VERSION "V6.0.0"

NS_ :

BS_:

BU_: OBD_Node CGW_PT POD BMS TCU APTC VCU MCU PRND EVCOM IBS_PT ADCU_PT

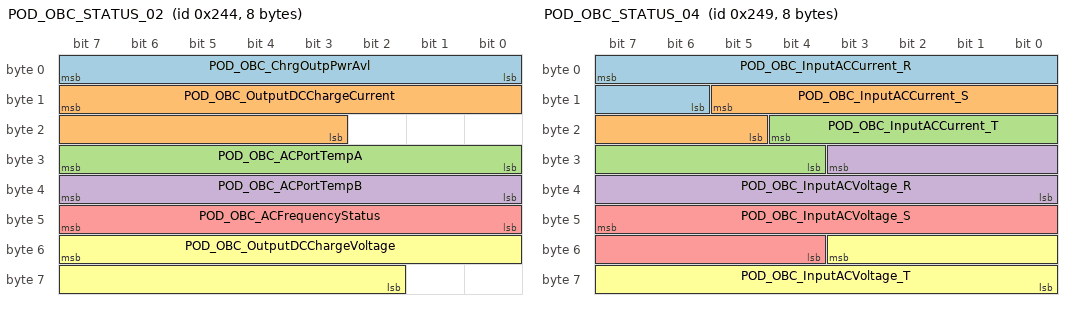
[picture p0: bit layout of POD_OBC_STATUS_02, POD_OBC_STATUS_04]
BO_ 580 POD_OBC_STATUS_02: 8 POD
 SG_ POD_OBC_ChrgOutpPwrAvl : 7|8@0+ (0.1,-7) [-7|13] "kW"  VCU,CGW_PT
 SG_ POD_OBC_OutputDCChargeCurrent : 15|13@0+ (0.1,-250) [-250|250] "A"  VCU,CGW_PT
 SG_ POD_OBC_ACPortTempA : 31|8@0+ (1,-40) [-40|215] "celsius"  CGW_PT
 SG_ POD_OBC_ACPortTempB : 39|8@0+ (1,-40) [-40|215] "celsius"  CGW_PT
 SG_ POD_OBC_ACFrequencyStatus : 47|8@0+ (1,0) [0|255] "Hz"  CGW_PT
 SG_ POD_OBC_OutputDCChargeVoltage : 55|14@0+ (0.1,-800) [-800|800] "V"  VCU,CGW_PT

BO_ 787 POD_OBC_STATUS_03: 8 POD
 SG_ POD_OBC_ACPortTempASensValid : 7|2@0+ (1,0) [0|2] ""  CGW_PT
 SG_ POD_OBC_ACPortTempBSensValid : 5|2@0+ (1,0) [0|2] ""  CGW_PT
 SG_ POD_OBC_ACPortTempAerror : 3|1@0+ (1,0) [0|1] ""  CGW_PT
 SG_ POD_OBC_ACPortTempBerror : 2|1@0+ (1,0) [0|1] ""  CGW_PT
 SG_ POD_OBC_FaultLevel : 1|2@0+ (1,0) [0|3] ""  VCU,CGW_PT
 SG_ POD_OBC_DCVoltHighFault : 15|1@0+ (1,0) [0|1] ""  CGW_PT
 SG_ POD_OBC_StartUpAllowed : 14|1@0+ (1,0) [0|1] ""  CGW_PT
 SG_ POD_OBC_CommunFault : 13|1@0+ (1,0) [0|1] ""  CGW_PT
 SG_ POD_OBC_DCCurHighFault : 12|1@0+ (1,0) [0|1] ""  CGW_PT
 SG_ POD_OBC_ACVoltHighFault : 11|1@0+ (1,0) [0|1] ""  CGW_PT
 SG_ POD_OBC_ACVoltLowFault : 10|1@0+ (1,0) [0|1] ""  CGW_PT
 SG_ POD_OBC_NlineStatus : 9|1@0+ (1,0) [0|1] ""  CGW_PT
 SG_ POD_OBC_OutputoverloadFault : 8|1@0+ (1,0) [0|1] ""  CGW_PT
 SG_ POD_OBC_InputFrequencyStatus : 23|1@0+ (1,0) [0|1] ""  CGW_PT
 SG_ POD_OBC_InputPhaseStatus : 22|1@0+ (1,0) [0|1] ""  CGW_PT
 SG_ POD_OBC_InputOverCurrentstatus_R : 21|1@0+ (1,0) [0|1] ""  CGW_PT
 SG_ POD_OBC_InputOverCurrentstatus_S : 20|1@0+ (1,0) [0|1] ""  CGW_PT
 SG_ POD_OBC_InputOverCurrentstatus_T : 19|1@0+ (1,0) [0|1] ""  CGW_PT
 SG_ POD_OBC_PFCUnderVoltageError : 18|1@0+ (1,0) [0|1] ""  CGW_PT
 SG_ POD_OBC_PFCOverVoltageError : 17|1@0+ (1,0) [0|1] ""  CGW_PT
 SG_ POD_OBC_OutputShortError : 16|1@0+ (1,0) [0|1] ""  CGW_PT
 SG_ POD_OBC_Side1Overtempfault : 31|1@0+ (1,0) [0|1] ""  VCU,CGW_PT
 SG_ POD_OBC_Side2Overtempfault : 30|1@0+ (1,0) [0|1] ""  VCU,CGW_PT
 SG_ POD_OBC_InternalFault : 27|1@0+ (1,0) [0|1] ""  CGW_PT
 SG_ POD_OBC_DCVoltLowFault : 28|1@0+ (1,0) [0|1] ""  CGW_PT
 SG_ POD_OBC_InputShortError : 26|1@0+ (1,0) [0|1] ""  CGW_PT
 SG_ POD_DCDC_CommunFault : 25|1@0+ (1,0) [0|1] ""  CGW_PT
 SG_ OBC_OutputIsolatedFault : 24|1@0+ (1,0) [0|1] ""  CGW_PT
 SG_ POD_OBC_PrimarySideTemp : 39|8@0+ (1,-40) [-40|210] "celsius"  TCU,VCU,CGW_PT
 SG_ POD_OBC_SecondarySideTemp : 47|8@0+ (1,-40) [-40|210] "celsius"  TCU,VCU,CGW_PT

BO_ 585 POD_OBC_STATUS_04: 8 POD
 SG_ POD_OBC_InputACCurrent_R : 7|10@0+ (0.1,-50) [-50|50] ""  VCU,CGW_PT
 SG_ POD_OBC_InputACCurrent_S : 13|9@0+ (0.1,0) [0|50] ""  VCU,CGW_PT
 SG_ POD_OBC_InputACCurrent_T : 20|9@0+ (0.1,0) [0|50] ""  VCU,CGW_PT
 SG_ POD_OBC_InputACVoltage_R : 27|12@0+ (0.1,0) [0|400] ""  VCU,CGW_PT
 SG_ POD_OBC_InputACVoltage_S : 47|12@0+ (0.1,0) [0|400] "V"  VCU,CGW_PT
 SG_ POD_OBC_InputACVoltage_T : 51|12@0+ (0.1,0) [0|400] "V"  VCU,CGW_PT

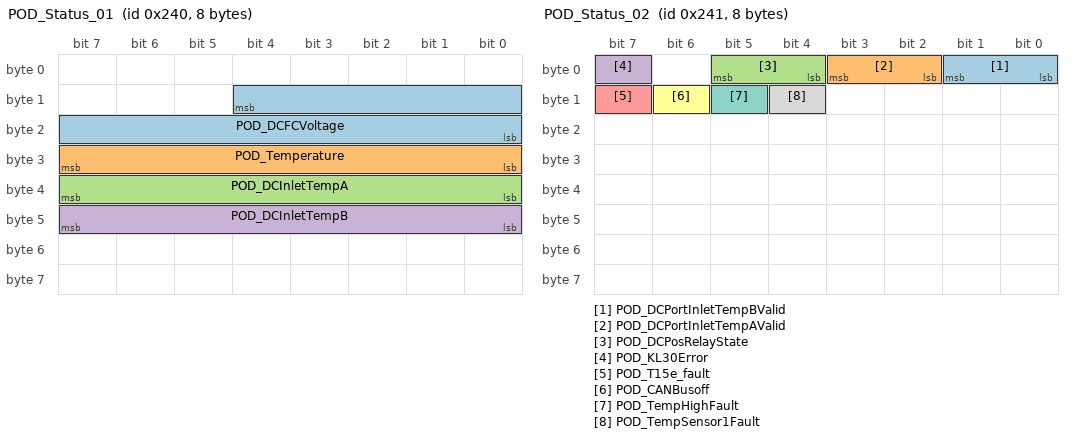
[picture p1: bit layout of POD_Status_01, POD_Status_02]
BO_ 576 POD_Status_01: 8 POD
 SG_ POD_DCFCVoltage : 12|13@0+ (0.1,0) [0|819] "V"  VCU,CGW_PT
 SG_ POD_Temperature : 31|8@0+ (1,-40) [-40|215] "celsius"  TCU,CGW_PT
 SG_ POD_DCInletTempA : 39|8@0+ (1,-40) [-40|215] "celsius"  VCU,CGW_PT
 SG_ POD_DCInletTempB : 47|8@0+ (1,-40) [-40|215] "celsius"  VCU,CGW_PT

BO_ 577 POD_Status_02: 8 POD
 SG_ POD_DCPortInletTempBValid : 1|2@0+ (1,0) [0|2] ""  VCU,CGW_PT
 SG_ POD_DCPortInletTempAValid : 3|2@0+ (1,0) [0|2] ""  VCU,CGW_PT
 SG_ POD_DCPosRelayState : 5|2@0+ (1,0) [0|2] ""  VCU,CGW_PT
 SG_ POD_KL30Error : 7|1@0+ (1,0) [0|1] ""  CGW_PT
 SG_ POD_T15e_fault : 15|1@0+ (1,0) [0|1] ""  CGW_PT
 SG_ POD_CANBusoff : 14|1@0+ (1,0) [0|1] ""  CGW_PT
 SG_ POD_TempHighFault : 13|1@0+ (1,0) [0|1] ""  CGW_PT
 SG_ POD_TempSensor1Fault : 12|1@0+ (1,0) [0|1] ""  CGW_PT

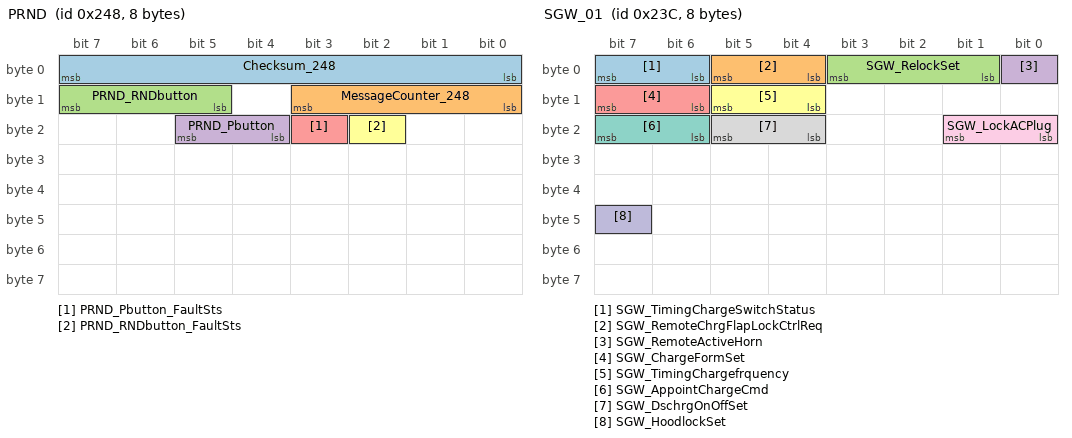
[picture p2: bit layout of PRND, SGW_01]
BO_ 584 PRND: 8 PRND
 SG_ Checksum_248 : 7|8@0+ (1,0) [0|255] ""  VCU,IBS_PT,CGW_PT
 SG_ MessageCounter_248 : 11|4@0+ (1,0) [0|15] ""  VCU,IBS_PT,CGW_PT
 SG_ PRND_RNDbutton : 15|3@0+ (1,0) [0|7] ""  VCU,CGW_PT
 SG_ PRND_Pbutton : 21|2@0+ (1,0) [0|3] ""  VCU,IBS_PT,CGW_PT
 SG_ PRND_Pbutton_FaultSts : 19|1@0+ (1,0) [0|1] ""  VCU,IBS_PT,CGW_PT
 SG_ PRND_RNDbutton_FaultSts : 18|1@0+ (1,0) [0|1] ""  VCU,CGW_PT

BO_ 572 SGW_01: 8 CGW_PT
 SG_ SGW_TimingChargeSwitchStatus : 7|2@0+ (1,0) [0|2] ""  VCU,BMS
 SG_ SGW_RemoteChrgFlapLockCtrlReq : 5|2@0+ (1,0) [0|3] "" Vector__XXX
 SG_ SGW_RelockSet : 3|3@0+ (1,0) [0|5] "" Vector__XXX
 SG_ SGW_RemoteActiveHorn : 0|1@0+ (1,0) [0|1] "" Vector__XXX
 SG_ SGW_ChargeFormSet : 15|2@0+ (1,0) [0|2] ""  VCU
 SG_ SGW_TimingChargefrquency : 13|2@0+ (1,0) [0|2] "" Vector__XXX
 SG_ SGW_AppointChargeCmd : 23|2@0+ (1,0) [0|2] ""  VCU
 SG_ SGW_DschrgOnOffSet : 21|2@0+ (1,0) [0|3] ""  VCU
 SG_ SGW_LockACPlug : 17|2@0+ (1,0) [0|2] ""  VCU
 SG_ SGW_HoodlockSet : 47|1@0+ (1,0) [0|1] "" Vector__XXX

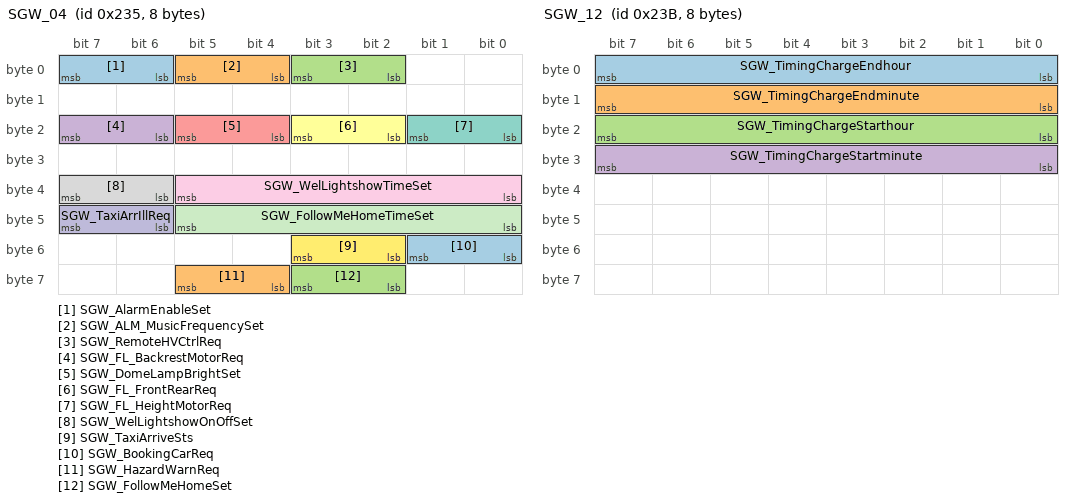
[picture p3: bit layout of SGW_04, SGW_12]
BO_ 565 SGW_04: 8 CGW_PT
 SG_ SGW_AlarmEnableSet : 7|2@0+ (1,0) [0|2] "" Vector__XXX
 SG_ SGW_ALM_MusicFrequencySet : 5|2@0+ (1,0) [0|3] "" Vector__XXX
 SG_ SGW_RemoteHVCtrlReq : 3|2@0+ (1,0) [0|2] ""  VCU
 SG_ SGW_FL_BackrestMotorReq : 23|2@0+ (1,0) [0|2] "" Vector__XXX
 SG_ SGW_DomeLampBrightSet : 21|2@0+ (1,0) [0|2] "" Vector__XXX
 SG_ SGW_FL_FrontRearReq : 19|2@0+ (1,0) [0|2] "" Vector__XXX
 SG_ SGW_FL_HeightMotorReq : 17|2@0+ (1,0) [0|2] "" Vector__XXX
 SG_ SGW_WelLightshowOnOffSet : 39|2@0+ (1,0) [0|3] "" Vector__XXX
 SG_ SGW_WelLightshowTimeSet : 37|6@0+ (5,5) [5|180] "s" Vector__XXX
 SG_ SGW_TaxiArrIllReq : 47|2@0+ (1,0) [0|3] "" Vector__XXX
 SG_ SGW_FollowMeHomeTimeSet : 45|6@0+ (5,5) [5|180] "s" Vector__XXX
 SG_ SGW_TaxiArriveSts : 51|2@0+ (1,0) [0|2] "" Vector__XXX
 SG_ SGW_BookingCarReq : 49|2@0+ (1,0) [0|2] "" Vector__XXX
 SG_ SGW_HazardWarnReq : 61|2@0+ (1,0) [0|2] "" Vector__XXX
 SG_ SGW_FollowMeHomeSet : 59|2@0+ (1,0) [0|3] "" Vector__XXX

BO_ 571 SGW_12: 8 CGW_PT
 SG_ SGW_TimingChargeEndhour : 7|8@0+ (1,0) [0|31] "h"  BMS
 SG_ SGW_TimingChargeEndminute : 15|8@0+ (1,0) [0|63] "min"  BMS
 SG_ SGW_TimingChargeStarthour : 23|8@0+ (1,0) [0|31] "h" Vector__XXX
 SG_ SGW_TimingChargeStartminute : 31|8@0+ (1,0) [0|63] "min" Vector__XXX

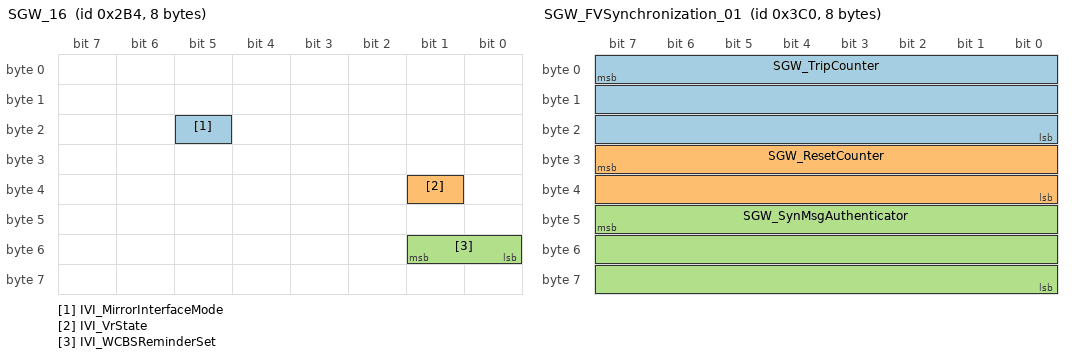
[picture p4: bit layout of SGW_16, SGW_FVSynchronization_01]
BO_ 692 SGW_16: 8 CGW_PT
 SG_ IVI_MirrorInterfaceMode : 21|1@0+ (1,0) [0|1] "" Vector__XXX
 SG_ IVI_VrState : 33|1@0+ (1,0) [0|1] ""  VCU
 SG_ IVI_WCBSReminderSet : 49|2@0+ (1,0) [0|2] "" Vector__XXX

BO_ 960 SGW_FVSynchronization_01: 8 CGW_PT
 SG_ SGW_TripCounter : 7|24@0+ (1,0) [0|16777215] ""  VCU
 SG_ SGW_ResetCounter : 31|16@0+ (1,0) [0|65535] ""  VCU
 SG_ SGW_SynMsgAuthenticator : 47|24@0+ (1,0) [0|16777215] ""  VCU

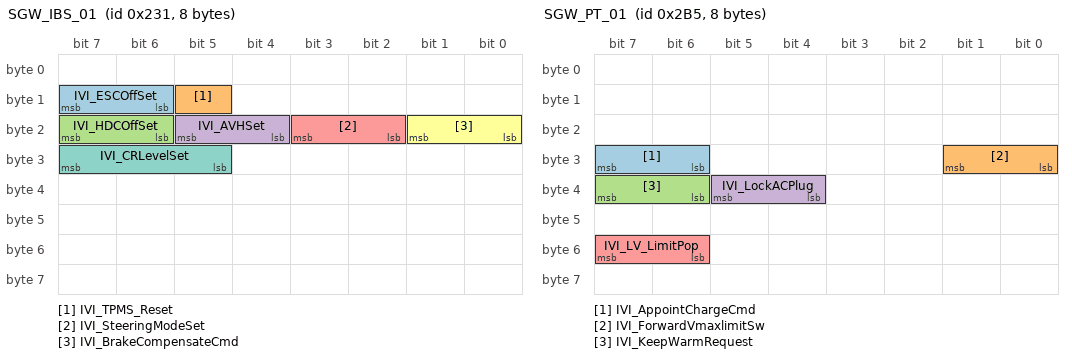
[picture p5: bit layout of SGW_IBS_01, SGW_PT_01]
BO_ 561 SGW_IBS_01: 8 CGW_PT
 SG_ IVI_ESCOffSet : 15|2@0+ (1,0) [0|3] "" Vector__XXX
 SG_ IVI_TPMS_Reset : 13|1@0+ (1,0) [0|1] "" Vector__XXX
 SG_ IVI_HDCOffSet : 23|2@0+ (1,0) [0|3] "" Vector__XXX
 SG_ IVI_AVHSet : 21|2@0+ (1,0) [0|3] "" Vector__XXX
 SG_ IVI_SteeringModeSet : 19|2@0+ (1,0) [0|3] "" Vector__XXX
 SG_ IVI_BrakeCompensateCmd : 17|2@0+ (1,0) [0|3] ""  VCU
 SG_ IVI_CRLevelSet : 31|3@0+ (1,0) [0|7] ""  VCU

BO_ 944 IVI_OdometerInfor: 8 CGW_PT
 SG_ IVI_OdometerInfor : 7|24@0+ (0.1,0) [0|999999.9] "km"  TCU,APTC,VCU,MCU,PRND,EVCOM,POD,BMS
 SG_ IVI_OdometerInforValid : 31|1@0+ (1,0) [0|1] "" Vector__XXX

BO_ 693 SGW_PT_01: 8 CGW_PT
 SG_ IVI_AppointChargeCmd : 31|2@0+ (1,0) [0|2] ""  VCU
 SG_ IVI_ForwardVmaxlimitSw : 25|2@0+ (1,0) [0|3] ""  VCU
 SG_ IVI_KeepWarmRequest : 39|2@0+ (1,0) [0|2] ""  BMS
 SG_ IVI_LockACPlug : 37|2@0+ (1,0) [0|2] ""  VCU
 SG_ IVI_LV_LimitPop : 55|2@0+ (1,0) [0|2] ""  VCU

BO_ 694 IVI_01: 8 CGW_PT
 SG_ IVI_GearRequest : 15|3@0+ (1,0) [0|5] ""  VCU

BO_ 261 SGW_RemoteCmd_01: 8 CGW_PT
 SG_ SGW_RemoteAirCondOnOFFReq : 15|2@0+ (1,0) [0|3] ""  TCU
 SG_ SGW_RemoteAirCondAUTOReq : 13|2@0+ (1,0) [0|3] ""  TCU
 SG_ SGW_RemoteFrontDefrostReq : 23|2@0+ (1,0) [0|3] ""  TCU
 SG_ SGW_FrontDoorAngleSet : 21|2@0+ (1,0) [0|2] "" Vector__XXX
 SG_ SGW_RearDoorAngleSet : 19|2@0+ (1,0) [0|2] "" Vector__XXX
 SG_ SGW_RemoteDrSeatHeatReq : 28|3@0+ (1,0) [0|4] "" Vector__XXX
 SG_ SGW_RemoteSteerHeatReq : 25|2@0+ (1,0) [0|3] "" Vector__XXX
 SG_ SGW_RemotePassSeatHeatReq : 39|3@0+ (1,0) [0|4] "" Vector__XXX
 SG_ SGW_RearDefrostCtrlSet : 32|1@0+ (1,0) [0|1] "" Vector__XXX
 SG_ SGW_RemoteRearMirHeatReq : 36|2@0+ (1,0) [0|3] "" Vector__XXX
 SG_ SGW_RemoteFrontWindHeatReq : 34|2@0+ (1,0) [0|3] "" Vector__XXX
 SG_ SGW_RemoteRearWindHeatReq : 47|2@0+ (1,0) [0|3] "" Vector__XXX
 SG_ SGW_oneTouchCoolSet : 43|2@0+ (1,0) [0|2] "" Vector__XXX
 SG_ SGW_TakePicCtrl : 51|3@0+ (1,0) [0|7] "" Vector__XXX
 SG_ SGW_RemoteTailgateLockCtrlReq : 63|2@0+ (1,0) [0|3] "" Vector__XXX
 SG_ SGW_RemoteACOnOffReq : 57|2@0+ (1,0) [0|2] ""  TCU
 SG_ SGW_LeftChdLockCtrlReq : 31|2@0+ (1,0) [0|2] "" Vector__XXX
 SG_ SGW_RightChdLockCtrlReq : 59|2@0+ (1,0) [0|2] "" Vector__XXX

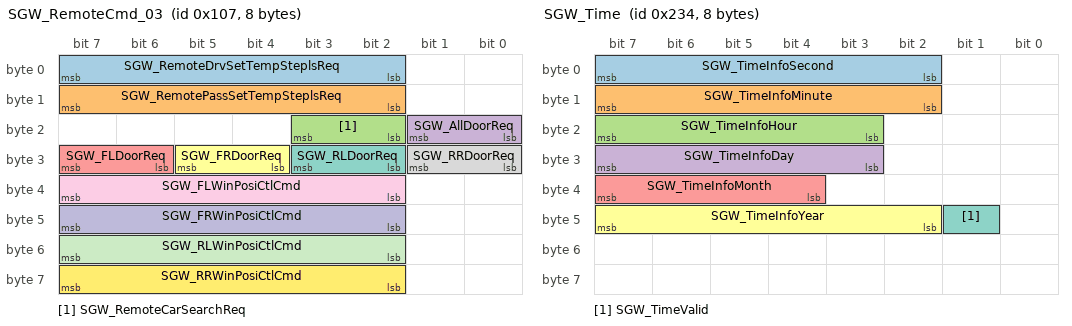
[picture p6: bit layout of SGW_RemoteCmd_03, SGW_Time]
BO_ 263 SGW_RemoteCmd_03: 8 CGW_PT
 SG_ SGW_RemoteDrvSetTempSteplsReq : 7|6@0+ (1,0) [0|63] ""  TCU
 SG_ SGW_RemotePassSetTempSteplsReq : 15|6@0+ (1,0) [0|63] ""  TCU
 SG_ SGW_RemoteCarSearchReq : 19|2@0+ (1,0) [0|3] "" Vector__XXX
 SG_ SGW_AllDoorReq : 17|2@0+ (1,0) [0|2] "" Vector__XXX
 SG_ SGW_FLDoorReq : 31|2@0+ (1,0) [0|2] "" Vector__XXX
 SG_ SGW_FRDoorReq : 29|2@0+ (1,0) [0|2] "" Vector__XXX
 SG_ SGW_RLDoorReq : 27|2@0+ (1,0) [0|2] "" Vector__XXX
 SG_ SGW_RRDoorReq : 25|2@0+ (1,0) [0|2] "" Vector__XXX
 SG_ SGW_FLWinPosiCtlCmd : 39|6@0+ (1,0) [0|21] "" Vector__XXX
 SG_ SGW_FRWinPosiCtlCmd : 47|6@0+ (1,0) [0|21] "" Vector__XXX
 SG_ SGW_RLWinPosiCtlCmd : 55|6@0+ (1,0) [0|21] "" Vector__XXX
 SG_ SGW_RRWinPosiCtlCmd : 63|6@0+ (1,0) [0|21] "" Vector__XXX

BO_ 562 SGW_TCU_01: 8 CGW_PT
 SG_ SGW_DrvSetTempSteplsReq : 7|6@0+ (1,0) [0|63] ""  TCU
 SG_ SGW_DemistReq : 1|2@0+ (1,0) [0|3] ""  TCU
 SG_ SGW_HVACBatterySaveModeSetReq : 15|2@0+ (1,0) [0|3] ""  TCU
 SG_ SGW_PassSetTempSteplsReq : 13|6@0+ (1,0) [0|63] ""  TCU
 SG_ SGW_AirCondAUTOReq : 23|2@0+ (1,0) [0|3] ""  TCU
 SG_ SGW_DualReq : 21|2@0+ (1,0) [0|3] ""  TCU
 SG_ SGW_AirDistributionModeReq : 19|3@0+ (1,0) [0|7] ""  TCU
 SG_ SGW_FrontDefrostReq : 16|2@0+ (1,0) [0|3] ""  TCU
 SG_ SGW_AqsReq : 39|2@0+ (1,0) [0|3] ""  TCU
 SG_ SGW_ClimateSystemStsReq : 35|2@0+ (1,0) [0|3] ""  TCU
 SG_ SGW_ACCmprStsReq : 33|2@0+ (1,0) [0|3] ""  TCU
 SG_ SGW_AirCirclnReq : 47|2@0+ (1,0) [0|3] ""  TCU
 SG_ SGW_BlowersteplsSpdReq : 43|4@0+ (1,0) [0|15] ""  TCU
 SG_ SGW_PresetModeEnable : 55|2@0+ (1,0) [0|2] ""  TCU
 SG_ SGW_PresetModeReq : 53|3@0+ (1,0) [0|7] ""  TCU
 SG_ SGW_VentilationModeReq : 50|2@0+ (1,0) [0|2] ""  TCU
 SG_ SGW_AirCondEcoSet : 60|2@0+ (1,0) [0|3] ""  TCU

BO_ 564 SGW_Time: 8 CGW_PT
 SG_ SGW_TimeInfoSecond : 7|6@0+ (1,0) [0|59] ""  TCU,APTC,VCU,MCU,PRND,EVCOM,POD,BMS
 SG_ SGW_TimeInfoMinute : 15|6@0+ (1,0) [0|59] ""  TCU,APTC,VCU,MCU,PRND,EVCOM,POD,BMS
 SG_ SGW_TimeInfoHour : 23|5@0+ (1,0) [0|23] ""  TCU,APTC,VCU,MCU,PRND,EVCOM,POD,BMS
 SG_ SGW_TimeInfoDay : 31|5@0+ (1,0) [1|31] ""  TCU,APTC,VCU,MCU,PRND,EVCOM,POD,BMS
 SG_ SGW_TimeInfoMonth : 39|4@0+ (1,0) [1|12] ""  TCU,APTC,VCU,MCU,PRND,EVCOM,POD,BMS
 SG_ SGW_TimeInfoYear : 47|6@0+ (1,2000) [2000|2059] ""  TCU,APTC,VCU,MCU,PRND,EVCOM,POD,BMS
 SG_ SGW_TimeValid : 41|1@0+ (1,0) [0|1] ""  TCU,APTC,VCU,MCU,PRND,EVCOM,POD,BMS

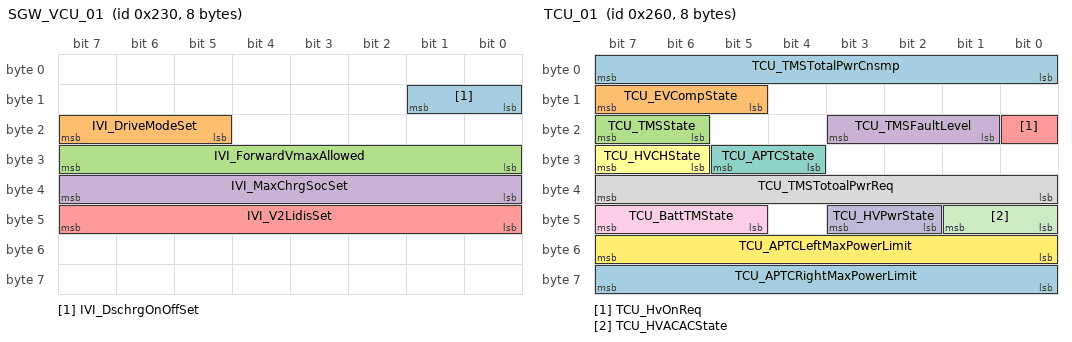
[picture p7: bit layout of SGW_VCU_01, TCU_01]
BO_ 560 SGW_VCU_01: 8 CGW_PT
 SG_ IVI_DschrgOnOffSet : 9|2@0+ (1,0) [0|3] ""  VCU
 SG_ IVI_DriveModeSet : 23|3@0+ (1,0) [0|4] ""  VCU
 SG_ IVI_ForwardVmaxAllowed : 31|8@0+ (1,0) [0|175] ""  VCU
 SG_ IVI_MaxChrgSocSet : 39|8@0+ (1,0) [0|100] "percent"  VCU
 SG_ IVI_V2LidisSet : 47|8@0+ (1,0) [0|100] "percent"  VCU

BO_ 608 TCU_01: 8 TCU
 SG_ TCU_TMSTotalPwrCnsmp : 7|8@0+ (200,0) [0|40000] "w"  VCU,CGW_PT
 SG_ TCU_EVCompState : 15|3@0+ (1,0) [0|7] ""  CGW_PT
 SG_ TCU_TMSState : 23|2@0+ (1,0) [0|2] ""  CGW_PT
 SG_ TCU_TMSFaultLevel : 19|3@0+ (1,0) [0|7] ""  VCU,CGW_PT
 SG_ TCU_HvOnReq : 16|1@0+ (1,0) [0|1] ""  CGW_PT
 SG_ TCU_HVCHState : 31|2@0+ (1,0) [0|3] ""  CGW_PT
 SG_ TCU_APTCState : 29|2@0+ (1,0) [0|3] ""  CGW_PT
 SG_ TCU_TMSTotoalPwrReq : 39|8@0+ (200,0) [0|40000] "w"  VCU,CGW_PT
 SG_ TCU_BattTMState : 47|3@0+ (1,0) [0|7] ""  CGW_PT
 SG_ TCU_HVPwrState : 43|2@0+ (1,0) [0|3] ""  VCU,CGW_PT
 SG_ TCU_HVACACState : 41|2@0+ (1,0) [0|3] ""  CGW_PT
 SG_ TCU_APTCLeftMaxPowerLimit : 55|8@0+ (0.04,0) [0|10.2] "KW"  APTC,CGW_PT
 SG_ TCU_APTCRightMaxPowerLimit : 63|8@0+ (0.04,0) [0|10.2] "KW"  APTC,CGW_PT

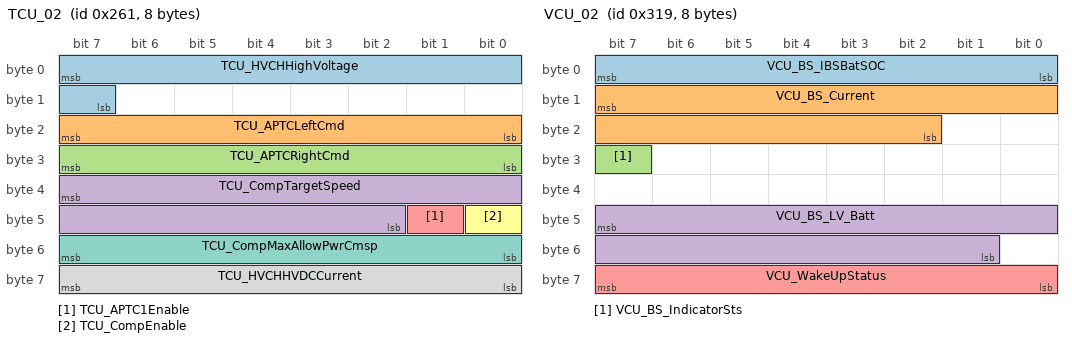
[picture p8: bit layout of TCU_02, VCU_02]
BO_ 609 TCU_02: 8 TCU
 SG_ TCU_HVCHHighVoltage : 7|9@0+ (1,0) [0|508] "V"  VCU,CGW_PT
 SG_ TCU_APTCLeftCmd : 23|8@0+ (1,0) [0|100] "percent"  APTC,CGW_PT
 SG_ TCU_APTCRightCmd : 31|8@0+ (1,0) [0|100] "percent"  APTC,CGW_PT
 SG_ TCU_CompTargetSpeed : 39|14@0+ (1,0) [0|9200] "rpm"  EVCOM,CGW_PT
 SG_ TCU_APTC1Enable : 41|1@0+ (1,0) [0|1] ""  APTC,CGW_PT
 SG_ TCU_CompEnable : 40|1@0+ (1,0) [0|1] ""  EVCOM,CGW_PT
 SG_ TCU_CompMaxAllowPwrCmsp : 55|8@0+ (0.04,0) [0|10.16] "KW"  EVCOM,CGW_PT
 SG_ TCU_HVCHHVDCCurrent : 63|8@0+ (0.25,0) [0|63.5] "A"  VCU,CGW_PT

BO_ 610 TCU_03: 8 TCU
 SG_ TCU_CabinTemperature : 23|8@0+ (1,-50) [-50|205] "celsius"  CGW_PT
 SG_ TCU_CabinTemperatureValid : 31|1@0+ (1,0) [0|1] ""  CGW_PT

BO_ 768 TCU_IVI: 8 TCU
 SG_ TCU_FrontDefrostSts : 2|1@0+ (1,0) [0|1] ""  CGW_PT
 SG_ TCU_AirCondAUTOSts : 3|1@0+ (1,0) [0|1] ""  CGW_PT
 SG_ TCU_AirCirclnSts : 5|2@0+ (1,0) [0|2] ""  CGW_PT
 SG_ TCU_AirCondEcoSetSts : 8|1@0+ (1,0) [0|1] ""  CGW_PT
 SG_ TCU_SelfDryingSetSts : 9|1@0+ (1,0) [0|1] ""  CGW_PT
 SG_ TCU_DrvTempSts : 15|6@0+ (1,0) [0|63] ""  CGW_PT
 SG_ TCU_AqsSts : 16|1@0+ (1,0) [0|1] ""  CGW_PT
 SG_ TCU_DualSts : 17|1@0+ (1,0) [0|1] ""  CGW_PT
 SG_ TCU_PassTempSts : 23|6@0+ (1,0) [0|63] ""  CGW_PT
 SG_ TCU_CoolantLowWarnReq : 25|2@0+ (1,0) [0|3] ""  CGW_PT
 SG_ TCU_FreonLowWarnReq : 27|2@0+ (1,0) [0|3] ""  CGW_PT
 SG_ TCU_BlowerSpdSts : 31|4@0+ (1,0) [0|15] ""  CGW_PT
 SG_ TCU_AirDistributionModeSts : 39|3@0+ (1,0) [0|7] ""  CGW_PT
 SG_ TCU_PresetModeSts : 35|3@0+ (1,0) [0|7] ""  CGW_PT
 SG_ TCU_VentilationModeSts : 32|1@0+ (1,0) [0|1] ""  CGW_PT
 SG_ TCU_HVACBatterySaveSts : 40|1@0+ (1,0) [0|1] ""  CGW_PT
 SG_ TCU_HVACBatterySaveModeSetSts : 41|1@0+ (1,0) [0|1] ""  CGW_PT
 SG_ TCU_ACCmprSts : 42|1@0+ (1,0) [0|1] ""  CGW_PT
 SG_ TCU_ClimateSystemSts : 43|1@0+ (1,0) [0|1] ""  CGW_PT
 SG_ TCU_PowerLimitSts : 44|1@0+ (1,0) [0|1] ""  CGW_PT
 SG_ TCU_OutsideAQSLevel : 47|3@0+ (1,0) [0|7] ""  CGW_PT
 SG_ TCU_WindowClosRemind : 50|1@0+ (1,0) [0|1] ""  CGW_PT
 SG_ TCU_DemistSts : 51|1@0+ (1,0) [0|1] ""  CGW_PT

BO_ 793 VCU_02: 8 VCU
 SG_ VCU_BS_IBSBatSOC : 7|8@0+ (1,0) [0|100] "percent"  TCU,CGW_PT
 SG_ VCU_BS_Current : 15|14@0+ (0.001,-8.192) [-8.192|8.191] ""  CGW_PT
 SG_ VCU_BS_IndicatorSts : 31|1@0+ (1,0) [0|1] ""  CGW_PT
 SG_ VCU_BS_LV_Batt : 47|15@0+ (0.001,0) [0|32.767] "V"  TCU,APTC,MCU,PRND,EVCOM,ADCU_PT,CGW_PT,POD,BMS
 SG_ VCU_WakeUpStatus : 63|8@0+ (1,0) [0|255] ""  CGW_PT

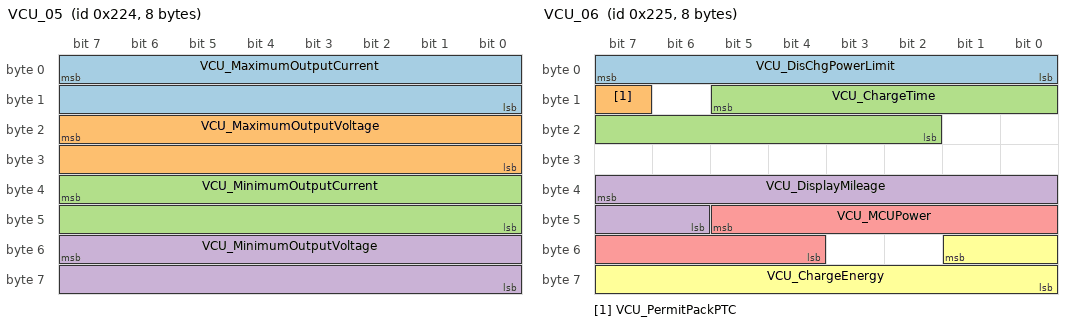
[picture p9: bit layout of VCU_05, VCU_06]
BO_ 548 VCU_05: 8 VCU
 SG_ VCU_MaximumOutputCurrent : 7|16@0+ (0.1,-400) [-400|0] "A"  BMS
 SG_ VCU_MaximumOutputVoltage : 23|16@0+ (0.1,0) [0|750] "V"  BMS
 SG_ VCU_MinimumOutputCurrent : 39|16@0+ (0.1,-400) [-400|0] "A"  BMS
 SG_ VCU_MinimumOutputVoltage : 55|16@0+ (0.1,0) [0|750] "V"  BMS

BO_ 549 VCU_06: 8 VCU
 SG_ VCU_DisChgPowerLimit : 7|8@0+ (0.1,0) [0|25.5] "kW"  CGW_PT,POD
 SG_ VCU_PermitPackPTC : 15|1@0+ (1,0) [0|1] ""  CGW_PT,BMS
 SG_ VCU_ChargeTime : 13|12@0+ (1,0) [0|4095] "min"  CGW_PT
 SG_ VCU_DisplayMileage : 39|10@0+ (1,0) [0|1023] "km"  CGW_PT
 SG_ VCU_MCUPower : 45|10@0+ (1,-400) [-400|623] "kW"  CGW_PT
 SG_ VCU_ChargeEnergy : 49|10@0+ (0.1,0) [0|102.3] "km/h"  CGW_PT

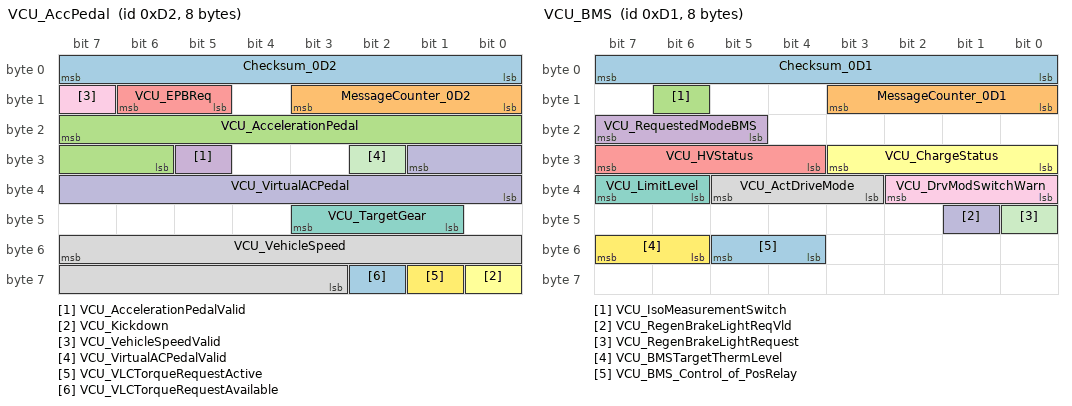
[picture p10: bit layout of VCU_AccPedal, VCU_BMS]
BO_ 210 VCU_AccPedal: 8 VCU
 SG_ Checksum_0D2 : 7|8@0+ (1,0) [0|255] ""  IBS_PT
 SG_ MessageCounter_0D2 : 11|4@0+ (1,0) [0|15] ""  IBS_PT
 SG_ VCU_AccelerationPedal : 23|10@0+ (0.1,0) [0|100] "percent" Vector__XXX
 SG_ VCU_AccelerationPedalValid : 29|1@0+ (1,0) [0|1] "" Vector__XXX
 SG_ VCU_EPBReq : 14|2@0+ (1,0) [0|3] ""  IBS_PT
 SG_ VCU_Kickdown : 56|1@0+ (1,0) [0|1] "" Vector__XXX
 SG_ VCU_TargetGear : 43|3@0+ (1,0) [0|4] "" Vector__XXX
 SG_ VCU_VehicleSpeed : 55|13@0+ (0.05625,0) [0|360] "km/h"  TCU
 SG_ VCU_VehicleSpeedValid : 15|1@0+ (1,0) [0|1] ""  TCU
 SG_ VCU_VirtualACPedal : 25|10@0+ (0.1,0) [0|100] "percent" Vector__XXX
 SG_ VCU_VirtualACPedalValid : 26|1@0+ (1,0) [0|1] "" Vector__XXX
 SG_ VCU_VLCTorqueRequestActive : 57|1@0+ (1,0) [0|1] "" Vector__XXX
 SG_ VCU_VLCTorqueRequestAvailable : 58|1@0+ (1,0) [0|1] "" Vector__XXX

BO_ 209 VCU_BMS: 8 VCU
 SG_ Checksum_0D1 : 7|8@0+ (1,0) [0|255] ""  MCU,PRND,ADCU_PT,CGW_PT,BMS
 SG_ MessageCounter_0D1 : 11|4@0+ (1,0) [0|15] ""  MCU,PRND,ADCU_PT,CGW_PT,BMS
 SG_ VCU_IsoMeasurementSwitch : 14|1@0+ (1,0) [0|1] ""  CGW_PT,BMS
 SG_ VCU_RequestedModeBMS : 23|3@0+ (1,0) [0|7] ""  CGW_PT,BMS
 SG_ VCU_HVStatus : 31|4@0+ (1,0) [0|5] ""  TCU,APTC,MCU,PRND,EVCOM,ADCU_PT,CGW_PT,POD,BMS
 SG_ VCU_ChargeStatus : 27|4@0+ (1,0) [0|14] ""  TCU,APTC,MCU,PRND,EVCOM,ADCU_PT,CGW_PT,POD,BMS
 SG_ VCU_LimitLevel : 39|2@0+ (1,0) [0|3] ""  TCU,CGW_PT
 SG_ VCU_ActDriveMode : 37|3@0+ (1,0) [0|4] ""  ADCU_PT,CGW_PT
 SG_ VCU_DrvModSwitchWarn : 34|3@0+ (1,0) [0|7] ""  CGW_PT
 SG_ VCU_RegenBrakeLightReqVld : 41|1@0+ (1,0) [0|1] ""  CGW_PT
 SG_ VCU_RegenBrakeLightRequest : 40|1@0+ (1,0) [0|1] ""  CGW_PT
 SG_ VCU_BMSTargetThermLevel : 55|2@0+ (1,0) [0|3] ""  CGW_PT,BMS
 SG_ VCU_BMS_Control_of_PosRelay : 53|2@0+ (1,0) [0|2] ""  CGW_PT,BMS

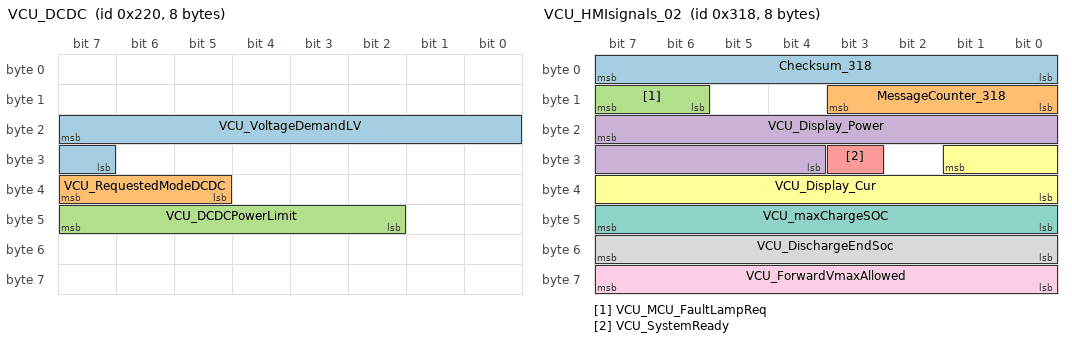
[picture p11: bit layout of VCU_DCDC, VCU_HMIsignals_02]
BO_ 544 VCU_DCDC: 8 VCU
 SG_ VCU_VoltageDemandLV : 23|9@0+ (0.125,0) [0|63.625] "V"  CGW_PT,POD
 SG_ VCU_RequestedModeDCDC : 39|3@0+ (1,0) [0|2] ""  CGW_PT,POD
 SG_ VCU_DCDCPowerLimit : 47|6@0+ (0.1,0) [0|6.3] "kW"  CGW_PT,POD

BO_ 792 VCU_HMIsignals_02: 8 VCU
 SG_ Checksum_318 : 7|8@0+ (1,0) [0|255] ""  BMS
 SG_ MessageCounter_318 : 11|4@0+ (1,0) [0|15] ""  BMS
 SG_ VCU_MCU_FaultLampReq : 15|2@0+ (1,0) [0|3] "" Vector__XXX
 SG_ VCU_Display_Power : 23|12@0+ (0.1,0) [0|409.5] "kW" Vector__XXX
 SG_ VCU_SystemReady : 27|1@0+ (1,0) [0|1] "" Vector__XXX
 SG_ VCU_Display_Cur : 25|10@0+ (1,0) [0|1023] "A" Vector__XXX
 SG_ VCU_maxChargeSOC : 47|8@0+ (1,0) [0|255] ""  BMS
 SG_ VCU_DischargeEndSoc : 55|8@0+ (1,0) [0|255] "percent" Vector__XXX
 SG_ VCU_ForwardVmaxAllowed : 63|8@0+ (1,0) [0|255] "" Vector__XXX

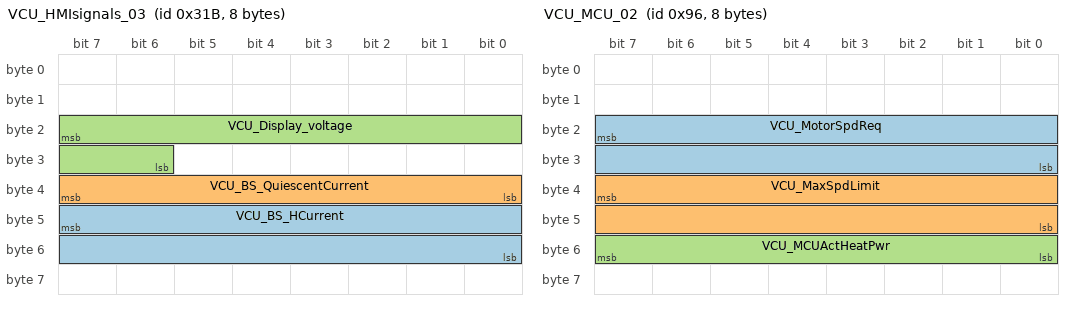
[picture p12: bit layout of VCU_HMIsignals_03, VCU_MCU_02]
BO_ 795 VCU_HMIsignals_03: 8 VCU
 SG_ VCU_BS_HCurrent : 47|16@0- (0.0625,-2048) [-1500|1500] "A"  CGW_PT
 SG_ VCU_BS_QuiescentCurrent : 39|8@0+ (0.00390625,0) [0|0.984375] "A"  CGW_PT
 SG_ VCU_Display_voltage : 23|10@0+ (1,0) [0|1023] "V"  CGW_PT

BO_ 150 VCU_MCU_02: 8 VCU
 SG_ VCU_MotorSpdReq : 23|16@0+ (1,-32767) [-32767|32767] ""  MCU,CGW_PT
 SG_ VCU_MaxSpdLimit : 39|16@0+ (1,-32767) [-32767|32767] ""  MCU,CGW_PT
 SG_ VCU_MCUActHeatPwr : 55|8@0+ (0.1,0) [0|10] "kW"  MCU,CGW_PT

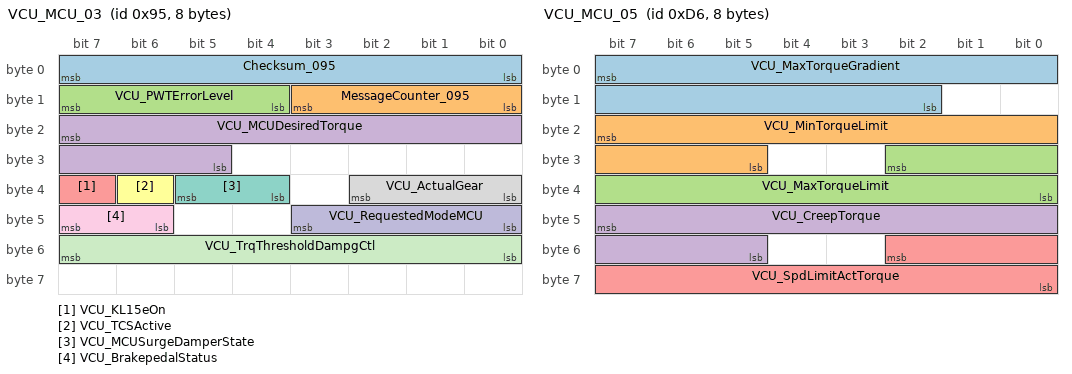
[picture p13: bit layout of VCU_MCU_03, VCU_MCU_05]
BO_ 149 VCU_MCU_03: 8 VCU
 SG_ Checksum_095 : 7|8@0+ (1,0) [0|255] ""  MCU,PRND,ADCU_PT,CGW_PT,BMS
 SG_ MessageCounter_095 : 11|4@0+ (1,0) [0|15] ""  MCU,PRND,ADCU_PT,CGW_PT,BMS
 SG_ VCU_PWTErrorLevel : 15|4@0+ (1,0) [0|15] ""  CGW_PT
 SG_ VCU_MCUDesiredTorque : 23|11@0+ (1,-1023) [-1023|1022] "Nm"  MCU,CGW_PT
 SG_ VCU_KL15eOn : 39|1@0+ (1,0) [0|1] ""  CGW_PT
 SG_ VCU_TCSActive : 38|1@0+ (1,0) [0|1] ""  MCU,CGW_PT
 SG_ VCU_MCUSurgeDamperState : 37|2@0+ (1,0) [0|2] "SED"  MCU,CGW_PT
 SG_ VCU_ActualGear : 34|3@0+ (1,0) [0|4] ""  TCU,APTC,MCU,PRND,EVCOM,ADCU_PT,CGW_PT,POD,BMS
 SG_ VCU_BrakepedalStatus : 47|2@0+ (1,0) [0|2] ""  MCU,CGW_PT
 SG_ VCU_RequestedModeMCU : 43|4@0+ (1,0) [0|4] ""  MCU,CGW_PT
 SG_ VCU_TrqThresholdDampgCtl : 55|8@0+ (0.1,0) [0|25] "Nm"  MCU,CGW_PT

BO_ 214 VCU_MCU_05: 8 VCU
 SG_ VCU_MaxTorqueGradient : 7|14@0+ (32,0) [0|524192] "Nm/s"  MCU,CGW_PT
 SG_ VCU_MinTorqueLimit : 23|11@0+ (1,-1023) [-1023|1022] "Nm"  MCU,CGW_PT
 SG_ VCU_MaxTorqueLimit : 26|11@0+ (1,-1023) [-1023|1022] "Nm"  MCU,CGW_PT
 SG_ VCU_CreepTorque : 47|11@0+ (1,-1024) [-1024|1023] ""  CGW_PT
 SG_ VCU_SpdLimitActTorque : 50|11@0+ (1,-1024) [-1024|1023] ""  CGW_PT

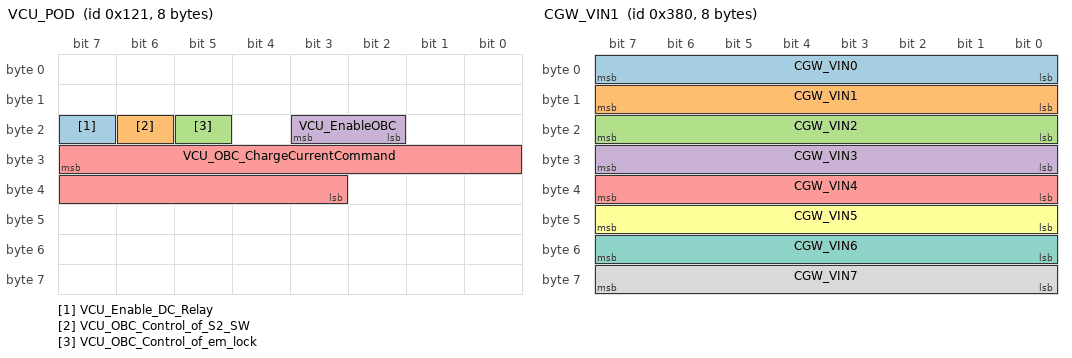
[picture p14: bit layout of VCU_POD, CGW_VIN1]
BO_ 289 VCU_POD: 8 VCU
 SG_ VCU_Enable_DC_Relay : 23|1@0+ (1,0) [0|1] ""  CGW_PT,POD
 SG_ VCU_OBC_Control_of_S2_SW : 22|1@0+ (1,0) [0|1] ""  CGW_PT,POD
 SG_ VCU_OBC_Control_of_em_lock : 21|1@0+ (1,0) [0|1] ""  CGW_PT,POD
 SG_ VCU_EnableOBC : 19|2@0+ (1,0) [0|3] ""  CGW_PT,POD
 SG_ VCU_OBC_ChargeCurrentCommand : 31|13@0+ (0.1,0) [0|500] "A"  CGW_PT,POD

BO_ 545 VCU_TCU: 8 VCU
 SG_ VCU_RequestedModeTCU : 15|2@0+ (1,0) [0|3] ""  TCU,CGW_PT
 SG_ VCU_TCUPowerAllowed : 13|13@0+ (40,0) [0|64000] "W"  TCU,CGW_PT

BO_ 319 VCU_SynReq_01: 8 VCU
 SG_ VCU_SynRequest : 7|24@0+ (1,0) [0|16777215] ""  CGW_PT

BO_ 896 CGW_VIN1: 8 CGW_PT
 SG_ CGW_VIN0 : 7|8@0+ (1,0) [0|255] ""  TCU,APTC,VCU,MCU,PRND,EVCOM,POD,BMS
 SG_ CGW_VIN1 : 15|8@0+ (1,0) [0|255] ""  TCU,APTC,VCU,MCU,PRND,EVCOM,POD,BMS
 SG_ CGW_VIN2 : 23|8@0+ (1,0) [0|255] ""  TCU,APTC,VCU,MCU,PRND,EVCOM,POD,BMS
 SG_ CGW_VIN3 : 31|8@0+ (1,0) [0|255] ""  TCU,APTC,VCU,MCU,PRND,EVCOM,POD,BMS
 SG_ CGW_VIN4 : 39|8@0+ (1,0) [0|255] ""  TCU,APTC,VCU,MCU,PRND,EVCOM,POD,BMS
 SG_ CGW_VIN5 : 47|8@0+ (1,0) [0|255] ""  TCU,APTC,VCU,MCU,PRND,EVCOM,POD,BMS
 SG_ CGW_VIN6 : 55|8@0+ (1,0) [0|255] ""  TCU,APTC,VCU,MCU,PRND,EVCOM,POD,BMS
 SG_ CGW_VIN7 : 63|8@0+ (1,0) [0|255] ""  TCU,APTC,VCU,MCU,PRND,EVCOM,POD,BMS

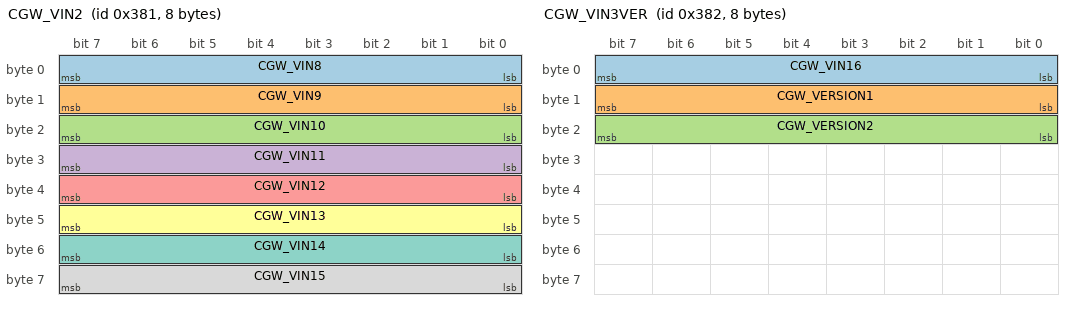
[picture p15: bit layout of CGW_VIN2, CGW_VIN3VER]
BO_ 897 CGW_VIN2: 8 CGW_PT
 SG_ CGW_VIN8 : 7|8@0+ (1,0) [0|255] ""  TCU,APTC,VCU,MCU,PRND,EVCOM,POD,BMS
 SG_ CGW_VIN9 : 15|8@0+ (1,0) [0|255] ""  TCU,APTC,VCU,MCU,PRND,EVCOM,POD,BMS
 SG_ CGW_VIN10 : 23|8@0+ (1,0) [0|255] ""  TCU,APTC,VCU,MCU,PRND,EVCOM,POD,BMS
 SG_ CGW_VIN11 : 31|8@0+ (1,0) [0|255] ""  TCU,APTC,VCU,MCU,PRND,EVCOM,POD,BMS
 SG_ CGW_VIN12 : 39|8@0+ (1,0) [0|255] ""  TCU,APTC,VCU,MCU,PRND,EVCOM,POD,BMS
 SG_ CGW_VIN13 : 47|8@0+ (1,0) [0|255] ""  TCU,APTC,VCU,MCU,PRND,EVCOM,POD,BMS
 SG_ CGW_VIN14 : 55|8@0+ (1,0) [0|255] ""  TCU,APTC,VCU,MCU,PRND,EVCOM,POD,BMS
 SG_ CGW_VIN15 : 63|8@0+ (1,0) [0|255] ""  TCU,APTC,VCU,MCU,PRND,EVCOM,POD,BMS

BO_ 898 CGW_VIN3VER: 8 CGW_PT
 SG_ CGW_VIN16 : 7|8@0+ (1,0) [0|255] ""  TCU,APTC,VCU,MCU,PRND,EVCOM,POD,BMS
 SG_ CGW_VERSION1 : 15|8@0+ (1,0) [0|5] ""  TCU,APTC,VCU,MCU,PRND,EVCOM,POD,BMS
 SG_ CGW_VERSION2 : 23|8@0+ (1,0) [0|255] ""  TCU,APTC,VCU,MCU,PRND,EVCOM,POD,BMS

BO_ 858 CGW_02: 8 CGW_PT
 SG_ CGW_SGWSts : 0|1@0+ (1,0) [0|1] ""  TCU,APTC,VCU,MCU,PRND,EVCOM,POD,BMS
 SG_ CGW_CGWSts : 1|1@0+ (1,0) [0|1] ""  TCU,APTC,VCU,MCU,PRND,EVCOM,POD,BMS
 SG_ CGW_CBMSts : 2|1@0+ (1,0) [0|1] ""  TCU,APTC,VCU,MCU,PRND,EVCOM,POD,BMS
 SG_ CGW_DCM_FLSts : 3|1@0+ (1,0) [0|1] ""  TCU,APTC,VCU,MCU,PRND,EVCOM,POD,BMS
 SG_ CGW_DCM_FRSts : 4|1@0+ (1,0) [0|1] ""  TCU,APTC,VCU,MCU,PRND,EVCOM,POD,BMS
 SG_ CGW_DCM_RLSts : 5|1@0+ (1,0) [0|1] ""  TCU,APTC,VCU,MCU,PRND,EVCOM,POD,BMS
 SG_ CGW_DCM_RRSts : 6|1@0+ (1,0) [0|1] ""  TCU,APTC,VCU,MCU,PRND,EVCOM,POD,BMS
 SG_ CGW_SCU_LSts : 7|1@0+ (1,0) [0|1] ""  TCU,APTC,VCU,MCU,PRND,EVCOM,POD,BMS
 SG_ CGW_SCU_RSts : 8|1@0+ (1,0) [0|1] ""  TCU,APTC,VCU,MCU,PRND,EVCOM,POD,BMS
 SG_ CGW_HLRSts : 9|1@0+ (1,0) [0|1] ""  TCU,APTC,VCU,MCU,PRND,EVCOM,POD,BMS
 SG_ CGW_HLLSts : 10|1@0+ (1,0) [0|1] ""  TCU,APTC,VCU,MCU,PRND,EVCOM,POD,BMS
 SG_ CGW_MFP_RCSts : 11|1@0+ (1,0) [0|1] ""  TCU,APTC,VCU,MCU,PRND,EVCOM,POD,BMS
 SG_ CGW_MFP_FCSts : 12|1@0+ (1,0) [0|1] ""  TCU,APTC,VCU,MCU,PRND,EVCOM,POD,BMS
 SG_ CGW_IVISts : 13|1@0+ (1,0) [0|1] ""  TCU,APTC,VCU,MCU,PRND,EVCOM,POD,BMS
 SG_ CGW_ADCUSts : 14|1@0+ (1,0) [0|1] ""  TCU,APTC,VCU,MCU,PRND,EVCOM,POD,BMS
 SG_ CGW_VCUSts : 15|1@0+ (1,0) [0|1] ""  TCU,APTC,VCU,MCU,PRND,EVCOM,POD,BMS
 SG_ CGW_BMSSts : 16|1@0+ (1,0) [0|1] ""  TCU,APTC,VCU,MCU,PRND,EVCOM,POD,BMS
 SG_ CGW_BCMSts : 17|1@0+ (1,0) [0|1] ""  TCU,APTC,VCU,MCU,PRND,EVCOM,POD,BMS
 SG_ CGW_SWPSts : 18|1@0+ (1,0) [0|1] ""  TCU,APTC,VCU,MCU,PRND,EVCOM,POD,BMS
 SG_ CGW_HOD_HeatingSts : 19|1@0+ (1,0) [0|1] ""  TCU,APTC,VCU,MCU,PRND,EVCOM,POD,BMS
 SG_ CGW_SwichesSts : 20|1@0+ (1,0) [0|1] ""  TCU,APTC,VCU,MCU,PRND,EVCOM,POD,BMS
 SG_ CGW_PRNDSts : 21|1@0+ (1,0) [0|1] ""  TCU,APTC,VCU,MCU,PRND,EVCOM,POD,BMS

BO_ 1282 NM_CGW: 8 CGW_PT
 SG_ RxNM_CGW : 7|64@0+ (1,0) [0|1] ""  TCU,APTC,VCU,PRND,EVCOM,BMS

BO_ 1299 NM_BMS: 8 BMS
 SG_ RxNM_BMS : 7|64@0+ (1,0) [0|1] ""  VCU,PRND,CGW_PT

BO_ 1352 NM_TCU: 8 TCU
 SG_ TCU_RMR : 8|1@0+ (1,0) [0|1] ""  APTC,VCU,PRND,EVCOM,CGW_PT,BMS
 SG_ TCU_AWB : 12|1@0+ (1,0) [0|1] ""  APTC,VCU,PRND,EVCOM,CGW_PT,BMS

BO_ 1358 NM_APTC: 8 APTC
 SG_ AIRPTC_RMR : 8|1@0+ (1,0) [0|1] ""  TCU,VCU,PRND,EVCOM,CGW_PT,BMS
 SG_ AIRPTC_AWB : 12|1@0+ (1,0) [0|1] ""  TCU,VCU,PRND,EVCOM,CGW_PT,BMS

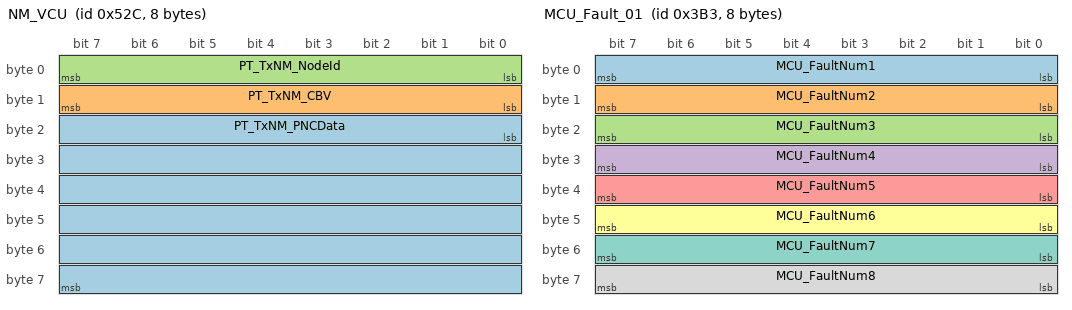
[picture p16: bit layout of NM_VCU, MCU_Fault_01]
BO_ 1324 NM_VCU: 8 VCU
 SG_ PT_TxNM_PNCData : 16|48@1+ (1,0) [0|0] ""  ADCU_CH,CGW_CH
 SG_ PT_TxNM_CBV : 8|8@1+ (1,0) [0|0] ""  ADCU_CH,CGW_CH
 SG_ PT_TxNM_NodeId : 0|8@1+ (1,0) [0|0] ""  ADCU_CH,CGW_CH

BO_ 1359 NM_PRND: 8 PRND
 SG_ RxNM_PRND : 7|64@0+ (1,0) [0|1] ""  VCU,CGW_PT,BMS

BO_ 1353 NM_EVCOM: 8 EVCOM
 SG_ EVCOM_RMR : 8|1@0+ (1,0) [0|1] ""  TCU,APTC,VCU,PRND,CGW_PT,BMS
 SG_ EVCOM_AWB : 12|1@0+ (1,0) [0|1] ""  TCU,APTC,VCU,PRND,CGW_PT,BMS

BO_ 2047 DiagReq_ALL: 8 CGW_PT
 SG_ ALL_DiagReq : 7|64@0+ (1,0) [0|1] ""  TCU,APTC,VCU,MCU,PRND,EVCOM,ADCU_PT,POD,BMS

BO_ 2015 DiagReq_FUN: 8 CGW_PT
 SG_ FUN_DiagReq : 7|64@0+ (1,0) [0|1] ""  TCU,APTC,VCU,MCU,PRND,EVCOM,ADCU_PT,POD,BMS

BO_ 1843 DiagReq_OBD: 8 CGW_PT
 SG_ OBD_DiagReq : 7|64@0+ (1,0) [0|1] ""  VCU

BO_ 2016 DiagReq_VCU_OBD: 8 CGW_PT
 SG_ VCU_OBD_DiagReq : 7|64@0+ (1,0) [0|1] ""  VCU

BO_ 2024 DiagResp_VCU_OBD: 8 VCU
 SG_ VCU_OBD_DiagResp : 7|64@0+ (1,0) [0|1] ""  CGW_PT

BO_ 2026 DiagReq_PT: 8 CGW_PT
 SG_ PT_DiagReq : 7|64@0+ (1,0) [0|1] ""  TCU,APTC,VCU,MCU,PRND,EVCOM,ADCU_PT,POD,BMS

BO_ 1991 DiagReq_POD: 8 CGW_PT
 SG_ POD_DiagReq : 7|64@0+ (1,0) [0|1] ""  POD

BO_ 1939 DiagReq_BMS: 8 CGW_PT
 SG_ BMS_DiagReq : 7|64@0+ (1,0) [0|1] ""  BMS

BO_ 1992 DiagReq_TCU: 8 CGW_PT
 SG_ TCU_DiagReq : 7|64@0+ (1,0) [0|1] ""  TCU

BO_ 1998 DiagReq_AIRPTC: 8 CGW_PT
 SG_ AIRPTC_DiagReq : 7|64@0+ (1,0) [0|1] ""  APTC

BO_ 1964 DiagReq_VCU: 8 CGW_PT
 SG_ VCU_DiagReq : 7|64@0+ (1,0) [0|1] ""  VCU

BO_ 1986 DiagReq_MCU: 8 CGW_PT
 SG_ MCU_DiagReq : 7|64@0+ (1,0) [0|1] ""  MCU

BO_ 1999 DiagReq_PRND: 8 CGW_PT
 SG_ PRND_DiagReq : 7|64@0+ (1,0) [0|1] ""  PRND

BO_ 1993 DiagReq_EVCOM: 8 CGW_PT
 SG_ EVCOM_DiagReq : 7|64@0+ (1,0) [0|1] ""  EVCOM

BO_ 1863 DiagResp_POD: 8 POD
 SG_ POD_DiagResp : 7|64@0+ (1,0) [0|1] ""  CGW_PT

BO_ 1811 DiagResp_BMS: 8 BMS
 SG_ BMS_DiagResp : 7|64@0+ (1,0) [0|1] ""  CGW_PT

BO_ 1864 DiagResp_TCU: 8 TCU
 SG_ TCU_DiagResp : 7|64@0+ (1,0) [0|1] ""  CGW_PT

BO_ 1870 DiagResp_APTC: 8 APTC
 SG_ AIRPTC_DiagResp : 7|64@0+ (1,0) [0|1] ""  CGW_PT

BO_ 1836 DiagResp_VCU: 8 VCU
 SG_ VCU_DiagResp : 7|64@0+ (1,0) [0|1] ""  CGW_PT

BO_ 1858 DiagResp_MCU: 8 MCU
 SG_ MCU_DiagResp : 7|64@0+ (1,0) [0|1] ""  CGW_PT

BO_ 1871 DiagResp_PRND: 8 PRND
 SG_ PRND_DiagResp : 7|64@0+ (1,0) [0|1] ""  CGW_PT

BO_ 1865 DiagResp_EVCOM: 8 EVCOM
 SG_ EVCOM_DiagResp : 7|64@0+ (1,0) [0|1] ""  CGW_PT

BO_ 1095 POD_DiagInfor: 8 POD
 SG_ POD_DTC_Number : 7|8@0+ (1,0) [0|255] ""  CGW_PT

BO_ 1043 BMS_DiagInfor: 8 BMS
 SG_ BMS_DTC_Number : 7|8@0+ (1,0) [0|255] ""  CGW_PT

BO_ 1096 TCU_DiagInfor: 8 TCU
 SG_ TCU_DTC_Number : 7|8@0+ (1,0) [0|255] ""  CGW_PT

BO_ 1102 APTC_DiagInfor: 8 APTC
 SG_ AIRPTC_DTC_Number : 7|8@0+ (1,0) [0|255] ""  CGW_PT

BO_ 1068 VCU_DiagInfor: 8 VCU
 SG_ VCU_DTC_Number : 7|8@0+ (1,0) [0|255] ""  CGW_PT

BO_ 1090 MCU_DiagInfor: 8 MCU
 SG_ MCU_DTC_Number : 7|8@0+ (1,0) [0|255] ""  CGW_PT

BO_ 1103 PRND_DiagInfor: 8 PRND
 SG_ PRND_DTC_Number : 7|8@0+ (1,0) [0|255] ""  CGW_PT

BO_ 1097 EVCOM_DiagInfor: 8 EVCOM
 SG_ EVCOM_DTC_Number : 7|8@0+ (1,0) [0|255] ""  CGW_PT

BO_ 947 MCU_Fault_01: 8 MCU
 SG_ MCU_FaultNum1 : 7|8@0+ (1,0) [0|255] ""  CGW_PT
 SG_ MCU_FaultNum2 : 15|8@0+ (1,0) [0|255] ""  CGW_PT
 SG_ MCU_FaultNum3 : 23|8@0+ (1,0) [0|255] ""  CGW_PT
 SG_ MCU_FaultNum4 : 31|8@0+ (1,0) [0|255] ""  CGW_PT
 SG_ MCU_FaultNum5 : 39|8@0+ (1,0) [0|255] ""  CGW_PT
 SG_ MCU_FaultNum6 : 47|8@0+ (1,0) [0|255] ""  CGW_PT
 SG_ MCU_FaultNum7 : 55|8@0+ (1,0) [0|255] ""  CGW_PT
 SG_ MCU_FaultNum8 : 63|8@0+ (1,0) [0|255] ""  CGW_PT

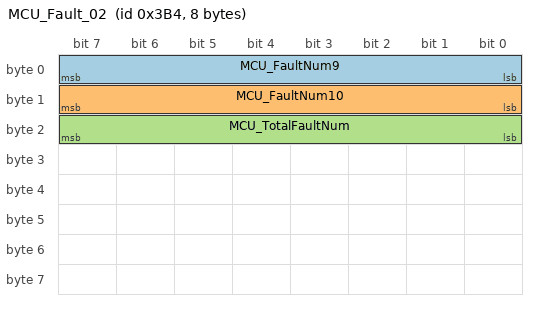
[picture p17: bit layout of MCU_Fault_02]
BO_ 948 MCU_Fault_02: 8 MCU
 SG_ MCU_FaultNum9 : 7|8@0+ (1,0) [0|255] ""  CGW_PT
 SG_ MCU_FaultNum10 : 15|8@0+ (1,0) [0|255] ""  CGW_PT
 SG_ MCU_TotalFaultNum : 23|8@0+ (1,0) [0|255] ""  CGW_PT

BO_TX_BU_ 1843 : CGW_PT,OBD_Node;
BO_TX_BU_ 2016 : CGW_PT,OBD_Node;
BO_TX_BU_ 2024 : VCU,OBD_Node;
CM_ SG_ 580 POD_OBC_ChrgOutpPwrAvl "Report the maximum output power at present.Positive is charge, negative is discharge.";
CM_ SG_ 580 POD_OBC_OutputDCChargeCurrent "OBC output current when charge.Positive is charge, negative is discharge.";
CM_ SG_ 580 POD_OBC_ACPortTempA "Actual temperatur connector A";
CM_ SG_ 580 POD_OBC_ACPortTempB "Actual temperatur connector B";
CM_ SG_ 580 POD_OBC_ACFrequencyStatus "AC side frequency when charge and discharge";
CM_ SG_ 580 POD_OBC_OutputDCChargeVoltage "OutputDCChargeVoltage,Positive is charge, negative is discharge";
CM_ SG_ 787 POD_OBC_ACPortTempASensValid "Error state for the temperature sensor. E.g. damaged or short circuit at the temperature sensor in the inlet.";
CM_ SG_ 787 POD_OBC_ACPortTempBSensValid "Error state for the temperature sensor. E.g. damaged or short circuit at the temperature sensor in the inlet.";
CM_ SG_ 787 POD_OBC_ACPortTempAerror "Sensor A over temporature error";
CM_ SG_ 787 POD_OBC_ACPortTempBerror "Sensor B over temporature errorr";
CM_ SG_ 787 POD_OBC_FaultLevel "0x0: Charge&discharge normally
0x1: Charge&discharge abnormally,but The whole vehicle is charged with limited power, and the corresponding fault code is recorded for the parts. When the fault is lifted, the maximum charging capacity is restored, and the instrument alarm lights up the system fault light.
0x2: Vehicle charging is suspended, parts record the corresponding fault code, instrument alarm display, charging indicator light alarm prompt, after the fault is restored, recharge normally, if the fault cannot be recovered after several restarts, the charging will end.
0x3: Stop charging, disconnect the charging contactor, the instrument lights up the system fault lights, and the parts record the corresponding fault code";
CM_ SG_ 787 POD_OBC_DCVoltHighFault "Charger DC side overvoltage fault(charge and discharge)";
CM_ SG_ 787 POD_OBC_StartUpAllowed "OBC startup status(charge and discharge)";
CM_ SG_ 787 POD_OBC_CommunFault "OBC communication fault with VCU and BMS(charge and discharge)";
CM_ SG_ 787 POD_OBC_DCCurHighFault "Charger DC side over current fault(charge and discharge)";
CM_ SG_ 787 POD_OBC_ACVoltHighFault "Charger AC side overvoltage fault(charge and discharge)";
CM_ SG_ 787 POD_OBC_ACVoltLowFault "Charger AC side undervoltage fault(charge and discharge)";
CM_ SG_ 787 POD_OBC_NlineStatus "Whether AC side N line disconnect(charge and discharge)";
CM_ SG_ 787 POD_OBC_OutputoverloadFault "OBC_OutputoverloadFault";
CM_ SG_ 787 POD_OBC_InputFrequencyStatus "Whether AC side frequency abnormal(charge and discharge)";
CM_ SG_ 787 POD_OBC_InputPhaseStatus "Whether AC side Lack of input phase(charge and discharge)";
CM_ SG_ 787 POD_OBC_InputOverCurrentstatus_R "PFC input over current between L1 and N(charge and discharge)";
CM_ SG_ 787 POD_OBC_InputOverCurrentstatus_S "PFC input over current between L2 and N";
CM_ SG_ 787 POD_OBC_InputOverCurrentstatus_T "PFC input over current between L3 and N";
CM_ SG_ 787 POD_OBC_PFCUnderVoltageError "VBUS under voltage(charge and discharge)";
CM_ SG_ 787 POD_OBC_PFCOverVoltageError "VBUS over voltage(charge and discharge)";
CM_ SG_ 787 POD_OBC_OutputShortError "Output short(charge and discharge)";
CM_ SG_ 787 POD_OBC_Side1Overtempfault "Primary side overtemp,at primary side ,we have total three temporature check point, but we only need to check the maximum value error (charge and discharge)";
CM_ SG_ 787 POD_OBC_Side2Overtempfault "Secordary side overtemp (charge and discharge)";
CM_ SG_ 787 POD_OBC_InternalFault "OBC internal fault(internal error)";
CM_ SG_ 787 POD_OBC_DCVoltLowFault "Charger DC side undervoltage fault(charge and discharge)";
CM_ SG_ 787 POD_OBC_InputShortError "Input short （charge）";
CM_ SG_ 787 POD_DCDC_CommunFault "DCDCC communication fault with VCU";
CM_ SG_ 787 OBC_OutputIsolatedFault "Discharge isolated fault at AC side.（discharge）";
CM_ SG_ 787 POD_OBC_PrimarySideTemp "This signal is sent to TMS,according to this signal, TCU request reduce the temporature of water,and we have total three temporature check point, but we only need to check the maximum value (charge and discharge)";
CM_ SG_ 787 POD_OBC_SecondarySideTemp "This signal is sent to TMS,according to this signal, TCU request reduce the temporature of water.(charge and discharge)";
CM_ SG_ 585 POD_OBC_InputACCurrent_R "Report phase R currents,Positive is charge, negative is discharge";
CM_ SG_ 585 POD_OBC_InputACCurrent_S "Report phase S currents";
CM_ SG_ 585 POD_OBC_InputACCurrent_T "Report phase T currents";
CM_ SG_ 585 POD_OBC_InputACVoltage_R "Report phase R voltage,";
CM_ SG_ 585 POD_OBC_InputACVoltage_S "Report phase S voltage";
CM_ SG_ 585 POD_OBC_InputACVoltage_T "Report phase T voltage";
CM_ SG_ 576 POD_DCFCVoltage "DC relay out side voltage";
CM_ SG_ 576 POD_Temperature "This signal reflects the temperature of Coolant outlet";
CM_ SG_ 576 POD_DCInletTempA "Actual DC + temperatur connector";
CM_ SG_ 576 POD_DCInletTempB "Actual DC - temperatur connector";
CM_ SG_ 577 POD_DCPortInletTempBValid "Error state for the temperature sensor. E.g. damaged or short circuit at the temperature sensor in the inlet.";
CM_ SG_ 577 POD_DCPortInletTempAValid "Error state for the temperature sensor. E.g. damaged or short circuit at the temperature sensor in the inlet.";
CM_ SG_ 577 POD_DCPosRelayState "Give feedback of DC charge positive relay state";
CM_ SG_ 577 POD_KL30Error "KL30 error";
CM_ SG_ 577 POD_T15e_fault "Give feedback of T15e status";
CM_ SG_ 577 POD_CANBusoff "CAN  Busoff error";
CM_ SG_ 577 POD_TempHighFault "PCB overtemperature fault（environmental overtemprerature)";
CM_ SG_ 577 POD_TempSensor1Fault "POD temperature fault of the temporature Coolant outlet or structure";
CM_ SG_ 584 Checksum_248 "Checksum signal for frame";
CM_ SG_ 584 MessageCounter_248 "Message counter signal for frame";
CM_ SG_ 584 PRND_RNDbutton "RND Gear button";
CM_ SG_ 584 PRND_Pbutton "P button";
CM_ SG_ 584 PRND_Pbutton_FaultSts "P Fault Status";
CM_ SG_ 584 PRND_RNDbutton_FaultSts "RND Fault Status";
CM_ SG_ 572 SGW_TimingChargeSwitchStatus "SGW feedback results of appointment of charging settings";
CM_ SG_ 572 SGW_RemoteChrgFlapLockCtrlReq "SGW remote charging flap lock control request";
CM_ SG_ 572 SGW_RelockSet "Set auto re-lock via remote APP";
CM_ SG_ 572 SGW_RemoteActiveHorn "Mobile phone active horn";
CM_ SG_ 572 SGW_ChargeFormSet "Reservation charging mode";
CM_ SG_ 572 SGW_TimingChargefrquency "Appointment charging frquency signal";
CM_ SG_ 572 SGW_AppointChargeCmd "Appointment charging start/end command";
CM_ SG_ 572 SGW_DschrgOnOffSet "discharging turn ON or OFF set.";
CM_ SG_ 572 SGW_LockACPlug "Unlock electronic lock by IVI";
CM_ SG_ 572 SGW_HoodlockSet "Hood lock control remotely";
CM_ SG_ 565 SGW_AlarmEnableSet "Remote APP/Atom HUB setting alarm status enable";
CM_ SG_ 565 SGW_ALM_MusicFrequencySet "Ambient light music rhythm setting";
CM_ SG_ 565 SGW_RemoteHVCtrlReq "SGW remote power control request";
CM_ SG_ 565 SGW_FL_BackrestMotorReq "Driver backrest request";
CM_ SG_ 565 SGW_DomeLampBrightSet "Mobile phone dome lamp brightness control signal";
CM_ SG_ 565 SGW_FL_FrontRearReq "Driver forward and backward request";
CM_ SG_ 565 SGW_FL_HeightMotorReq "Driver height request";
CM_ SG_ 565 SGW_WelLightshowOnOffSet "Welcome Light show mobile phone APP switch control";
CM_ SG_ 565 SGW_WelLightshowTimeSet "Mobile phone APP welcome light time set signal";
CM_ SG_ 565 SGW_TaxiArrIllReq "Mobile phone set taxi arrive illumination request signal";
CM_ SG_ 565 SGW_FollowMeHomeTimeSet "Mobile phone APP Follow me home time set signal";
CM_ SG_ 565 SGW_TaxiArriveSts "Mobile phone APP taxi arrive state signal";
CM_ SG_ 565 SGW_BookingCarReq "Booking car request";
CM_ SG_ 565 SGW_HazardWarnReq "The remote hazard warning require";
CM_ SG_ 565 SGW_FollowMeHomeSet "Follow me home set signal";
CM_ SG_ 571 SGW_TimingChargeEndhour "Feedback charging stop time for appointment charging: hour";
CM_ SG_ 571 SGW_TimingChargeEndminute "Feedback charging stop time for appointment charging: minute";
CM_ SG_ 571 SGW_TimingChargeStarthour "Feedbackt charging start time for appointment charging: hour";
CM_ SG_ 571 SGW_TimingChargeStartminute "Feedback charging start time for appointment charging: minute";
CM_ SG_ 692 IVI_MirrorInterfaceMode "Exterior mirrors adjustment interface mode";
CM_ SG_ 692 IVI_VrState "Voice assistant Active/Inactive";
CM_ SG_ 692 IVI_WCBSReminderSet "Wireless Charging Function Set";
CM_ SG_ 960 SGW_TripCounter "Trip counter";
CM_ SG_ 960 SGW_ResetCounter "Reset counter";
CM_ SG_ 960 SGW_SynMsgAuthenticator "Synchronization message authenticator";
CM_ SG_ 561 IVI_ESCOffSet "ESC On/Off switch setting signal";
CM_ SG_ 561 IVI_TPMS_Reset "Reset TPMS";
CM_ SG_ 561 IVI_HDCOffSet "HDC On/Off switch setting signal";
CM_ SG_ 561 IVI_AVHSet "AVH On/Off switch setting signal";
CM_ SG_ 561 IVI_SteeringModeSet "Steering mode set";
CM_ SG_ 561 IVI_BrakeCompensateCmd "Brake compensation setting instruction";
CM_ SG_ 561 IVI_CRLevelSet "The user specified  energy recovery level";
CM_ SG_ 944 IVI_OdometerInfor "odometer";
CM_ SG_ 944 IVI_OdometerInforValid "IVI external total mileage effective marker signal";
CM_ SG_ 693 IVI_AppointChargeCmd "Charging end command";
CM_ SG_ 693 IVI_ForwardVmaxlimitSw "maximum speed limit in D gear setting";
CM_ SG_ 693 IVI_KeepWarmRequest "Keeping warm function opening instruction";
CM_ SG_ 693 IVI_LockACPlug "Unlock electronic lock by IVI";
CM_ SG_ 693 IVI_LV_LimitPop "Operation pop-up prompt";
CM_ SG_ 694 IVI_GearRequest "Gear request";
CM_ SG_ 261 SGW_RemoteAirCondOnOFFReq "SGW remote air conditioning switch control signal";
CM_ SG_ 261 SGW_RemoteAirCondAUTOReq "Remote Air-Conditioner AUTO module switch request signal";
CM_ SG_ 261 SGW_RemoteFrontDefrostReq "Remote front Defrost command";
CM_ SG_ 261 SGW_FrontDoorAngleSet "SGW front door angle setting";
CM_ SG_ 261 SGW_RearDoorAngleSet "SGW rear door angle setting";
CM_ SG_ 261 SGW_RemoteDrSeatHeatReq "Remote request master driver heating control request";
CM_ SG_ 261 SGW_RemoteSteerHeatReq "Remote request Steering wheel heating control request";
CM_ SG_ 261 SGW_RemotePassSeatHeatReq "Remote request passenger heating control request";
CM_ SG_ 261 SGW_RearDefrostCtrlSet "Remote tailgate window heating command";
CM_ SG_ 261 SGW_RemoteRearMirHeatReq "Remote Rear mirror Heating request";
CM_ SG_ 261 SGW_RemoteFrontWindHeatReq "Remote control front windshield heating";
CM_ SG_ 261 SGW_RemoteRearWindHeatReq "Remote control rear windshield heating";
CM_ SG_ 261 SGW_oneTouchCoolSet "Max cooling setting";
CM_ SG_ 261 SGW_TakePicCtrl "take picture control.";
CM_ SG_ 261 SGW_RemoteTailgateLockCtrlReq "SGW remote tailgate control request.";
CM_ SG_ 261 SGW_RemoteACOnOffReq "SGW remote AC on off request";
CM_ SG_ 261 SGW_LeftChdLockCtrlReq "Left child lock remote control request";
CM_ SG_ 261 SGW_RightChdLockCtrlReq "Right child lock remote control request";
CM_ SG_ 263 SGW_RemoteDrvSetTempSteplsReq "Remote driver seat area set temperature";
CM_ SG_ 263 SGW_RemotePassSetTempSteplsReq "Remote passenger seat area set temperature";
CM_ SG_ 263 SGW_RemoteCarSearchReq "SGW remote search car request.";
CM_ SG_ 263 SGW_AllDoorReq "Four door opening and closing request";
CM_ SG_ 263 SGW_FLDoorReq "SGW Left Front Door Open/Close Request";
CM_ SG_ 263 SGW_FRDoorReq "SGW Right Front Door Open/Close Request";
CM_ SG_ 263 SGW_RLDoorReq "SGW Left Rear Door Open/Close Request";
CM_ SG_ 263 SGW_RRDoorReq "SGW right rear door open close request";
CM_ SG_ 263 SGW_FLWinPosiCtlCmd "Driver window percentage Web control  command";
CM_ SG_ 263 SGW_FRWinPosiCtlCmd "Passenger window percentage Web control command";
CM_ SG_ 263 SGW_RLWinPosiCtlCmd "Left rear window percentage Web control command";
CM_ SG_ 263 SGW_RRWinPosiCtlCmd "Right rear window percentage Web control command";
CM_ SG_ 562 SGW_DrvSetTempSteplsReq "driver seat area set temperature";
CM_ SG_ 562 SGW_DemistReq "Demist request";
CM_ SG_ 562 SGW_HVACBatterySaveModeSetReq "HVAC battery save mode set request";
CM_ SG_ 562 SGW_PassSetTempSteplsReq "passenger seat area set temperature";
CM_ SG_ 562 SGW_AirCondAUTOReq "Air AUTO module switch request signal";
CM_ SG_ 562 SGW_DualReq "dual-zone synchronous mode switching request signal";
CM_ SG_ 562 SGW_AirDistributionModeReq "Air distribution mode request";
CM_ SG_ 562 SGW_FrontDefrostReq "Front Defrost request";
CM_ SG_ 562 SGW_AqsReq "AQS request";
CM_ SG_ 562 SGW_ClimateSystemStsReq "Climate system state request signal";
CM_ SG_ 562 SGW_ACCmprStsReq "AC state request signal";
CM_ SG_ 562 SGW_AirCirclnReq "Cycle mode request";
CM_ SG_ 562 SGW_BlowersteplsSpdReq "Blower Stepless Speed request";
CM_ SG_ 562 SGW_PresetModeEnable "Preset Mode Enable Command";
CM_ SG_ 562 SGW_PresetModeReq "Preset Mode Request";
CM_ SG_ 562 SGW_VentilationModeReq "Ventilation Mode Request";
CM_ SG_ 562 SGW_AirCondEcoSet "ECO mode setting";
CM_ SG_ 564 SGW_TimeInfoSecond "Time informatioin, Second(UTC time)";
CM_ SG_ 564 SGW_TimeInfoMinute "Time informatioin, Minute(UTC time)";
CM_ SG_ 564 SGW_TimeInfoHour "Time informatioin, Hour(UTC time)";
CM_ SG_ 564 SGW_TimeInfoDay "Time informatioin, Day(UTC time)";
CM_ SG_ 564 SGW_TimeInfoMonth "Time informatioin, Month(UTC time)";
CM_ SG_ 564 SGW_TimeInfoYear "Time informatioin, Year(UTC time)";
CM_ SG_ 564 SGW_TimeValid "Time Valid";
CM_ SG_ 560 IVI_DschrgOnOffSet "discharging turn ON or OFF set.";
CM_ SG_ 560 IVI_DriveModeSet "Driving mode set.";
CM_ SG_ 560 IVI_ForwardVmaxAllowed "D-gear maximum speed setting value";
CM_ SG_ 560 IVI_MaxChrgSocSet "Target charge level setting signal";
CM_ SG_ 560 IVI_V2LidisSet "V2L minimum power value set by the user";
CM_ SG_ 608 TCU_TMSTotalPwrCnsmp "TMS TotalPower Consumption";
CM_ SG_ 608 TCU_EVCompState "Compressor work state";
CM_ SG_ 608 TCU_TMSState "Thermal management control state";
CM_ SG_ 608 TCU_TMSFaultLevel "TMS SYSTEM Error level";
CM_ SG_ 608 TCU_HvOnReq "Forbidden to disconnect the high voltage (thermal management) request";
CM_ SG_ 608 TCU_HVCHState "Water heater work state";
CM_ SG_ 608 TCU_APTCState "Air heater work state";
CM_ SG_ 608 TCU_TMSTotoalPwrReq "AC system total power request";
CM_ SG_ 608 TCU_BattTMState "TCU battery Thermal management system status";
CM_ SG_ 608 TCU_HVPwrState "TCU High voltage supply Status";
CM_ SG_ 608 TCU_HVACACState "Front HVAC Cool Or Heat Or Vent Auto State";
CM_ SG_ 608 TCU_APTCLeftMaxPowerLimit "Limit power";
CM_ SG_ 608 TCU_APTCRightMaxPowerLimit "Limit power";
CM_ SG_ 609 TCU_HVCHHighVoltage "HVCH High Voltage Measurement";
CM_ SG_ 609 TCU_APTCLeftCmd "Actual power output percent of APTC Left zone";
CM_ SG_ 609 TCU_APTCRightCmd "Actual power output percent of APTC Right zone";
CM_ SG_ 609 TCU_CompTargetSpeed "Compressor Target Speed";
CM_ SG_ 609 TCU_APTC1Enable "AIR PTC Operate Enable Command";
CM_ SG_ 609 TCU_CompEnable "Compressor Operate Enable Command";
CM_ SG_ 609 TCU_CompMaxAllowPwrCmsp "Compressor Maximum Allowed Power Comsuption";
CM_ SG_ 609 TCU_HVCHHVDCCurrent "Current Draw of HV-PTC";
CM_ SG_ 610 TCU_CabinTemperature "Cabin temperature";
CM_ SG_ 610 TCU_CabinTemperatureValid "Cabin temperature Valid";
CM_ SG_ 768 TCU_FrontDefrostSts "Front Defrost status";
CM_ SG_ 768 TCU_AirCondAUTOSts "AUTO status";
CM_ SG_ 768 TCU_AirCirclnSts "Cycle Mode status";
CM_ SG_ 768 TCU_AirCondEcoSetSts "ECO status";
CM_ SG_ 768 TCU_SelfDryingSetSts "Self-Drying Set status";
CM_ SG_ 768 TCU_DrvTempSts "DrvTemp status";
CM_ SG_ 768 TCU_AqsSts "AQS status";
CM_ SG_ 768 TCU_DualSts "Temperature zone status";
CM_ SG_ 768 TCU_PassTempSts "PasstTemp status";
CM_ SG_ 768 TCU_CoolantLowWarnReq "Coolant Low Warn";
CM_ SG_ 768 TCU_FreonLowWarnReq "Freon Low alarm";
CM_ SG_ 768 TCU_BlowerSpdSts "Air volume status";
CM_ SG_ 768 TCU_AirDistributionModeSts "Air distribution mode status";
CM_ SG_ 768 TCU_PresetModeSts "Preset Mode Status";
CM_ SG_ 768 TCU_VentilationModeSts "Ventilation Mode Status";
CM_ SG_ 768 TCU_HVACBatterySaveSts "HVAC battery save mode active status";
CM_ SG_ 768 TCU_HVACBatterySaveModeSetSts "HVAC battery save mode set status";
CM_ SG_ 768 TCU_ACCmprSts "AC status signal";
CM_ SG_ 768 TCU_ClimateSystemSts "Climate system state feedback signal";
CM_ SG_ 768 TCU_PowerLimitSts "The power limit status of the air conditioner";
CM_ SG_ 768 TCU_OutsideAQSLevel "Outdoor air quality rating";
CM_ SG_ 768 TCU_WindowClosRemind "Window closing reminder";
CM_ SG_ 768 TCU_DemistSts "Demist status";
CM_ SG_ 793 VCU_BS_IBSBatSOC "LV Battery SOC";
CM_ SG_ 793 VCU_BS_Current "LV Battery current(Route Lin signal ' BS_BatCrntRawVal')";
CM_ SG_ 793 VCU_BS_IndicatorSts "Battery failure";
CM_ SG_ 793 VCU_BS_LV_Batt "LV Battery voltage(Route Lin signal 'BS_BatVltHIRes')";
CM_ SG_ 793 VCU_WakeUpStatus "VCU Wake Up Status";
CM_ SG_ 548 VCU_MaximumOutputCurrent "Maximum Output Current";
CM_ SG_ 548 VCU_MaximumOutputVoltage "Maximum Output Voltage";
CM_ SG_ 548 VCU_MinimumOutputCurrent "Minimum Output Current";
CM_ SG_ 548 VCU_MinimumOutputVoltage "Minimum Output Voltage";
CM_ SG_ 549 VCU_DisChgPowerLimit "Discharge power limitation";
CM_ SG_ 549 VCU_PermitPackPTC "PackPTC relay close permit instruction";
CM_ SG_ 549 VCU_ChargeTime "VCU memory charging time signal";
CM_ SG_ 549 VCU_DisplayMileage "VCU Dynamic Mileage";
CM_ SG_ 549 VCU_MCUPower "MCU real-time power consumption";
CM_ SG_ 549 VCU_ChargeEnergy "VCU memory charging time signal";
CM_ SG_ 210 Checksum_0D2 "Checksum signal for frame";
CM_ SG_ 210 MessageCounter_0D2 "Message counter signal for frame";
CM_ SG_ 210 VCU_AccelerationPedal "Acceleration Pedal percentage";
CM_ SG_ 210 VCU_AccelerationPedalValid "Acceleration Pedal percentage valid status";
CM_ SG_ 210 VCU_EPBReq "VCU request EPB";
CM_ SG_ 210 VCU_Kickdown "Kickdown";
CM_ SG_ 210 VCU_TargetGear "Target Gear position";
CM_ SG_ 210 VCU_VehicleSpeed "VCU calculates the output vehicle speed";
CM_ SG_ 210 VCU_VehicleSpeedValid "Speed Validity Flag";
CM_ SG_ 210 VCU_VirtualACPedal "Virtual acceleration Pedal percentage";
CM_ SG_ 210 VCU_VirtualACPedalValid "Virtual acceleration Pedal percentage valid status";
CM_ SG_ 210 VCU_VLCTorqueRequestActive "Is the VCU responding to VLC torque request function activated";
CM_ SG_ 210 VCU_VLCTorqueRequestAvailable "Is VCU available to respond to VLC torque requests";
CM_ SG_ 209 Checksum_0D1 "Checksum signal for frame";
CM_ SG_ 209 MessageCounter_0D1 "Message counter signal for frame";
CM_ SG_ 209 VCU_IsoMeasurementSwitch "Insulation detection enable instruction.";
CM_ SG_ 209 VCU_RequestedModeBMS "Interface to request eletric energy storage target mode";
CM_ SG_ 209 VCU_HVStatus "HV System state";
CM_ SG_ 209 VCU_ChargeStatus "Charge state";
CM_ SG_ 209 VCU_LimitLevel "Low-voltage energy management limit level";
CM_ SG_ 209 VCU_ActDriveMode "Actual drive mode";
CM_ SG_ 209 VCU_DrvModSwitchWarn "Warning dispaly when dirve mode swich";
CM_ SG_ 209 VCU_RegenBrakeLightReqVld "Valid status of Request to illuminate the brake lights from the Powertrain";
CM_ SG_ 209 VCU_RegenBrakeLightRequest "Request to illuminate the brake lights from the Powertrain if regen creates deceleration greater than 0.07g.";
CM_ SG_ 209 VCU_BMSTargetThermLevel "BMS target temperature level";
CM_ SG_ 209 VCU_BMS_Control_of_PosRelay "Request for closing positive relay";
CM_ SG_ 544 VCU_VoltageDemandLV "Desired voltage of the DCDC converter LV side (buck mode 14.1v)";
CM_ SG_ 544 VCU_RequestedModeDCDC "Requested state of the DCDC converter";
CM_ SG_ 544 VCU_DCDCPowerLimit "DCDC power limit";
CM_ SG_ 792 Checksum_318 "Checksum signal for frame";
CM_ SG_ 792 MessageCounter_318 "Message counter signal for frame";
CM_ SG_ 792 VCU_MCU_FaultLampReq "MCU failure indicator";
CM_ SG_ 792 VCU_Display_Power "Charge and discharge power (display)";
CM_ SG_ 792 VCU_SystemReady "Ready lamp indicator";
CM_ SG_ 792 VCU_Display_Cur "Charge and discharge current (display)";
CM_ SG_ 792 VCU_maxChargeSOC "Target charging level setting feedback signal";
CM_ SG_ 792 VCU_DischargeEndSoc "Discharge cutoff SOC";
CM_ SG_ 792 VCU_ForwardVmaxAllowed "Maximum speed setting state of D gear";
CM_ SG_ 795 VCU_BS_HCurrent "LV Battery current";
CM_ SG_ 795 VCU_BS_QuiescentCurrent "The average sleep current value of a vehicle during a long period of hibernation (specifically referring to the previous hibernation cycle)";
CM_ SG_ 795 VCU_Display_voltage "Charge and discharge voltage (display)";
CM_ SG_ 150 VCU_MotorSpdReq "Desired speed electric machine";
CM_ SG_ 150 VCU_MaxSpdLimit "Upper limit output speed of electric machine";
CM_ SG_ 150 VCU_MCUActHeatPwr "Desired heating power of electric machine";
CM_ SG_ 149 Checksum_095 "Checksum signal for frame";
CM_ SG_ 149 MessageCounter_095 "Message counter signal for frame";
CM_ SG_ 149 VCU_PWTErrorLevel "Fault level of the power domain";
CM_ SG_ 149 VCU_MCUDesiredTorque "Desired torque electric machine";
CM_ SG_ 149 VCU_KL15eOn "the bit status of KL15e signal";
CM_ SG_ 149 VCU_TCSActive "EN: Tindicates TCS intervention active,TCS will detect spinning wheels and request torque reduction/limitation";
CM_ SG_ 149 VCU_MCUSurgeDamperState "Requested surge damper state";
CM_ SG_ 149 VCU_ActualGear "The actual gear status";
CM_ SG_ 149 VCU_BrakepedalStatus "the break pedal status";
CM_ SG_ 149 VCU_RequestedModeMCU "Request to the electric machine";
CM_ SG_ 149 VCU_TrqThresholdDampgCtl "Threshold torque for damping control";
CM_ SG_ 214 VCU_MaxTorqueGradient "Maximum allowed change rate of actual torque";
CM_ SG_ 214 VCU_MinTorqueLimit "Lower limit output torque of electric machine";
CM_ SG_ 214 VCU_MaxTorqueLimit "Upper limit output torque of electric machine";
CM_ SG_ 214 VCU_CreepTorque "Creep Torque";
CM_ SG_ 214 VCU_SpdLimitActTorque "Speed Limit Actual Torque";
CM_ SG_ 289 VCU_Enable_DC_Relay "enable: Request for closing DC charging relay";
CM_ SG_ 289 VCU_OBC_Control_of_S2_SW "OBC should accept the control signal from VCU to switch the S2 inside the OBC";
CM_ SG_ 289 VCU_OBC_Control_of_em_lock "OBC should accept the control signal from VCU to lock or unlock the actuator in the Inlet for locking or unlocking the charging plug";
CM_ SG_ 289 VCU_EnableOBC "When VCU receiving OBC Charge Status= Ready and detecting the status of S2 is closed,VCU send enable
When VCU detect that the stop charging condition is met, VUC send disable.";
CM_ SG_ 289 VCU_OBC_ChargeCurrentCommand "OBC output charging current according to this signal.";
CM_ SG_ 545 VCU_RequestedModeTCU "Requested mode of TCU";
CM_ SG_ 545 VCU_TCUPowerAllowed "TCU Maximum Allowed Power Comsuption";
CM_ SG_ 319 VCU_SynRequest "Counter sychronization request message";
CM_ SG_ 896 CGW_VIN0 "World Manufacturers Identification";
CM_ SG_ 896 CGW_VIN1 "World Manufacturers Identification";
CM_ SG_ 896 CGW_VIN2 "World Manufacturers Identification";
CM_ SG_ 896 CGW_VIN3 "Vehicle Description Section";
CM_ SG_ 896 CGW_VIN4 "Vehicle Description Section";
CM_ SG_ 896 CGW_VIN5 "Vehicle Description Section";
CM_ SG_ 896 CGW_VIN6 "Vehicle Description Section";
CM_ SG_ 896 CGW_VIN7 "Vehicle Description Section";
CM_ SG_ 897 CGW_VIN8 "Vehicle Identification Section";
CM_ SG_ 897 CGW_VIN9 "Vehicle Identification Section";
CM_ SG_ 897 CGW_VIN10 "Vehicle Identification Section";
CM_ SG_ 897 CGW_VIN11 "Vehicle Identification Section";
CM_ SG_ 897 CGW_VIN12 "Vehicle Identification Section";
CM_ SG_ 897 CGW_VIN13 "Vehicle Identification Section";
CM_ SG_ 897 CGW_VIN14 "Vehicle Identification Section";
CM_ SG_ 897 CGW_VIN15 "Vehicle Identification Section";
CM_ SG_ 898 CGW_VIN16 "Vehicle Identification Section";
CM_ SG_ 898 CGW_VERSION1 "Major Release";
CM_ SG_ 898 CGW_VERSION2 "Minor Release";
CM_ SG_ 858 CGW_SGWSts "SGW status at this time";
CM_ SG_ 858 CGW_CGWSts "CGW status at this time";
CM_ SG_ 858 CGW_CBMSts "CBM status at this time";
CM_ SG_ 858 CGW_DCM_FLSts "DCM_FL status at this time";
CM_ SG_ 858 CGW_DCM_FRSts "DCM_FR status at this time";
CM_ SG_ 858 CGW_DCM_RLSts "DCM_RL status at this time";
CM_ SG_ 858 CGW_DCM_RRSts "DCM_RR status at this time";
CM_ SG_ 858 CGW_SCU_LSts "SCU_L status at this time";
CM_ SG_ 858 CGW_SCU_RSts "SCU_R status at this time";
CM_ SG_ 858 CGW_HLRSts "HLR status at this time";
CM_ SG_ 858 CGW_HLLSts "HLL status at this time";
CM_ SG_ 858 CGW_MFP_RCSts "MFP_RC status at this time";
CM_ SG_ 858 CGW_MFP_FCSts "MFP_FC status at this time";
CM_ SG_ 858 CGW_IVISts "IVI  status at this time";
CM_ SG_ 858 CGW_ADCUSts "ADCU status at this time";
CM_ SG_ 858 CGW_VCUSts "VCU  status at this time";
CM_ SG_ 858 CGW_BMSSts "BMS status at this time";
CM_ SG_ 858 CGW_BCMSts "BCM status at this time";
CM_ SG_ 858 CGW_SWPSts "SWP status at this time";
CM_ SG_ 858 CGW_HOD_HeatingSts "HOD_Heating status at this time";
CM_ SG_ 858 CGW_SwichesSts "Swiches status at this time";
CM_ SG_ 858 CGW_PRNDSts "PRND status at this time";
CM_ SG_ 2047 ALL_DiagReq "Diagnostic request";
CM_ SG_ 2015 FUN_DiagReq "Diagnostic request";
CM_ SG_ 1843 OBD_DiagReq "OBD Diagnostic request";
CM_ SG_ 2016 VCU_OBD_DiagReq "VCU_OBD_Diagnostic request";
CM_ SG_ 2024 VCU_OBD_DiagResp "VCU_OBD_Diagnostic response";
CM_ SG_ 2026 PT_DiagReq "Powertrain-CAN Diagnostic request";
CM_ SG_ 1991 POD_DiagReq "Diagnostic request";
CM_ SG_ 1939 BMS_DiagReq "Diagnostic request";
CM_ SG_ 1992 TCU_DiagReq "Diagnostic request";
CM_ SG_ 1998 AIRPTC_DiagReq "Diagnostic request";
CM_ SG_ 1964 VCU_DiagReq "Diagnostic request";
CM_ SG_ 1986 MCU_DiagReq "Diagnostic request";
CM_ SG_ 1999 PRND_DiagReq "Diagnostic request";
CM_ SG_ 1993 EVCOM_DiagReq "Diagnostic request";
CM_ SG_ 1863 POD_DiagResp "Diagnostic response";
CM_ SG_ 1811 BMS_DiagResp "Diagnostic response";
CM_ SG_ 1864 TCU_DiagResp "Diagnostic response";
CM_ SG_ 1870 AIRPTC_DiagResp "Diagnostic response";
CM_ SG_ 1836 VCU_DiagResp "Diagnostic response";
CM_ SG_ 1858 MCU_DiagResp "Diagnostic response";
CM_ SG_ 1871 PRND_DiagResp "Diagnostic response";
CM_ SG_ 1865 EVCOM_DiagResp "Diagnostic response";
CM_ SG_ 1095 POD_DTC_Number "Number of current failures";
CM_ SG_ 1043 BMS_DTC_Number "Number of current failures";
CM_ SG_ 1096 TCU_DTC_Number "Number of current failures";
CM_ SG_ 1102 AIRPTC_DTC_Number "Number of current failures";
CM_ SG_ 1068 VCU_DTC_Number "Number of current failures";
CM_ SG_ 1090 MCU_DTC_Number "Number of current failures";
CM_ SG_ 1103 PRND_DTC_Number "Number of current failures";
CM_ SG_ 1097 EVCOM_DTC_Number "Number of current failures";
CM_ SG_ 947 MCU_FaultNum1 "Real-time fault code of number 1";
CM_ SG_ 947 MCU_FaultNum2 "Real-time fault code of number 2";
CM_ SG_ 947 MCU_FaultNum3 "Real-time fault code of number 3";
CM_ SG_ 947 MCU_FaultNum4 "Real-time fault code of number 4";
CM_ SG_ 947 MCU_FaultNum5 "Real-time fault code of number 5";
CM_ SG_ 947 MCU_FaultNum6 "Real-time fault code of number 6";
CM_ SG_ 947 MCU_FaultNum7 "Real-time fault code of number 7";
CM_ SG_ 947 MCU_FaultNum8 "Real-time fault code of number 8";
CM_ SG_ 948 MCU_FaultNum9 "Real-time fault code of number 9";
CM_ SG_ 948 MCU_FaultNum10 "Real-time fault code of number 10";
CM_ SG_ 948 MCU_TotalFaultNum "Total number of current faults";
BA_DEF_ BO_  "SCP_FreshnessValueTxLength" INT 0 512;
BA_DEF_ BO_  "SCP_FreshnessValueLength" INT 0 512;
BA_DEF_ BO_  "SCP_FreshnessValueld" INT 0 65535;
BA_DEF_ BO_  "SCP_DataId" INT 0 65535;
BA_DEF_ BO_  "SCP_AuthinfoTxLength" INT 0 512;
BA_DEF_ BO_  "DiagConnection" INT 0 0;
BA_DEF_ BO_  "GenMsgSendType" ENUM  "Cyclic","Event","IfActive","CE","CA","NoMsgSendType";
BA_DEF_ BO_  "GenMsgCycleTime" INT 0 0;
BA_DEF_ BO_  "GenMsgCycleTimeFast" INT 0 0;
BA_DEF_ BO_  "GenMsgNrOfRepetition" INT 0 0;
BA_DEF_ BO_  "GenMsgDelayTime" INT 0 0;
BA_DEF_ BO_  "GenMsgILSupport" ENUM  "No","Yes";
BA_DEF_ BO_  "NmMessage" ENUM  "No","Yes";
BA_DEF_ BO_  "DiagState" ENUM  "No","Yes";
BA_DEF_ BO_  "DiagRequest" ENUM  "No","Yes";
BA_DEF_ BO_  "DiagResponse" ENUM  "No","Yes";
BA_DEF_ SG_  "GenSigSendType" ENUM  "Cyclic","OnChange","OnWrite","IfActive","OnChangeWithRepetition","OnWriteWithRepetition","IfActiveWithRepetition","NoSigSendType","NotUsed","NotUsed","NotUsed","NotUsed","NotUsed";
BA_DEF_ SG_  "GenSigStartValue" INT 0 0;
BA_DEF_ SG_  "GenSigInvalidValue" INT 0 0;
BA_DEF_ SG_  "SystemSignalLongSymbol" STRING ;
BA_DEF_DEF_  "SCP_FreshnessValueTxLength" 4;
BA_DEF_DEF_  "SCP_FreshnessValueLength" 48;
BA_DEF_DEF_  "SCP_FreshnessValueld" 0;
BA_DEF_DEF_  "SCP_DataId" 0;
BA_DEF_DEF_  "SCP_AuthinfoTxLength" 28;
BA_DEF_DEF_  "DiagConnection" 0;
BA_DEF_DEF_  "GenMsgSendType" "Cyclic";
BA_DEF_DEF_  "GenMsgCycleTime" 0;
BA_DEF_DEF_  "GenMsgCycleTimeFast" 0;
BA_DEF_DEF_  "GenMsgNrOfRepetition" 0;
BA_DEF_DEF_  "GenMsgDelayTime" 0;
BA_DEF_DEF_  "GenMsgILSupport" "Yes";
BA_DEF_DEF_  "NmMessage" "No";
BA_DEF_DEF_  "DiagState" "No";
BA_DEF_DEF_  "DiagRequest" "No";
BA_DEF_DEF_  "DiagResponse" "No";
BA_DEF_DEF_  "GenSigSendType" "Cyclic";
BA_DEF_DEF_  "GenSigStartValue" 0;
BA_DEF_DEF_  "GenSigInvalidValue" 0;
BA_DEF_DEF_  "SystemSignalLongSymbol" "";
BA_ "GenMsgCycleTime" BO_ 580 100;
BA_ "GenMsgCycleTime" BO_ 787 200;
BA_ "GenMsgCycleTime" BO_ 585 100;
BA_ "GenMsgCycleTime" BO_ 576 100;
BA_ "GenMsgCycleTime" BO_ 577 100;
BA_ "GenMsgDelayTime" BO_ 584 20;
BA_ "GenMsgNrOfRepetition" BO_ 584 3;
BA_ "GenMsgCycleTimeFast" BO_ 584 20;
BA_ "GenMsgCycleTime" BO_ 584 100;
BA_ "GenMsgSendType" BO_ 584 3;
BA_ "GenMsgDelayTime" BO_ 572 20;
BA_ "GenMsgNrOfRepetition" BO_ 572 3;
BA_ "GenMsgCycleTimeFast" BO_ 572 20;
BA_ "GenMsgCycleTime" BO_ 572 100;
BA_ "GenMsgSendType" BO_ 572 3;
BA_ "GenMsgDelayTime" BO_ 565 20;
BA_ "GenMsgNrOfRepetition" BO_ 565 3;
BA_ "GenMsgCycleTimeFast" BO_ 565 20;
BA_ "GenMsgCycleTime" BO_ 565 100;
BA_ "GenMsgSendType" BO_ 565 3;
BA_ "GenMsgCycleTime" BO_ 571 100;
BA_ "GenMsgCycleTime" BO_ 692 100;
BA_ "GenMsgCycleTime" BO_ 960 20000;
BA_ "SCP_AuthinfoTxLength" BO_ 960 24;
BA_ "SCP_DataId" BO_ 960 960;
BA_ "SCP_FreshnessValueld" BO_ 960 3;
BA_ "SCP_FreshnessValueLength" BO_ 960 64;
BA_ "SCP_FreshnessValueTxLength" BO_ 960 40;
BA_ "GenMsgDelayTime" BO_ 561 20;
BA_ "GenMsgNrOfRepetition" BO_ 561 3;
BA_ "GenMsgCycleTimeFast" BO_ 561 20;
BA_ "GenMsgSendType" BO_ 561 1;
BA_ "GenMsgCycleTime" BO_ 944 1000;
BA_ "GenMsgDelayTime" BO_ 693 20;
BA_ "GenMsgNrOfRepetition" BO_ 693 3;
BA_ "GenMsgCycleTimeFast" BO_ 693 20;
BA_ "GenMsgSendType" BO_ 693 1;
BA_ "GenMsgDelayTime" BO_ 694 20;
BA_ "GenMsgNrOfRepetition" BO_ 694 3;
BA_ "GenMsgCycleTimeFast" BO_ 694 20;
BA_ "GenMsgSendType" BO_ 694 1;
BA_ "GenMsgDelayTime" BO_ 261 20;
BA_ "GenMsgNrOfRepetition" BO_ 261 3;
BA_ "GenMsgCycleTimeFast" BO_ 261 20;
BA_ "GenMsgSendType" BO_ 261 1;
BA_ "GenMsgDelayTime" BO_ 263 20;
BA_ "GenMsgNrOfRepetition" BO_ 263 3;
BA_ "GenMsgCycleTimeFast" BO_ 263 20;
BA_ "GenMsgSendType" BO_ 263 1;
BA_ "GenMsgDelayTime" BO_ 562 20;
BA_ "GenMsgNrOfRepetition" BO_ 562 3;
BA_ "GenMsgCycleTimeFast" BO_ 562 20;
BA_ "GenMsgSendType" BO_ 562 1;
BA_ "GenMsgCycleTime" BO_ 564 100;
BA_ "GenMsgDelayTime" BO_ 560 20;
BA_ "GenMsgNrOfRepetition" BO_ 560 3;
BA_ "GenMsgCycleTimeFast" BO_ 560 20;
BA_ "GenMsgSendType" BO_ 560 1;
BA_ "GenMsgCycleTime" BO_ 608 100;
BA_ "GenMsgCycleTime" BO_ 609 100;
BA_ "GenMsgCycleTime" BO_ 610 100;
BA_ "GenMsgCycleTime" BO_ 768 200;
BA_ "GenMsgCycleTime" BO_ 793 200;
BA_ "GenMsgCycleTime" BO_ 548 100;
BA_ "GenMsgCycleTime" BO_ 549 100;
BA_ "GenMsgCycleTime" BO_ 210 20;
BA_ "GenMsgCycleTime" BO_ 209 20;
BA_ "GenMsgCycleTime" BO_ 544 100;
BA_ "GenMsgCycleTime" BO_ 792 200;
BA_ "GenMsgCycleTime" BO_ 795 200;
BA_ "GenMsgCycleTime" BO_ 150 10;
BA_ "GenMsgCycleTime" BO_ 149 10;
BA_ "GenMsgCycleTime" BO_ 214 20;
BA_ "GenMsgCycleTime" BO_ 289 50;
BA_ "GenMsgCycleTime" BO_ 545 100;
BA_ "GenMsgSendType" BO_ 319 1;
BA_ "SCP_AuthinfoTxLength" BO_ 319 32;
BA_ "SCP_DataId" BO_ 319 319;
BA_ "SCP_FreshnessValueld" BO_ 319 319;
BA_ "SCP_FreshnessValueLength" BO_ 319 64;
BA_ "SCP_FreshnessValueTxLength" BO_ 319 16;
BA_ "GenMsgCycleTime" BO_ 896 500;
BA_ "GenMsgCycleTime" BO_ 897 500;
BA_ "GenMsgCycleTime" BO_ 898 500;
BA_ "GenMsgCycleTime" BO_ 858 200;
BA_ "GenMsgCycleTime" BO_ 1282 20;
BA_ "NmMessage" BO_ 1282 1;
BA_ "GenMsgCycleTime" BO_ 1299 20;
BA_ "NmMessage" BO_ 1299 1;
BA_ "GenMsgCycleTime" BO_ 1352 20;
BA_ "NmMessage" BO_ 1352 1;
BA_ "GenMsgCycleTime" BO_ 1358 20;
BA_ "NmMessage" BO_ 1358 1;
BA_ "GenMsgCycleTime" BO_ 1324 20;
BA_ "NmMessage" BO_ 1324 1;
BA_ "GenMsgCycleTime" BO_ 1359 20;
BA_ "NmMessage" BO_ 1359 1;
BA_ "GenMsgCycleTime" BO_ 1353 20;
BA_ "NmMessage" BO_ 1353 1;
BA_ "GenMsgSendType" BO_ 2047 1;
BA_ "DiagConnection" BO_ 2047 1;
BA_ "DiagState" BO_ 2047 1;
BA_ "DiagState" BO_ 2015 1;
BA_ "GenMsgSendType" BO_ 2015 1;
BA_ "DiagConnection" BO_ 2015 1;
BA_ "GenMsgSendType" BO_ 1843 1;
BA_ "DiagConnection" BO_ 1843 2;
BA_ "DiagState" BO_ 1843 1;
BA_ "DiagRequest" BO_ 2016 1;
BA_ "GenMsgSendType" BO_ 2016 1;
BA_ "DiagConnection" BO_ 2016 2;
BA_ "DiagResponse" BO_ 2024 1;
BA_ "GenMsgSendType" BO_ 2024 1;
BA_ "DiagConnection" BO_ 2024 2;
BA_ "GenMsgSendType" BO_ 2026 1;
BA_ "DiagConnection" BO_ 2026 1;
BA_ "DiagState" BO_ 2026 1;
BA_ "DiagRequest" BO_ 1991 1;
BA_ "GenMsgSendType" BO_ 1991 1;
BA_ "DiagConnection" BO_ 1991 3;
BA_ "DiagRequest" BO_ 1939 1;
BA_ "GenMsgSendType" BO_ 1939 1;
BA_ "DiagConnection" BO_ 1939 3;
BA_ "DiagRequest" BO_ 1992 1;
BA_ "GenMsgSendType" BO_ 1992 1;
BA_ "DiagConnection" BO_ 1992 3;
BA_ "DiagRequest" BO_ 1998 1;
BA_ "GenMsgSendType" BO_ 1998 1;
BA_ "DiagConnection" BO_ 1998 3;
BA_ "DiagRequest" BO_ 1964 1;
BA_ "GenMsgSendType" BO_ 1964 1;
BA_ "DiagConnection" BO_ 1964 1;
BA_ "DiagRequest" BO_ 1986 1;
BA_ "GenMsgSendType" BO_ 1986 1;
BA_ "DiagConnection" BO_ 1986 3;
BA_ "DiagRequest" BO_ 1999 1;
BA_ "GenMsgSendType" BO_ 1999 1;
BA_ "DiagConnection" BO_ 1999 3;
BA_ "DiagRequest" BO_ 1993 1;
BA_ "GenMsgSendType" BO_ 1993 1;
BA_ "DiagConnection" BO_ 1993 3;
BA_ "DiagResponse" BO_ 1863 1;
BA_ "GenMsgSendType" BO_ 1863 1;
BA_ "DiagConnection" BO_ 1863 3;
BA_ "DiagResponse" BO_ 1811 1;
BA_ "GenMsgSendType" BO_ 1811 1;
BA_ "DiagConnection" BO_ 1811 3;
BA_ "DiagResponse" BO_ 1864 1;
BA_ "GenMsgSendType" BO_ 1864 1;
BA_ "DiagConnection" BO_ 1864 3;
BA_ "DiagResponse" BO_ 1870 1;
BA_ "GenMsgSendType" BO_ 1870 1;
BA_ "DiagConnection" BO_ 1870 3;
BA_ "DiagResponse" BO_ 1836 1;
BA_ "GenMsgSendType" BO_ 1836 1;
BA_ "DiagConnection" BO_ 1836 1;
BA_ "DiagResponse" BO_ 1858 1;
BA_ "GenMsgSendType" BO_ 1858 1;
BA_ "DiagConnection" BO_ 1858 3;
BA_ "DiagResponse" BO_ 1871 1;
BA_ "GenMsgSendType" BO_ 1871 1;
BA_ "DiagConnection" BO_ 1871 3;
BA_ "DiagResponse" BO_ 1865 1;
BA_ "GenMsgSendType" BO_ 1865 1;
BA_ "DiagConnection" BO_ 1865 3;
BA_ "GenMsgCycleTime" BO_ 1095 1000;
BA_ "GenMsgCycleTime" BO_ 1043 1000;
BA_ "GenMsgCycleTime" BO_ 1096 1000;
BA_ "GenMsgCycleTime" BO_ 1102 1000;
BA_ "GenMsgCycleTime" BO_ 1068 1000;
BA_ "GenMsgCycleTime" BO_ 1090 1000;
BA_ "GenMsgCycleTime" BO_ 1103 1000;
BA_ "GenMsgCycleTime" BO_ 1097 1000;
BA_ "GenMsgCycleTime" BO_ 947 1000;
BA_ "GenMsgCycleTime" BO_ 948 1000;
BA_ "GenSigStartValue" SG_ 577 POD_DCPosRelayState 1;
BA_ "GenSigInvalidValue" SG_ 584 MessageCounter_248 15;
BA_ "GenSigSendType" SG_ 584 PRND_RNDbutton 5;
BA_ "GenSigSendType" SG_ 584 PRND_Pbutton 5;
BA_ "GenSigSendType" SG_ 572 SGW_RemoteChrgFlapLockCtrlReq 4;
BA_ "GenSigSendType" SG_ 572 SGW_RelockSet 4;
BA_ "GenSigSendType" SG_ 572 SGW_RemoteActiveHorn 4;
BA_ "GenSigStartValue" SG_ 572 SGW_ChargeFormSet 1;
BA_ "GenSigSendType" SG_ 572 SGW_AppointChargeCmd 4;
BA_ "GenSigInvalidValue" SG_ 572 SGW_DschrgOnOffSet 3;
BA_ "GenSigSendType" SG_ 572 SGW_DschrgOnOffSet 4;
BA_ "GenSigSendType" SG_ 572 SGW_LockACPlug 4;
BA_ "GenSigSendType" SG_ 572 SGW_HoodlockSet 4;
BA_ "GenSigSendType" SG_ 565 SGW_AlarmEnableSet 4;
BA_ "GenSigSendType" SG_ 565 SGW_ALM_MusicFrequencySet 4;
BA_ "GenSigSendType" SG_ 565 SGW_FL_BackrestMotorReq 4;
BA_ "GenSigSendType" SG_ 565 SGW_DomeLampBrightSet 4;
BA_ "GenSigSendType" SG_ 565 SGW_FL_FrontRearReq 4;
BA_ "GenSigSendType" SG_ 565 SGW_FL_HeightMotorReq 4;
BA_ "GenSigSendType" SG_ 565 SGW_WelLightshowOnOffSet 4;
BA_ "GenSigSendType" SG_ 565 SGW_WelLightshowTimeSet 4;
BA_ "GenSigSendType" SG_ 565 SGW_TaxiArrIllReq 4;
BA_ "GenSigSendType" SG_ 565 SGW_FollowMeHomeTimeSet 4;
BA_ "GenSigSendType" SG_ 565 SGW_TaxiArriveSts 4;
BA_ "GenSigStartValue" SG_ 565 SGW_BookingCarReq 2;
BA_ "GenSigSendType" SG_ 565 SGW_BookingCarReq 4;
BA_ "GenSigSendType" SG_ 565 SGW_HazardWarnReq 4;
BA_ "GenSigSendType" SG_ 565 SGW_FollowMeHomeSet 4;
BA_ "GenSigInvalidValue" SG_ 571 SGW_TimingChargeEndhour 31;
BA_ "GenSigInvalidValue" SG_ 571 SGW_TimingChargeEndminute 63;
BA_ "GenSigInvalidValue" SG_ 571 SGW_TimingChargeStarthour 31;
BA_ "GenSigInvalidValue" SG_ 571 SGW_TimingChargeStartminute 63;
BA_ "GenSigStartValue" SG_ 692 IVI_WCBSReminderSet 1;
BA_ "GenSigSendType" SG_ 561 IVI_ESCOffSet 4;
BA_ "GenSigSendType" SG_ 561 IVI_TPMS_Reset 4;
BA_ "GenSigSendType" SG_ 561 IVI_HDCOffSet 4;
BA_ "GenSigSendType" SG_ 561 IVI_AVHSet 4;
BA_ "GenSigSendType" SG_ 561 IVI_SteeringModeSet 4;
BA_ "GenSigSendType" SG_ 561 IVI_BrakeCompensateCmd 4;
BA_ "GenSigSendType" SG_ 561 IVI_CRLevelSet 4;
BA_ "GenSigSendType" SG_ 693 IVI_AppointChargeCmd 4;
BA_ "GenSigSendType" SG_ 693 IVI_ForwardVmaxlimitSw 4;
BA_ "GenSigSendType" SG_ 693 IVI_KeepWarmRequest 4;
BA_ "GenSigSendType" SG_ 693 IVI_LockACPlug 4;
BA_ "GenSigSendType" SG_ 693 IVI_LV_LimitPop 4;
BA_ "GenSigInvalidValue" SG_ 694 IVI_GearRequest 5;
BA_ "GenSigSendType" SG_ 694 IVI_GearRequest 4;
BA_ "GenSigInvalidValue" SG_ 261 SGW_RemoteAirCondOnOFFReq 3;
BA_ "GenSigSendType" SG_ 261 SGW_RemoteAirCondOnOFFReq 4;
BA_ "GenSigSendType" SG_ 261 SGW_RemoteAirCondAUTOReq 4;
BA_ "GenSigInvalidValue" SG_ 261 SGW_RemoteFrontDefrostReq 3;
BA_ "GenSigSendType" SG_ 261 SGW_RemoteFrontDefrostReq 4;
BA_ "GenSigSendType" SG_ 261 SGW_FrontDoorAngleSet 4;
BA_ "GenSigSendType" SG_ 261 SGW_RearDoorAngleSet 4;
BA_ "GenSigSendType" SG_ 261 SGW_RemoteDrSeatHeatReq 4;
BA_ "GenSigInvalidValue" SG_ 261 SGW_RemoteSteerHeatReq 3;
BA_ "GenSigSendType" SG_ 261 SGW_RemoteSteerHeatReq 4;
BA_ "GenSigSendType" SG_ 261 SGW_RemotePassSeatHeatReq 4;
BA_ "GenSigSendType" SG_ 261 SGW_RearDefrostCtrlSet 4;
BA_ "GenSigInvalidValue" SG_ 261 SGW_RemoteRearMirHeatReq 3;
BA_ "GenSigSendType" SG_ 261 SGW_RemoteRearMirHeatReq 4;
BA_ "GenSigInvalidValue" SG_ 261 SGW_RemoteFrontWindHeatReq 3;
BA_ "GenSigSendType" SG_ 261 SGW_RemoteFrontWindHeatReq 4;
BA_ "GenSigInvalidValue" SG_ 261 SGW_RemoteRearWindHeatReq 3;
BA_ "GenSigSendType" SG_ 261 SGW_RemoteRearWindHeatReq 4;
BA_ "GenSigSendType" SG_ 261 SGW_oneTouchCoolSet 4;
BA_ "GenSigSendType" SG_ 261 SGW_TakePicCtrl 4;
BA_ "GenSigSendType" SG_ 261 SGW_RemoteTailgateLockCtrlReq 4;
BA_ "GenSigSendType" SG_ 261 SGW_RemoteACOnOffReq 4;
BA_ "GenSigSendType" SG_ 261 SGW_LeftChdLockCtrlReq 4;
BA_ "GenSigSendType" SG_ 261 SGW_RightChdLockCtrlReq 4;
BA_ "GenSigSendType" SG_ 263 SGW_RemoteDrvSetTempSteplsReq 4;
BA_ "GenSigSendType" SG_ 263 SGW_RemotePassSetTempSteplsReq 4;
BA_ "GenSigSendType" SG_ 263 SGW_RemoteCarSearchReq 4;
BA_ "GenSigSendType" SG_ 263 SGW_AllDoorReq 4;
BA_ "GenSigSendType" SG_ 263 SGW_FLDoorReq 4;
BA_ "GenSigSendType" SG_ 263 SGW_FRDoorReq 4;
BA_ "GenSigSendType" SG_ 263 SGW_RLDoorReq 4;
BA_ "GenSigSendType" SG_ 263 SGW_RRDoorReq 4;
BA_ "GenSigSendType" SG_ 263 SGW_FLWinPosiCtlCmd 4;
BA_ "GenSigSendType" SG_ 263 SGW_FRWinPosiCtlCmd 4;
BA_ "GenSigSendType" SG_ 263 SGW_RLWinPosiCtlCmd 4;
BA_ "GenSigSendType" SG_ 263 SGW_RRWinPosiCtlCmd 4;
BA_ "GenSigSendType" SG_ 562 SGW_DrvSetTempSteplsReq 4;
BA_ "GenSigSendType" SG_ 562 SGW_DemistReq 4;
BA_ "GenSigSendType" SG_ 562 SGW_HVACBatterySaveModeSetReq 4;
BA_ "GenSigSendType" SG_ 562 SGW_PassSetTempSteplsReq 4;
BA_ "GenSigSendType" SG_ 562 SGW_AirCondAUTOReq 4;
BA_ "GenSigSendType" SG_ 562 SGW_DualReq 4;
BA_ "GenSigSendType" SG_ 562 SGW_AirDistributionModeReq 4;
BA_ "GenSigSendType" SG_ 562 SGW_FrontDefrostReq 4;
BA_ "GenSigSendType" SG_ 562 SGW_AqsReq 4;
BA_ "GenSigSendType" SG_ 562 SGW_ClimateSystemStsReq 4;
BA_ "GenSigSendType" SG_ 562 SGW_ACCmprStsReq 4;
BA_ "GenSigSendType" SG_ 562 SGW_AirCirclnReq 4;
BA_ "GenSigSendType" SG_ 562 SGW_BlowersteplsSpdReq 4;
BA_ "GenSigSendType" SG_ 562 SGW_PresetModeEnable 4;
BA_ "GenSigSendType" SG_ 562 SGW_PresetModeReq 4;
BA_ "GenSigSendType" SG_ 562 SGW_VentilationModeReq 4;
BA_ "GenSigSendType" SG_ 562 SGW_AirCondEcoSet 4;
BA_ "GenSigStartValue" SG_ 564 SGW_TimeInfoDay 1;
BA_ "GenSigStartValue" SG_ 564 SGW_TimeInfoMonth 1;
BA_ "GenSigStartValue" SG_ 564 SGW_TimeValid 1;
BA_ "GenSigSendType" SG_ 560 IVI_DschrgOnOffSet 4;
BA_ "GenSigSendType" SG_ 560 IVI_DriveModeSet 4;
BA_ "GenSigSendType" SG_ 560 IVI_ForwardVmaxAllowed 4;
BA_ "GenSigInvalidValue" SG_ 560 IVI_MaxChrgSocSet 255;
BA_ "GenSigStartValue" SG_ 560 IVI_MaxChrgSocSet 254;
BA_ "GenSigSendType" SG_ 560 IVI_MaxChrgSocSet 4;
BA_ "GenSigInvalidValue" SG_ 560 IVI_V2LidisSet 255;
BA_ "GenSigStartValue" SG_ 560 IVI_V2LidisSet 254;
BA_ "GenSigSendType" SG_ 560 IVI_V2LidisSet 4;
BA_ "GenSigInvalidValue" SG_ 609 TCU_HVCHHighVoltage 509;
BA_ "GenSigInvalidValue" SG_ 609 TCU_HVCHHVDCCurrent 255;
BA_ "GenSigStartValue" SG_ 610 TCU_CabinTemperature 70;
BA_ "GenSigInvalidValue" SG_ 768 TCU_CoolantLowWarnReq 3;
BA_ "GenSigInvalidValue" SG_ 768 TCU_FreonLowWarnReq 3;
BA_ "GenSigInvalidValue" SG_ 793 VCU_BS_IBSBatSOC 255;
BA_ "GenSigStartValue" SG_ 793 VCU_BS_IBSBatSOC 80;
BA_ "GenSigInvalidValue" SG_ 549 VCU_ChargeEnergy 1023;
BA_ "GenSigInvalidValue" SG_ 210 MessageCounter_0D2 15;
BA_ "GenSigInvalidValue" SG_ 209 MessageCounter_0D1 15;
BA_ "GenSigStartValue" SG_ 209 VCU_IsoMeasurementSwitch 1;
BA_ "GenSigInvalidValue" SG_ 209 VCU_RequestedModeBMS 7;
BA_ "GenSigInvalidValue" SG_ 792 MessageCounter_318 15;
BA_ "GenSigInvalidValue" SG_ 792 VCU_maxChargeSOC 255;
BA_ "GenSigStartValue" SG_ 792 VCU_maxChargeSOC 255;
BA_ "GenSigStartValue" SG_ 792 VCU_DischargeEndSoc 50;
BA_ "GenSigStartValue" SG_ 795 VCU_BS_HCurrent 65535;
BA_ "GenSigInvalidValue" SG_ 795 VCU_BS_HCurrent 65535;
BA_ "GenSigStartValue" SG_ 795 VCU_BS_QuiescentCurrent 255;
BA_ "GenSigInvalidValue" SG_ 150 VCU_MotorSpdReq 65535;
BA_ "GenSigStartValue" SG_ 150 VCU_MotorSpdReq 32767;
BA_ "GenSigInvalidValue" SG_ 150 VCU_MaxSpdLimit 65535;
BA_ "GenSigStartValue" SG_ 150 VCU_MaxSpdLimit 32767;
BA_ "GenSigInvalidValue" SG_ 149 MessageCounter_095 15;
BA_ "GenSigInvalidValue" SG_ 149 VCU_BrakepedalStatus 2;
BA_ "GenSigStartValue" SG_ 289 VCU_Enable_DC_Relay 1;
BA_ "GenSigStartValue" SG_ 289 VCU_OBC_Control_of_S2_SW 1;
BA_ "GenSigStartValue" SG_ 289 VCU_OBC_Control_of_em_lock 1;
BA_ "GenSigStartValue" SG_ 319 VCU_SynRequest 16777215;
BA_ "GenSigSendType" SG_ 319 VCU_SynRequest 2;
BA_ "GenSigSendType" SG_ 2047 ALL_DiagReq 2;
BA_ "GenSigSendType" SG_ 2015 FUN_DiagReq 2;
BA_ "GenSigSendType" SG_ 1843 OBD_DiagReq 2;
BA_ "GenSigSendType" SG_ 2016 VCU_OBD_DiagReq 2;
BA_ "GenSigSendType" SG_ 2024 VCU_OBD_DiagResp 2;
BA_ "GenSigSendType" SG_ 2026 PT_DiagReq 2;
BA_ "GenSigSendType" SG_ 1991 POD_DiagReq 2;
BA_ "GenSigSendType" SG_ 1939 BMS_DiagReq 2;
BA_ "GenSigSendType" SG_ 1992 TCU_DiagReq 2;
BA_ "GenSigSendType" SG_ 1998 AIRPTC_DiagReq 2;
BA_ "GenSigSendType" SG_ 1964 VCU_DiagReq 2;
BA_ "GenSigSendType" SG_ 1986 MCU_DiagReq 2;
BA_ "GenSigSendType" SG_ 1999 PRND_DiagReq 2;
BA_ "GenSigSendType" SG_ 1993 EVCOM_DiagReq 2;
BA_ "GenSigSendType" SG_ 1863 POD_DiagResp 2;
BA_ "GenSigSendType" SG_ 1811 BMS_DiagResp 2;
BA_ "GenSigSendType" SG_ 1864 TCU_DiagResp 2;
BA_ "GenSigSendType" SG_ 1870 AIRPTC_DiagResp 2;
BA_ "GenSigSendType" SG_ 1836 VCU_DiagResp 2;
BA_ "GenSigSendType" SG_ 1858 MCU_DiagResp 2;
BA_ "GenSigSendType" SG_ 1871 PRND_DiagResp 2;
BA_ "GenSigSendType" SG_ 1865 EVCOM_DiagResp 2;
VAL_ 787 POD_OBC_ACPortTempASensValid 0 "Damage" 1 "Short Circuit" 2 "Normal" ;
VAL_ 787 POD_OBC_ACPortTempBSensValid 0 "Damage" 1 "Short Circuit" 2 "Normal" ;
VAL_ 787 POD_OBC_ACPortTempAerror 0 "No Fault" 1 "Fault" ;
VAL_ 787 POD_OBC_ACPortTempBerror 0 "No Fault" 1 "Fault" ;
VAL_ 787 POD_OBC_FaultLevel 0 "No Fault" 1 "Level1" 2 "Level2" 3 "Level3" ;
VAL_ 787 POD_OBC_DCVoltHighFault 0 "No Fault" 1 "Fault" ;
VAL_ 787 POD_OBC_StartUpAllowed 0 "No Fault" 1 "Fault" ;
VAL_ 787 POD_OBC_CommunFault 0 "No Fault" 1 "Fault" ;
VAL_ 787 POD_OBC_DCCurHighFault 0 "No Fault" 1 "Fault" ;
VAL_ 787 POD_OBC_ACVoltHighFault 0 "No Fault" 1 "Fault" ;
VAL_ 787 POD_OBC_ACVoltLowFault 0 "No Fault" 1 "Fault" ;
VAL_ 787 POD_OBC_NlineStatus 0 "No Fault" 1 "Fault" ;
VAL_ 787 POD_OBC_OutputoverloadFault 0 "No Fault" 1 "Fault" ;
VAL_ 787 POD_OBC_InputFrequencyStatus 0 "No Fault" 1 "Fault" ;
VAL_ 787 POD_OBC_InputPhaseStatus 0 "No Fault" 1 "Fault" ;
VAL_ 787 POD_OBC_InputOverCurrentstatus_R 0 "No Fault" 1 "Fault" ;
VAL_ 787 POD_OBC_InputOverCurrentstatus_S 0 "No Fault" 1 "Fault" ;
VAL_ 787 POD_OBC_InputOverCurrentstatus_T 0 "No Fault" 1 "Fault" ;
VAL_ 787 POD_OBC_PFCUnderVoltageError 0 "No Fault" 1 "Fault" ;
VAL_ 787 POD_OBC_PFCOverVoltageError 0 "No Fault" 1 "Fault" ;
VAL_ 787 POD_OBC_OutputShortError 0 "No Fault" 1 "Fault" ;
VAL_ 787 POD_OBC_Side1Overtempfault 0 "No Fault" 1 "Fault" ;
VAL_ 787 POD_OBC_Side2Overtempfault 0 "No Fault" 1 "Fault" ;
VAL_ 787 POD_OBC_InternalFault 0 "No Fault" 1 "Fault" ;
VAL_ 787 POD_OBC_DCVoltLowFault 0 "No Fault" 1 "Fault" ;
VAL_ 787 POD_OBC_InputShortError 0 "No Fault" 1 "Fault" ;
VAL_ 787 POD_DCDC_CommunFault 0 "No Fault" 1 "Fault" ;
VAL_ 787 OBC_OutputIsolatedFault 0 "No Fault" 1 "Fault" ;
VAL_ 577 POD_DCPortInletTempBValid 0 "Damage" 1 "Short Circuit" 2 "normal" ;
VAL_ 577 POD_DCPortInletTempAValid 0 "Damage" 1 "Short Circuit" 2 "normal" ;
VAL_ 577 POD_DCPosRelayState 0 "Close" 1 "Open" 2 "Error" ;
VAL_ 577 POD_KL30Error 0 "No Fault" 1 "Fault" ;
VAL_ 577 POD_T15e_fault 0 "No Fault" 1 "Fault" ;
VAL_ 577 POD_CANBusoff 0 "No Fault" 1 "Fault" ;
VAL_ 577 POD_TempHighFault 0 "No Fault" 1 "Fault" ;
VAL_ 577 POD_TempSensor1Fault 0 "No Fault" 1 "Fault" ;
VAL_ 584 MessageCounter_248 15 "Invalid" ;
VAL_ 584 PRND_RNDbutton 0 "NO_TARGET" 1 "R" 2 "N" 3 "D" 4 "RESERVE" 5 "RESERVE" 6 "RESERVE" 7 "RESERVE" ;
VAL_ 584 PRND_Pbutton 0 "Not Pressed" 1 "Pressed" 2 "Held" 3 "reserved" ;
VAL_ 584 PRND_Pbutton_FaultSts 0 "No Fault" 1 "Fault" ;
VAL_ 584 PRND_RNDbutton_FaultSts 0 "No Fault" 1 "Fault" ;
VAL_ 572 SGW_TimingChargeSwitchStatus 0 "Init" 1 "ON" 2 "OFF" ;
VAL_ 572 SGW_RemoteChrgFlapLockCtrlReq 0 "NO_REQUEST" 1 "UNLOCK" 2 "LOCK" 3 "Reserved" ;
VAL_ 572 SGW_RelockSet 0 "NO_COMMAND" 1 "INACTIVE" 2 "30s" 3 "60s" 4 "Reserved" 5 "Reserved" ;
VAL_ 572 SGW_RemoteActiveHorn 0 "No Request" 1 "Active" ;
VAL_ 572 SGW_ChargeFormSet 0 "Init" 1 "ChargeImmediately" 2 "Appointment charging" ;
VAL_ 572 SGW_TimingChargefrquency 0 "Init" 1 "once" 2 "everyday" ;
VAL_ 572 SGW_AppointChargeCmd 0 "Init" 1 "Charge ON" 2 "Charge OFF" ;
VAL_ 572 SGW_DschrgOnOffSet 0 "NO_COMMAND" 1 "OFF" 2 "ON" 3 "INVALID" ;
VAL_ 572 SGW_LockACPlug 0 "Init" 1 "Lock" 2 "Unlock" ;
VAL_ 572 SGW_HoodlockSet 0 "No Request" 1 "Unlock" ;
VAL_ 565 SGW_AlarmEnableSet 0 "No request" 1 "Disable" 2 "Enable" ;
VAL_ 565 SGW_ALM_MusicFrequencySet 0 "NO Request" 1 "OFF" 2 "ON" 3 "Reserved" ;
VAL_ 565 SGW_RemoteHVCtrlReq 0 "NO_REQUEST" 1 "HV_ON" 2 "HV_OFF" ;
VAL_ 565 SGW_FL_BackrestMotorReq 0 "Noactive" 1 "Front" 2 "Rear" ;
VAL_ 565 SGW_DomeLampBrightSet 0 "No request" 1 "50%" 2 "100%" ;
VAL_ 565 SGW_FL_FrontRearReq 0 "Noactive" 1 "Front" 2 "Rear" ;
VAL_ 565 SGW_FL_HeightMotorReq 0 "Noactive" 1 "Up" 2 "Down" ;
VAL_ 565 SGW_WelLightshowOnOffSet 0 "NO Request" 1 "OFF" 2 "ON" 3 "Reserved" ;
VAL_ 565 SGW_TaxiArrIllReq 0 "NO Request" 1 "OFF" 2 "ON" 3 "AUTO" ;
VAL_ 565 SGW_TaxiArriveSts 0 "No request" 1 "Not arrived" 2 "Arrived" ;
VAL_ 565 SGW_BookingCarReq 0 "Booking" 1 "Cancel" 2 "No request" ;
VAL_ 565 SGW_HazardWarnReq 0 "No Request" 1 "Off" 2 "On" ;
VAL_ 565 SGW_FollowMeHomeSet 0 "No request" 1 "OFF" 2 "ON" 3 "Reserved" ;
VAL_ 692 IVI_MirrorInterfaceMode 0 "Normal" 1 "Tilt" ;
VAL_ 692 IVI_VrState 0 "Inactive" 1 "Active" ;
VAL_ 692 IVI_WCBSReminderSet 0 "Forbidden State" 1 "Enabled State" ;
VAL_ 561 IVI_ESCOffSet 0 "NO Request" 1 "OFF" 2 "ON" 3 "Reserved" ;
VAL_ 561 IVI_TPMS_Reset 0 "No request" 1 "Active" ;
VAL_ 561 IVI_HDCOffSet 0 "No Request" 1 "OFF" 2 "ON" 3 "RESERVED" ;
VAL_ 561 IVI_AVHSet 0 "No Request" 1 "OFF" 2 "ON" 3 "RESERVED" ;
VAL_ 561 IVI_SteeringModeSet 0 "No Request" 1 "Normal" 2 "Sport" 3 "Comfort" ;
VAL_ 561 IVI_BrakeCompensateCmd 0 "NO Request" 1 "OFF" 2 "ON" 3 "Reserved" ;
VAL_ 561 IVI_CRLevelSet 0 "No request" 1 "OFF" 2 "Primary energy recovery (weak)" 3 "Secondary energy recovery(medium)" 4 "Tertiary energy recovery (strong)" 5 "Reserved" 6 "Reserved" 7 "Reserved" ;
VAL_ 944 IVI_OdometerInforValid 0 "Invalid" 1 "Valid" ;
VAL_ 693 IVI_AppointChargeCmd 0 "No Request" 1 "Charge ON" 2 "Charge OFF" ;
VAL_ 693 IVI_ForwardVmaxlimitSw 0 "No Request" 1 "OFF" 2 "ON" 3 "Reserved" ;
VAL_ 693 IVI_KeepWarmRequest 0 "No request" 1 "OFF" 2 "ON" ;
VAL_ 693 IVI_LockACPlug 0 "No request" 1 "UnLock" 2 "Lock" ;
VAL_ 693 IVI_LV_LimitPop 0 "No request" 1 "Cancel" 2 "Open" ;
VAL_ 694 IVI_GearRequest 0 "NO request" 1 "P" 2 "N" 3 "R" 4 "D" 5 "Invaild" ;
VAL_ 261 SGW_RemoteAirCondOnOFFReq 0 "No action" 1 "On" 2 "Off" 3 "INVALID" ;
VAL_ 261 SGW_RemoteAirCondAUTOReq 0 "No action" 1 "Pressed" 2 "Reserved" 3 "Reserved" ;
VAL_ 261 SGW_RemoteFrontDefrostReq 0 "No action" 1 "On" 2 "Off" 3 "INVALID" ;
VAL_ 261 SGW_FrontDoorAngleSet 0 "No Request" 1 "75°" 2 "35°" ;
VAL_ 261 SGW_RearDoorAngleSet 0 "No Request" 1 "75°" 2 "35°" ;
VAL_ 261 SGW_RemoteDrSeatHeatReq 0 "No Request" 1 "Seat Heat Off" 2 "Level1" 3 "Level2" 4 "Level3" ;
VAL_ 261 SGW_RemoteSteerHeatReq 0 "No Request" 1 "OFF" 2 "ON" 3 "INVALID" ;
VAL_ 261 SGW_RemotePassSeatHeatReq 0 "No Request" 1 "Seat Heat Off" 2 "Level1" 3 "Level2" 4 "Level3" ;
VAL_ 261 SGW_RearDefrostCtrlSet 0 "OFF" 1 "ON" ;
VAL_ 261 SGW_RemoteRearMirHeatReq 0 "NO_COMMAND" 1 "OFF" 2 "ON" 3 "INVALID" ;
VAL_ 261 SGW_RemoteFrontWindHeatReq 0 "NO_COMMAND" 1 "OFF" 2 "ON" 3 "INVALID" ;
VAL_ 261 SGW_RemoteRearWindHeatReq 0 "NO_COMMAND" 1 "OFF" 2 "ON" 3 "INVALID" ;
VAL_ 261 SGW_oneTouchCoolSet 0 "No Request" 1 "Open" 2 "Close" ;
VAL_ 261 SGW_TakePicCtrl 0 "No Request" 1 "DVR photo" 2 "ROA photo" 3 "DMS photo" 4 "DVR video" 5 "ROA video" 6 "DMS VIdeo" 7 "Reserved" ;
VAL_ 261 SGW_RemoteTailgateLockCtrlReq 0 "No Request" 1 "Unlock" 2 "Lock" 3 "Reserved" ;
VAL_ 261 SGW_RemoteACOnOffReq 0 "NO_REQUEST" 1 "OFF" 2 "ON" ;
VAL_ 261 SGW_LeftChdLockCtrlReq 0 "No request" 1 "Deactive" 2 "Active" ;
VAL_ 261 SGW_RightChdLockCtrlReq 0 "No request" 1 "Deactive" 2 "Active" ;
VAL_ 263 SGW_RemoteDrvSetTempSteplsReq 0 "No request" 1 "17(Low)" 2 "17.5" 3 "18" 4 "18.5" 5 "19" 6 "19.5" 7 "20" 8 "20.5" 9 "21" 10 "21.5" 11 "22" 12 "22.5" 13 "23" 14 "23.5" 15 "24" 16 "24.5" 17 "25" 18 "25.5" 19 "26" 20 "26.5" 21 "27" 22 "27.5" 23 "28(High)" 24 "Reserved" 25 "Reserved" 26 "Reserved" 27 "Reserved" 28 "Reserved" 29 "Reserved" 30 "Reserved" 31 "Reserved" 32 "Reserved" 33 "Reserved" 34 "Reserved" 35 "Reserved" 36 "Reserved" 37 "Reserved" 38 "Reserved" 39 "Reserved" 40 "Reserved" 41 "Reserved" 42 "Reserved" 43 "Reserved" 44 "Reserved" 45 "Reserved" 46 "Reserved" 47 "Reserved" 48 "Reserved" 49 "Reserved" 50 "Reserved" 51 "Reserved" 52 "Reserved" 53 "Reserved" 54 "Reserved" 55 "Reserved" 56 "Reserved" 57 "Reserved" 58 "Reserved" 59 "Reserved" 60 "Reserved" 61 "Reserved" 62 "Reserved" 63 "Reserved" ;
VAL_ 263 SGW_RemotePassSetTempSteplsReq 0 "No request" 1 "17(Low)" 2 "17.5" 3 "18" 4 "18.5" 5 "19" 6 "19.5" 7 "20" 8 "20.5" 9 "21" 10 "21.5" 11 "22" 12 "22.5" 13 "23" 14 "23.5" 15 "24" 16 "24.5" 17 "25" 18 "25.5" 19 "26" 20 "26.5" 21 "27" 22 "27.5" 23 "28(High)" 24 "Reserved" 25 "Reserved" 26 "Reserved" 27 "Reserved" 28 "Reserved" 29 "Reserved" 30 "Reserved" 31 "Reserved" 32 "Reserved" 33 "Reserved" 34 "Reserved" 35 "Reserved" 36 "Reserved" 37 "Reserved" 38 "Reserved" 39 "Reserved" 40 "Reserved" 41 "Reserved" 42 "Reserved" 43 "Reserved" 44 "Reserved" 45 "Reserved" 46 "Reserved" 47 "Reserved" 48 "Reserved" 49 "Reserved" 50 "Reserved" 51 "Reserved" 52 "Reserved" 53 "Reserved" 54 "Reserved" 55 "Reserved" 56 "Reserved" 57 "Reserved" 58 "Reserved" 59 "Reserved" 60 "Reserved" 61 "Reserved" 62 "Reserved" 63 "Reserved" ;
VAL_ 263 SGW_RemoteCarSearchReq 0 "NO_REQUEST" 1 "OFF" 2 "ON" 3 "Reserved" ;
VAL_ 263 SGW_AllDoorReq 0 "No request" 1 "Open" 2 "Closed" ;
VAL_ 263 SGW_FLDoorReq 0 "No request" 1 "Open" 2 "Closed" ;
VAL_ 263 SGW_FRDoorReq 0 "No request" 1 "Open" 2 "Closed" ;
VAL_ 263 SGW_RLDoorReq 0 "No request" 1 "Open" 2 "Closed" ;
VAL_ 263 SGW_RRDoorReq 0 "No request" 1 "Open" 2 "Closed" ;
VAL_ 263 SGW_FLWinPosiCtlCmd 0 "No Request" 1 "0%" 2 "5%" 3 "10%" 4 "15%" 5 "20%" 6 "25%" 7 "30%" 8 "35%" 9 "40%" 10 "45%" 11 "50%" 12 "55%" 13 "60%" 14 "65%" 15 "70%" 16 "75%" 17 "80%" 18 "85%" 19 "90%" 20 "95%" 21 "100%" ;
VAL_ 263 SGW_FRWinPosiCtlCmd 0 "No Request" 1 "0%" 2 "5%" 3 "10%" 4 "15%" 5 "20%" 6 "25%" 7 "30%" 8 "35%" 9 "40%" 10 "45%" 11 "50%" 12 "55%" 13 "60%" 14 "65%" 15 "70%" 16 "75%" 17 "80%" 18 "85%" 19 "90%" 20 "95%" 21 "100%" ;
VAL_ 263 SGW_RLWinPosiCtlCmd 0 "No Request" 1 "0%" 2 "5%" 3 "10%" 4 "15%" 5 "20%" 6 "25%" 7 "30%" 8 "35%" 9 "40%" 10 "45%" 11 "50%" 12 "55%" 13 "60%" 14 "65%" 15 "70%" 16 "75%" 17 "80%" 18 "85%" 19 "90%" 20 "95%" 21 "100%" ;
VAL_ 263 SGW_RRWinPosiCtlCmd 0 "No Request" 1 "0%" 2 "5%" 3 "10%" 4 "15%" 5 "20%" 6 "25%" 7 "30%" 8 "35%" 9 "40%" 10 "45%" 11 "50%" 12 "55%" 13 "60%" 14 "65%" 15 "70%" 16 "75%" 17 "80%" 18 "85%" 19 "90%" 20 "95%" 21 "100%" ;
VAL_ 562 SGW_DrvSetTempSteplsReq 0 "No request" 1 "17(Low)" 2 "17.5" 3 "18" 4 "18.5" 5 "19" 6 "19.5" 7 "20" 8 "20.5" 9 "21" 10 "21.5" 11 "22" 12 "22.5" 13 "23" 14 "23.5" 15 "24" 16 "24.5" 17 "25" 18 "25.5" 19 "26" 20 "26.5" 21 "27" 22 "27.5" 23 "28(High)" 24 "Reserved" 25 "Reserved" 26 "Reserved" 27 "Reserved" 28 "Reserved" 29 "Reserved" 30 "Reserved" 31 "Reserved" 32 "Reserved" 33 "Reserved" 34 "Reserved" 35 "Reserved" 36 "Reserved" 37 "Reserved" 38 "Reserved" 39 "Reserved" 40 "Reserved" 41 "Reserved" 42 "Reserved" 43 "Reserved" 44 "Reserved" 45 "Reserved" 46 "Reserved" 47 "Reserved" 48 "Reserved" 49 "Reserved" 50 "Reserved" 51 "Reserved" 52 "Reserved" 53 "Reserved" 54 "Reserved" 55 "Reserved" 56 "Reserved" 57 "Reserved" 58 "Reserved" 59 "Reserved" 60 "Reserved" 61 "Reserved" 62 "Reserved" 63 "Reserved" ;
VAL_ 562 SGW_DemistReq 0 "NO Request" 1 "Off" 2 "On" 3 "Reserved" ;
VAL_ 562 SGW_HVACBatterySaveModeSetReq 0 "NO Request" 1 "Off" 2 "On" 3 "Reserved" ;
VAL_ 562 SGW_PassSetTempSteplsReq 0 "No request" 1 "17(Low)" 2 "17.5" 3 "18" 4 "18.5" 5 "19" 6 "19.5" 7 "20" 8 "20.5" 9 "21" 10 "21.5" 11 "22" 12 "22.5" 13 "23" 14 "23.5" 15 "24" 16 "24.5" 17 "25" 18 "25.5" 19 "26" 20 "26.5" 21 "27" 22 "27.5" 23 "28(High)" 24 "Reserved" 25 "Reserved" 26 "Reserved" 27 "Reserved" 28 "Reserved" 29 "Reserved" 30 "Reserved" 31 "Reserved" 32 "Reserved" 33 "Reserved" 34 "Reserved" 35 "Reserved" 36 "Reserved" 37 "Reserved" 38 "Reserved" 39 "Reserved" 40 "Reserved" 41 "Reserved" 42 "Reserved" 43 "Reserved" 44 "Reserved" 45 "Reserved" 46 "Reserved" 47 "Reserved" 48 "Reserved" 49 "Reserved" 50 "Reserved" 51 "Reserved" 52 "Reserved" 53 "Reserved" 54 "Reserved" 55 "Reserved" 56 "Reserved" 57 "Reserved" 58 "Reserved" 59 "Reserved" 60 "Reserved" 61 "Reserved" 62 "Reserved" 63 "Reserved" ;
VAL_ 562 SGW_AirCondAUTOReq 0 "No Request" 1 "Pressed" 2 "Reserved" 3 "Reserved" ;
VAL_ 562 SGW_DualReq 0 "No Request" 1 "Close" 2 "Open" 3 "Reserved" ;
VAL_ 562 SGW_AirDistributionModeReq 0 "No Request" 1 "Face" 2 "Bilevel(Foot face)" 3 "Foot" 4 "Foot Screen" 5 "Screen" 6 "Reserved" 7 "Reserved" ;
VAL_ 562 SGW_FrontDefrostReq 0 "NO Request" 1 "Off" 2 "On" 3 "Reserved" ;
VAL_ 562 SGW_AqsReq 0 "NO Request" 1 "Off" 2 "On" 3 "Reserved" ;
VAL_ 562 SGW_ClimateSystemStsReq 0 "NO Request" 1 "Off" 2 "On" 3 "Reserved" ;
VAL_ 562 SGW_ACCmprStsReq 0 "NO Request" 1 "Off" 2 "On" 3 "Reserved" ;
VAL_ 562 SGW_AirCirclnReq 0 "NO Request" 1 "Internal" 2 "External" 3 "Automatic" ;
VAL_ 562 SGW_BlowersteplsSpdReq 0 "No Request" 1 "Stepless Speed1_Low" 2 "Stepless Speed2" 3 "Stepless Speed3" 4 "Stepless Speed4" 5 "Stepless Speed5" 6 "Stepless Speed6" 7 "Stepless Speed7" 8 "Stepless Speed8_High" 9 "Reserved" 10 "Reserved" 11 "Reserved" 12 "Reserved" 13 "Reserved" 14 "Reserved" 15 "Reserved" ;
VAL_ 562 SGW_PresetModeEnable 0 "NO Request" 1 "Off" 2 "On" ;
VAL_ 562 SGW_PresetModeReq 0 "NO Request" 1 "Maximum heating" 2 "Foot heating" 3 "Hand heating" 4 "Rear seats MAX heat" 5 "Maximum cooling" 6 "Cooling foot and face areas" 7 "Rear Seats cooling" ;
VAL_ 562 SGW_VentilationModeReq 0 "NO Request" 1 "Off" 2 "On" ;
VAL_ 562 SGW_AirCondEcoSet 0 "NO Request" 1 "Off" 2 "On" 3 "Reserved" ;
VAL_ 564 SGW_TimeValid 0 "INVALID" 1 "VALID" ;
VAL_ 560 IVI_DschrgOnOffSet 0 "No Request" 1 "OFF" 2 "ON" 3 "Reserved" ;
VAL_ 560 IVI_DriveModeSet 0 "No Request" 1 "ECO" 2 "NORMAL" 3 "SPORT" 4 "OnePedal" ;
VAL_ 560 IVI_ForwardVmaxAllowed 0 "No request" 1 "1- 170" 2 "1- 170" 3 "1- 170" 4 "1- 170" 5 "1- 170" 6 "1- 170" 7 "1- 170" 8 "1- 170" 9 "1- 170" 10 "1- 170" 11 "1- 170" 12 "1- 170" 13 "1- 170" 14 "1- 170" 15 "1- 170" 16 "1- 170" 17 "1- 170" 18 "1- 170" 19 "1- 170" 20 "1- 170" 21 "1- 170" 22 "1- 170" 23 "1- 170" 24 "1- 170" 25 "1- 170" 26 "1- 170" 27 "1- 170" 28 "1- 170" 29 "1- 170" 30 "1- 170" 31 "1- 170" 32 "1- 170" 33 "1- 170" 34 "1- 170" 35 "1- 170" 36 "1- 170" 37 "1- 170" 38 "1- 170" 39 "1- 170" 40 "1- 170" 41 "1- 170" 42 "1- 170" 43 "1- 170" 44 "1- 170" 45 "1- 170" 46 "1- 170" 47 "1- 170" 48 "1- 170" 49 "1- 170" 50 "1- 170" 51 "1- 170" 52 "1- 170" 53 "1- 170" 54 "1- 170" 55 "1- 170" 56 "1- 170" 57 "1- 170" 58 "1- 170" 59 "1- 170" 60 "1- 170" 61 "1- 170" 62 "1- 170" 63 "1- 170" 64 "1- 170" 65 "1- 170" 66 "1- 170" 67 "1- 170" 68 "1- 170" 69 "1- 170" 70 "1- 170" 71 "1- 170" 72 "1- 170" 73 "1- 170" 74 "1- 170" 75 "1- 170" 76 "1- 170" 77 "1- 170" 78 "1- 170" 79 "1- 170" 80 "1- 170" 81 "1- 170" 82 "1- 170" 83 "1- 170" 84 "1- 170" 85 "1- 170" 86 "1- 170" 87 "1- 170" 88 "1- 170" 89 "1- 170" 90 "1- 170" 91 "1- 170" 92 "1- 170" 93 "1- 170" 94 "1- 170" 95 "1- 170" 96 "1- 170" 97 "1- 170" 98 "1- 170" 99 "1- 170" 100 "1- 170" 101 "1- 170" 102 "1- 170" 103 "1- 170" 104 "1- 170" 105 "1- 170" 106 "1- 170" 107 "1- 170" 108 "1- 170" 109 "1- 170" 110 "1- 170" 111 "1- 170" 112 "1- 170" 113 "1- 170" 114 "1- 170" 115 "1- 170" 116 "1- 170" 117 "1- 170" 118 "1- 170" 119 "1- 170" 120 "1- 170" 121 "1- 170" 122 "1- 170" 123 "1- 170" 124 "1- 170" 125 "1- 170" 126 "1- 170" 127 "1- 170" 128 "1- 170" 129 "1- 170" 130 "1- 170" 131 "1- 170" 132 "1- 170" 133 "1- 170" 134 "1- 170" 135 "1- 170" 136 "1- 170" 137 "1- 170" 138 "1- 170" 139 "1- 170" 140 "1- 170" 141 "1- 170" 142 "1- 170" 143 "1- 170" 144 "1- 170" 145 "1- 170" 146 "1- 170" 147 "1- 170" 148 "1- 170" 149 "1- 170" 150 "1- 170" 151 "1- 170" 152 "1- 170" 153 "1- 170" 154 "1- 170" 155 "1- 170" 156 "1- 170" 157 "1- 170" 158 "1- 170" 159 "1- 170" 160 "1- 170" 161 "1- 170" 162 "1- 170" 163 "1- 170" 164 "1- 170" 165 "1- 170" 166 "1- 170" 167 "1- 170" 168 "1- 170" 169 "1- 170" 170 "1- 170" 11 "Reserved" 12 "Reserved" 13 "Reserved" 14 "Reserved" 15 "Reserved" ;
VAL_ 560 IVI_MaxChrgSocSet 254 "No Request" 255 "Invalid" ;
VAL_ 560 IVI_V2LidisSet 254 "No Request" 255 "Invalid" ;
VAL_ 608 TCU_EVCompState 0 "off" 1 "running" 2 "limit" 3 "pre_heat" 4 "fault" 5 "reserved" 6 "reserved" 7 "reserved" ;
VAL_ 608 TCU_TMSState 0 "NotActive" 1 "Active" 2 "reserved" ;
VAL_ 608 TCU_TMSFaultLevel 0 "No Fault" 1 "Fault Level 1" 2 "Fault Level 2" 3 "Fault Level 3" 4 "Fault Level 4" 5 "Reserved" 6 "Reserved" 7 "Reserved" ;
VAL_ 608 TCU_HvOnReq 0 "No Request" 1 "Request" ;
VAL_ 608 TCU_HVCHState 0 "Default" 1 "OFF" 2 "ON" 3 "Reserved" ;
VAL_ 608 TCU_APTCState 0 "Default" 1 "OFF" 2 "ON" 3 "Reserved" ;
VAL_ 608 TCU_BattTMState 0 "sleep mode and no coolant flow" 1 "cooling mode" 2 "heating mode" 3 "pump only mode" 4 "exception mode" 5 "Reserved" 6 "Reserved" 7 "Reserved" ;
VAL_ 608 TCU_HVPwrState 0 "Default" 1 "OFF" 2 "ON" 3 "Reserved" ;
VAL_ 608 TCU_HVACACState 0 "Default" 1 "Auto" 2 "Manual" 3 "Reserved" ;
VAL_ 609 TCU_APTC1Enable 0 "Not Allowed" 1 "Allowed" ;
VAL_ 609 TCU_CompEnable 0 "Disabled" 1 "Enabled" ;
VAL_ 610 TCU_CabinTemperatureValid 0 "Invalid" 1 "Valid" ;
VAL_ 768 TCU_FrontDefrostSts 0 "OFF" 1 "ON" ;
VAL_ 768 TCU_AirCondAUTOSts 0 "OFF" 1 "ON" ;
VAL_ 768 TCU_AirCirclnSts 0 "Internal" 1 "External" 2 "AUTO" ;
VAL_ 768 TCU_AirCondEcoSetSts 0 "OFF" 1 "ON" ;
VAL_ 768 TCU_SelfDryingSetSts 0 "OFF" 1 "ON" ;
VAL_ 768 TCU_DrvTempSts 0 "17(Low)" 1 "17.5" 2 "18" 3 "18.5" 4 "19" 5 "19.5" 6 "20" 7 "20.5" 8 "21" 9 "21.5" 10 "22" 11 "22.5" 12 "23" 13 "23.5" 14 "24" 15 "24.5" 16 "25" 17 "25.5" 18 "26" 19 "26.5" 20 "27" 21 "27.5" 22 "28(High)" 23 "Reserved" 24 "Reserved" 25 "Reserved" 26 "Reserved" 27 "Reserved" 28 "Reserved" 29 "Reserved" 30 "Reserved" 31 "Reserved" 32 "Reserved" 33 "Reserved" 34 "Reserved" 35 "Reserved" 36 "Reserved" 37 "Reserved" 38 "Reserved" 39 "Reserved" 40 "Reserved" 41 "Reserved" 42 "Reserved" 43 "Reserved" 44 "Reserved" 45 "Reserved" 46 "Reserved" 47 "Reserved" 48 "Reserved" 49 "Reserved" 50 "Reserved" 51 "Reserved" 52 "Reserved" 53 "Reserved" 54 "Reserved" 55 "Reserved" 56 "Reserved" 57 "Reserved" 58 "Reserved" 59 "Reserved" 60 "Reserved" 61 "Reserved" 62 "Reserved" 63 "Reserved" ;
VAL_ 768 TCU_AqsSts 0 "OFF" 1 "ON" ;
VAL_ 768 TCU_DualSts 0 "Single" 1 "Dual" ;
VAL_ 768 TCU_PassTempSts 0 "17(Low)" 1 "17.5" 2 "18" 3 "18.5" 4 "19" 5 "19.5" 6 "20" 7 "20.5" 8 "21" 9 "21.5" 10 "22" 11 "22.5" 12 "23" 13 "23.5" 14 "24" 15 "24.5" 16 "25" 17 "25.5" 18 "26" 19 "26.5" 20 "27" 21 "27.5" 22 "28(High)" 23 "Reserved" 24 "Reserved" 25 "Reserved" 26 "Reserved" 27 "Reserved" 28 "Reserved" 29 "Reserved" 30 "Reserved" 31 "Reserved" 32 "Reserved" 33 "Reserved" 34 "Reserved" 35 "Reserved" 36 "Reserved" 37 "Reserved" 38 "Reserved" 39 "Reserved" 40 "Reserved" 41 "Reserved" 42 "Reserved" 43 "Reserved" 44 "Reserved" 45 "Reserved" 46 "Reserved" 47 "Reserved" 48 "Reserved" 49 "Reserved" 50 "Reserved" 51 "Reserved" 52 "Reserved" 53 "Reserved" 54 "Reserved" 55 "Reserved" 56 "Reserved" 57 "Reserved" 58 "Reserved" 59 "Reserved" 60 "Reserved" 61 "Reserved" 62 "Reserved" 63 "Reserved" ;
VAL_ 768 TCU_CoolantLowWarnReq 0 "No Fault" 1 "Fault" 2 "Reserved" 3 "Invalid" ;
VAL_ 768 TCU_FreonLowWarnReq 0 "No Fault" 1 "Fault" 2 "Reserved" 3 "Invalid" ;
VAL_ 768 TCU_BlowerSpdSts 0 "OFF" 1 "Stepless Speed1_Low" 2 "Stepless Speed2" 3 "Stepless Speed3" 4 "Stepless Speed4" 5 "Stepless Speed5" 6 "Stepless Speed6" 7 "Stepless Speed7" 8 "Stepless Speed8_High" 9 "Reserved" 10 "Reserved" 11 "Reserved" 12 "Reserved" 13 "Reserved" 14 "Reserved" 15 "Reserved" ;
VAL_ 768 TCU_AirDistributionModeSts 0 "Face" 1 "Bilevel(Foot face)" 2 "Foot" 3 "Foot Screen" 4 "Screen" 5 "Reserved" 6 "Reserved" 7 "Not set" ;
VAL_ 768 TCU_PresetModeSts 0 "OFF" 1 "Maximum heating" 2 "Foot heating" 3 "Hand heating" 4 "Rear seats MAX heat" 5 "Maximum cooling" 6 "Cooling foot and face areas" 7 "Rear Seats cooling" ;
VAL_ 768 TCU_VentilationModeSts 0 "OFF" 1 "ON" ;
VAL_ 768 TCU_HVACBatterySaveSts 0 "Inactive" 1 "Activate" ;
VAL_ 768 TCU_HVACBatterySaveModeSetSts 0 "OFF" 1 "ON" ;
VAL_ 768 TCU_ACCmprSts 0 "OFF" 1 "ON" ;
VAL_ 768 TCU_ClimateSystemSts 0 "OFF" 1 "ON" ;
VAL_ 768 TCU_PowerLimitSts 0 "No  Power Limit" 1 "Power Limit" ;
VAL_ 768 TCU_OutsideAQSLevel 0 "Clean air level" 1 "Level 1 Low increase in pollution" 2 "Level 2 Mild increase in pollution" 3 "Level 3 Significant increase in pollution" 4 "Level 4 High increase in pollution" 5 "Level 5 Very high increase in pollution" 6 "Error" 7 "Reserved" ;
VAL_ 768 TCU_WindowClosRemind 0 "No hint" 1 "Reminder to close windows" ;
VAL_ 768 TCU_DemistSts 0 "OFF" 1 "ON" ;
VAL_ 793 VCU_BS_IndicatorSts 0 "No request" 1 "Low SOH" ;
VAL_ 549 VCU_PermitPackPTC 0 "not permit" 1 "permit" ;
VAL_ 210 MessageCounter_0D2 15 "Invalid" ;
VAL_ 210 VCU_AccelerationPedalValid 0 "Invalid" 1 "Valid" ;
VAL_ 210 VCU_EPBReq 0 "Not Request" 1 "Apply Request" 2 "Release Request" 3 "Reserved" ;
VAL_ 210 VCU_Kickdown 0 "Invalid" 1 "Valid" ;
VAL_ 210 VCU_TargetGear 0 "Reserve" 1 "P" 2 "N" 3 "R" 4 "D" ;
VAL_ 210 VCU_VehicleSpeedValid 0 "invalid" 1 "valid" ;
VAL_ 210 VCU_VirtualACPedalValid 0 "Invalid" 1 "Valid" ;
VAL_ 210 VCU_VLCTorqueRequestActive 0 "Not Active" 1 "Active" ;
VAL_ 210 VCU_VLCTorqueRequestAvailable 0 "Not Available" 1 "Available" ;
VAL_ 209 MessageCounter_0D1 15 "Invalid" ;
VAL_ 209 VCU_IsoMeasurementSwitch 0 "OFF" 1 "ON" ;
VAL_ 209 VCU_RequestedModeBMS 0 "InActive" 1 "HVActive" 2 "Reserved" 3 "Reserved" 4 "Reserved" 5 "EmergencyOff" 6 "Reserved" 7 "Invalid" ;
VAL_ 209 VCU_HVStatus 0 "Init" 1 "Standby" 2 "HV Ready" 3 "Drive ready" 4 "Preheating" 5 "Sleep" ;
VAL_ 209 VCU_ChargeStatus 0 "Init" 1 "Off Plug" 2 "AC Plug Detected" 3 "DC Plug Detected" 4 "V2L Plug Detected" 5 "AC Charging" 6 "DC Charging" 7 "V2L Discharging" 8 "Charging Completed" 9 "Charging Fault" 10 "AC Preheating" 11 "DC Preheating" 12 "V2L completed" 13 "KeepWarming" 14 "V2L Fault" ;
VAL_ 209 VCU_LimitLevel 0 "level 0-No limit" 1 "level 1" 2 "level 2" 3 "level 3" ;
VAL_ 209 VCU_ActDriveMode 0 "INVALID" 1 "ECO" 2 "NORMAL" 3 "SPORT" 4 "OnePedal" ;
VAL_ 209 VCU_DrvModSwitchWarn 0 "RESERVE" 1 "unrecommed Sport-Low SOC" 2 "Vehicle not in P gear,single pedal unavailable" 3 "Vehicle failure, single pedal unavailable." 4 "Reserved" 5 "Reserved" 6 "Reserved" 7 "Reserved" ;
VAL_ 209 VCU_RegenBrakeLightReqVld 0 "INVALID" 1 "VALID" ;
VAL_ 209 VCU_RegenBrakeLightRequest 0 "Brake lights Off" 1 "Brake lights On" ;
VAL_ 209 VCU_BMSTargetThermLevel 0 "Level 1(low)" 1 "Level 2(medium)" 2 "Level 3(high)" 3 "Reserved" ;
VAL_ 209 VCU_BMS_Control_of_PosRelay 0 "Invaild" 1 "Open" 2 "Close" ;
VAL_ 544 VCU_VoltageDemandLV 510 "Init" 511 "Error" ;
VAL_ 544 VCU_RequestedModeDCDC 0 "OFF" 1 "Buck" 2 "Disable" ;
VAL_ 792 MessageCounter_318 15 "Invalid" ;
VAL_ 792 VCU_MCU_FaultLampReq 0 "No Request" 1 "Yellow-LED request" 2 "Red-LED request" 3 "Reserve" ;
VAL_ 792 VCU_SystemReady 0 "Not Ready" 1 "Ready" ;
VAL_ 792 VCU_maxChargeSOC 254 "No Request" 255 "Invalid" ;
VAL_ 792 VCU_ForwardVmaxAllowed 0 "No request" 1 "1-170" 2 "1-170" 3 "1-170" 4 "1-170" 5 "1-170" 6 "1-170" 7 "1-170" 8 "1-170" 9 "1-170" 10 "1-170" 11 "1-170" 12 "1-170" 13 "1-170" 14 "1-170" 15 "1-170" 16 "1-170" 17 "1-170" 18 "1-170" 19 "1-170" 20 "1-170" 21 "1-170" 22 "1-170" 23 "1-170" 24 "1-170" 25 "1-170" 26 "1-170" 27 "1-170" 28 "1-170" 29 "1-170" 30 "1-170" 31 "1-170" 32 "1-170" 33 "1-170" 34 "1-170" 35 "1-170" 36 "1-170" 37 "1-170" 38 "1-170" 39 "1-170" 40 "1-170" 41 "1-170" 42 "1-170" 43 "1-170" 44 "1-170" 45 "1-170" 46 "1-170" 47 "1-170" 48 "1-170" 49 "1-170" 50 "1-170" 51 "1-170" 52 "1-170" 53 "1-170" 54 "1-170" 55 "1-170" 56 "1-170" 57 "1-170" 58 "1-170" 59 "1-170" 60 "1-170" 61 "1-170" 62 "1-170" 63 "1-170" 64 "1-170" 65 "1-170" 66 "1-170" 67 "1-170" 68 "1-170" 69 "1-170" 70 "1-170" 71 "1-170" 72 "1-170" 73 "1-170" 74 "1-170" 75 "1-170" 76 "1-170" 77 "1-170" 78 "1-170" 79 "1-170" 80 "1-170" 81 "1-170" 82 "1-170" 83 "1-170" 84 "1-170" 85 "1-170" 86 "1-170" 87 "1-170" 88 "1-170" 89 "1-170" 90 "1-170" 91 "1-170" 92 "1-170" 93 "1-170" 94 "1-170" 95 "1-170" 96 "1-170" 97 "1-170" 98 "1-170" 99 "1-170" 100 "1-170" 101 "1-170" 102 "1-170" 103 "1-170" 104 "1-170" 105 "1-170" 106 "1-170" 107 "1-170" 108 "1-170" 109 "1-170" 110 "1-170" 111 "1-170" 112 "1-170" 113 "1-170" 114 "1-170" 115 "1-170" 116 "1-170" 117 "1-170" 118 "1-170" 119 "1-170" 120 "1-170" 121 "1-170" 122 "1-170" 123 "1-170" 124 "1-170" 125 "1-170" 126 "1-170" 127 "1-170" 128 "1-170" 129 "1-170" 130 "1-170" 131 "1-170" 132 "1-170" 133 "1-170" 134 "1-170" 135 "1-170" 136 "1-170" 137 "1-170" 138 "1-170" 139 "1-170" 140 "1-170" 141 "1-170" 142 "1-170" 143 "1-170" 144 "1-170" 145 "1-170" 146 "1-170" 147 "1-170" 148 "1-170" 149 "1-170" 150 "1-170" 151 "1-170" 152 "1-170" 153 "1-170" 154 "1-170" 155 "1-170" 156 "1-170" 157 "1-170" 158 "1-170" 159 "1-170" 160 "1-170" 161 "1-170" 162 "1-170" 163 "1-170" 164 "1-170" 165 "1-170" 166 "1-170" 167 "1-170" 168 "1-170" 169 "1-170" 170 "1-170" 171 "Reserved" 172 "Reserved" 173 "Reserved" 174 "Reserved" 175 "Reserved" 176 "Reserved" 177 "Reserved" 178 "Reserved" 179 "Reserved" 180 "Reserved" 181 "Reserved" 182 "Reserved" 183 "Reserved" 184 "Reserved" 185 "Reserved" 186 "Reserved" 187 "Reserved" 188 "Reserved" 189 "Reserved" 190 "Reserved" 191 "Reserved" 192 "Reserved" 193 "Reserved" 194 "Reserved" 195 "Reserved" 196 "Reserved" 197 "Reserved" 198 "Reserved" 199 "Reserved" 200 "Reserved" 201 "Reserved" 202 "Reserved" 203 "Reserved" 204 "Reserved" 205 "Reserved" 206 "Reserved" 207 "Reserved" 208 "Reserved" 209 "Reserved" 210 "Reserved" 211 "Reserved" 212 "Reserved" 213 "Reserved" 214 "Reserved" 215 "Reserved" 216 "Reserved" 217 "Reserved" 218 "Reserved" 219 "Reserved" 220 "Reserved" 221 "Reserved" 222 "Reserved" 223 "Reserved" 224 "Reserved" 225 "Reserved" 226 "Reserved" 227 "Reserved" 228 "Reserved" 229 "Reserved" 230 "Reserved" 231 "Reserved" 232 "Reserved" 233 "Reserved" 234 "Reserved" 235 "Reserved" 236 "Reserved" 237 "Reserved" 238 "Reserved" 239 "Reserved" 240 "Reserved" 241 "Reserved" 242 "Reserved" 243 "Reserved" 244 "Reserved" 245 "Reserved" 246 "Reserved" 247 "Reserved" 248 "Reserved" 249 "Reserved" 250 "Reserved" 251 "Reserved" 252 "Reserved" 253 "Reserved" 254 "Reserved" 255 "Reserved" ;
VAL_ 795 VCU_BS_QuiescentCurrent 255 "Invalid" 254 "Out of bounds" 253 "Overflow" ;
VAL_ 150 VCU_MCUActHeatPwr 254 "Init" 255 "Error" ;
VAL_ 149 MessageCounter_095 15 "Invalid" ;
VAL_ 149 VCU_PWTErrorLevel 0 "Fault Level0" 1 "Fault Level1" 2 "Fault Level2" 3 "Fault Level3" 4 "Fault Level4" 5 "Fault Level5" 6 "Fault Level6" 7 "Fault Level7" 8 "Fault Level8" 9 "Fault Level9" 10 "Fault Level10" 11 "Fault Level11" 12 "Fault Level12" 13 "Fault Level13" 14 "Fault Level14" 15 "Fault Level15" ;
VAL_ 149 VCU_MCUDesiredTorque 2046 "Init" 2047 "Error" ;
VAL_ 149 VCU_KL15eOn 0 "Off" 1 "On" ;
VAL_ 149 VCU_TCSActive 0 "NotActive" 1 "Active" ;
VAL_ 149 VCU_MCUSurgeDamperState 0 "DstC_off" 1 "DstC_ext" 2 "DstC_int_ext" ;
VAL_ 149 VCU_ActualGear 0 "Reserve" 1 "P" 2 "N" 3 "R" 4 "D" ;
VAL_ 149 VCU_BrakepedalStatus 0 "No pressed" 1 "pressed" 2 "Invalid" ;
VAL_ 149 VCU_RequestedModeMCU 0 "Ready" 1 "TrqCtrl" 2 "Active Hearting" 3 "Discharge" 4 "SpeedCtrl" ;
VAL_ 149 VCU_TrqThresholdDampgCtl 254 "Init" 255 "Error" ;
VAL_ 214 VCU_MaxTorqueGradient 16382 "Init" 16383 "Error" ;
VAL_ 214 VCU_MinTorqueLimit 2046 "Init" 2047 "Error" ;
VAL_ 214 VCU_MaxTorqueLimit 2046 "Init" 2047 "Error" ;
VAL_ 289 VCU_Enable_DC_Relay 0 "Close Request" 1 "Open Request" ;
VAL_ 289 VCU_OBC_Control_of_S2_SW 0 "Close" 1 "Open" ;
VAL_ 289 VCU_OBC_Control_of_em_lock 0 "Close" 1 "Open" ;
VAL_ 289 VCU_EnableOBC 0 "Reserve" 1 "Reserve" 2 "Enable" 3 "Disable" ;
VAL_ 545 VCU_RequestedModeTCU 0 "Init" 1 "Standby" 2 "Disable" 3 "Enable" ;
VAL_ 898 CGW_VERSION1 0 "concept" 1 "Sample A" 2 "Sample B" 3 "Sample C" 4 "Sample D" 5 "Sample SW" ;
VAL_ 858 CGW_SGWSts 0 "Sleep" 1 "Wake up" ;
VAL_ 858 CGW_CGWSts 0 "Sleep" 1 "Wake up" ;
VAL_ 858 CGW_CBMSts 0 "Sleep" 1 "Wake up" ;
VAL_ 858 CGW_DCM_FLSts 0 "Sleep" 1 "Wake up" ;
VAL_ 858 CGW_DCM_FRSts 0 "Sleep" 1 "Wake up" ;
VAL_ 858 CGW_DCM_RLSts 0 "Sleep" 1 "Wake up" ;
VAL_ 858 CGW_DCM_RRSts 0 "Sleep" 1 "Wake up" ;
VAL_ 858 CGW_SCU_LSts 0 "Sleep" 1 "Wake up" ;
VAL_ 858 CGW_SCU_RSts 0 "Sleep" 1 "Wake up" ;
VAL_ 858 CGW_HLRSts 0 "Sleep" 1 "Wake up" ;
VAL_ 858 CGW_HLLSts 0 "Sleep" 1 "Wake up" ;
VAL_ 858 CGW_MFP_RCSts 0 "Sleep" 1 "Wake up" ;
VAL_ 858 CGW_MFP_FCSts 0 "Sleep" 1 "Wake up" ;
VAL_ 858 CGW_IVISts 0 "Sleep" 1 "Wake up" ;
VAL_ 858 CGW_ADCUSts 0 "Sleep" 1 "Wake up" ;
VAL_ 858 CGW_VCUSts 0 "Sleep" 1 "Wake up" ;
VAL_ 858 CGW_BMSSts 0 "Sleep" 1 "Wake up" ;
VAL_ 858 CGW_BCMSts 0 "Sleep" 1 "Wake up" ;
VAL_ 858 CGW_SWPSts 0 "Sleep" 1 "Wake up" ;
VAL_ 858 CGW_HOD_HeatingSts 0 "Sleep" 1 "Wake up" ;
VAL_ 858 CGW_SwichesSts 0 "Sleep" 1 "Wake up" ;
VAL_ 858 CGW_PRNDSts 0 "Sleep" 1 "Wake up" ;
VAL_ 1352 TCU_RMR 0 "Repeat Message State not requested" 1 "Repeat Message State requested" ;
VAL_ 1352 TCU_AWB 0 "Node has not woken up the network (passive wakeup)" 1 "Node has woken up the network (active Wakeup)" ;
VAL_ 1358 AIRPTC_RMR 0 "Repeat Message State not requested" 1 "Repeat Message State requested" ;
VAL_ 1358 AIRPTC_AWB 0 "Node has not woken up the network (passive wakeup)" 1 "Node has woken up the network (active Wakeup)" ;
VAL_ 1353 EVCOM_RMR 0 "Repeat Message State not requested" 1 "Repeat Message State requested" ;
VAL_ 1353 EVCOM_AWB 0 "Node has not woken up the network (passive wakeup)" 1 "Node has woken up the network (active Wakeup)" ;
SIG_GROUP_ 580 POD_OBC_STATUS_02_SigGroup 1 : POD_OBC_ChrgOutpPwrAvl POD_OBC_OutputDCChargeCurrent POD_OBC_ACPortTempA POD_OBC_ACPortTempB POD_OBC_ACFrequencyStatus POD_OBC_OutputDCChargeVoltage;
SIG_GROUP_ 787 POD_OBC_STATUS_03_SigGroup 1 : POD_OBC_ACPortTempASensValid POD_OBC_ACPortTempBSensValid POD_OBC_ACPortTempAerror POD_OBC_ACPortTempBerror POD_OBC_FaultLevel POD_OBC_DCVoltHighFault POD_OBC_StartUpAllowed POD_OBC_CommunFault POD_OBC_DCCurHighFault POD_OBC_ACVoltHighFault POD_OBC_ACVoltLowFault POD_OBC_NlineStatus POD_OBC_OutputoverloadFault POD_OBC_InputFrequencyStatus POD_OBC_InputPhaseStatus POD_OBC_InputOverCurrentstatus_R POD_OBC_InputOverCurrentstatus_S POD_OBC_InputOverCurrentstatus_T POD_OBC_PFCUnderVoltageError POD_OBC_PFCOverVoltageError POD_OBC_OutputShortError POD_OBC_Side1Overtempfault POD_OBC_Side2Overtempfault POD_OBC_DCVoltLowFault POD_OBC_InternalFault POD_OBC_InputShortError POD_DCDC_CommunFault OBC_OutputIsolatedFault POD_OBC_PrimarySideTemp POD_OBC_SecondarySideTemp;
SIG_GROUP_ 585 POD_OBC_STATUS_04_SigGroup 1 : POD_OBC_InputACCurrent_R POD_OBC_InputACCurrent_S POD_OBC_InputACCurrent_T POD_OBC_InputACVoltage_R POD_OBC_InputACVoltage_S POD_OBC_InputACVoltage_T;
SIG_GROUP_ 576 POD_Status_01_SigGroup 1 : POD_DCFCVoltage POD_Temperature POD_DCInletTempA POD_DCInletTempB;
SIG_GROUP_ 577 POD_Status_02_SigGroup 1 : POD_KL30Error POD_DCPosRelayState POD_DCPortInletTempAValid POD_DCPortInletTempBValid POD_T15e_fault POD_CANBusoff POD_TempHighFault POD_TempSensor1Fault;
SIG_GROUP_ 584 PRND_SigGroup 1 : Checksum_248 PRND_RNDbutton MessageCounter_248 PRND_Pbutton PRND_Pbutton_FaultSts PRND_RNDbutton_FaultSts;
SIG_GROUP_ 572 SGW_01_SigGroup 1 : SGW_TimingChargeSwitchStatus SGW_RemoteChrgFlapLockCtrlReq SGW_RelockSet SGW_RemoteActiveHorn SGW_ChargeFormSet SGW_TimingChargefrquency SGW_AppointChargeCmd SGW_DschrgOnOffSet SGW_LockACPlug SGW_HoodlockSet;
SIG_GROUP_ 565 SGW_04_SigGroup 1 : SGW_AlarmEnableSet SGW_ALM_MusicFrequencySet SGW_RemoteHVCtrlReq SGW_FL_BackrestMotorReq SGW_DomeLampBrightSet SGW_FL_FrontRearReq SGW_FL_HeightMotorReq SGW_WelLightshowOnOffSet SGW_WelLightshowTimeSet SGW_TaxiArrIllReq SGW_FollowMeHomeTimeSet SGW_TaxiArriveSts SGW_BookingCarReq SGW_HazardWarnReq SGW_FollowMeHomeSet;
SIG_GROUP_ 571 SGW_12_SigGroup 1 : SGW_TimingChargeEndhour SGW_TimingChargeEndminute SGW_TimingChargeStarthour SGW_TimingChargeStartminute;
SIG_GROUP_ 692 SGW_16_SigGroup 1 : IVI_MirrorInterfaceMode IVI_VrState IVI_WCBSReminderSet;
SIG_GROUP_ 960 SGW_FVSynchronization_01_SigGrou 1 : SGW_TripCounter SGW_ResetCounter SGW_SynMsgAuthenticator;
SIG_GROUP_ 561 SGW_IBS_01_SigGroup 1 : IVI_ESCOffSet IVI_TPMS_Reset IVI_HDCOffSet IVI_AVHSet IVI_SteeringModeSet IVI_BrakeCompensateCmd IVI_CRLevelSet;
SIG_GROUP_ 944 IVI_OdometerInfor_SigGroup 1 : IVI_OdometerInfor IVI_OdometerInforValid;
SIG_GROUP_ 693 SGW_PT_01_SigGroup 1 : IVI_AppointChargeCmd IVI_ForwardVmaxlimitSw IVI_KeepWarmRequest IVI_LockACPlug IVI_LV_LimitPop;
SIG_GROUP_ 694 IVI_01_SigGroup 1 : IVI_GearRequest;
SIG_GROUP_ 261 SGW_RemoteCmd_01_SigGroup 1 : SGW_RemoteAirCondOnOFFReq SGW_RemoteAirCondAUTOReq SGW_RemoteFrontDefrostReq SGW_FrontDoorAngleSet SGW_RearDoorAngleSet SGW_LeftChdLockCtrlReq SGW_RemoteDrSeatHeatReq SGW_RemoteSteerHeatReq SGW_RemotePassSeatHeatReq SGW_RemoteRearMirHeatReq SGW_RemoteFrontWindHeatReq SGW_RearDefrostCtrlSet SGW_RemoteRearWindHeatReq SGW_oneTouchCoolSet SGW_TakePicCtrl SGW_RemoteTailgateLockCtrlReq SGW_RightChdLockCtrlReq SGW_RemoteACOnOffReq;
SIG_GROUP_ 263 SGW_RemoteCmd_03_SigGroup 1 : SGW_RemoteDrvSetTempSteplsReq SGW_RemotePassSetTempSteplsReq SGW_RemoteCarSearchReq SGW_AllDoorReq SGW_FLDoorReq SGW_FRDoorReq SGW_RLDoorReq SGW_RRDoorReq SGW_FLWinPosiCtlCmd SGW_FRWinPosiCtlCmd SGW_RLWinPosiCtlCmd SGW_RRWinPosiCtlCmd;
SIG_GROUP_ 562 SGW_TCU_01_SigGroup 1 : SGW_DrvSetTempSteplsReq SGW_DemistReq SGW_HVACBatterySaveModeSetReq SGW_PassSetTempSteplsReq SGW_AirCondAUTOReq SGW_DualReq SGW_AirDistributionModeReq SGW_FrontDefrostReq SGW_AqsReq SGW_ClimateSystemStsReq SGW_ACCmprStsReq SGW_AirCirclnReq SGW_BlowersteplsSpdReq SGW_PresetModeEnable SGW_PresetModeReq SGW_VentilationModeReq SGW_AirCondEcoSet;
SIG_GROUP_ 564 SGW_Time_SigGroup 1 : SGW_TimeInfoSecond SGW_TimeInfoMinute SGW_TimeInfoHour SGW_TimeInfoDay SGW_TimeInfoMonth SGW_TimeInfoYear SGW_TimeValid;
SIG_GROUP_ 560 SGW_VCU_01_SigGroup 1 : IVI_DschrgOnOffSet IVI_DriveModeSet IVI_ForwardVmaxAllowed IVI_MaxChrgSocSet IVI_V2LidisSet;
SIG_GROUP_ 608 TCU_01_SigGroup 1 : TCU_TMSTotalPwrCnsmp TCU_EVCompState TCU_TMSState TCU_TMSFaultLevel TCU_HvOnReq TCU_HVCHState TCU_APTCState TCU_TMSTotoalPwrReq TCU_BattTMState TCU_HVPwrState TCU_HVACACState TCU_APTCLeftMaxPowerLimit TCU_APTCRightMaxPowerLimit;
SIG_GROUP_ 609 TCU_02_SigGroup 1 : TCU_HVCHHighVoltage TCU_APTCLeftCmd TCU_APTCRightCmd TCU_CompTargetSpeed TCU_APTC1Enable TCU_CompEnable TCU_CompMaxAllowPwrCmsp TCU_HVCHHVDCCurrent;
SIG_GROUP_ 610 TCU_03_SigGroup 1 : TCU_CabinTemperature TCU_CabinTemperatureValid;
SIG_GROUP_ 768 TCU_IVI_SigGroup 1 : TCU_AirCirclnSts TCU_AirCondAUTOSts TCU_FrontDefrostSts TCU_DrvTempSts TCU_SelfDryingSetSts TCU_AirCondEcoSetSts TCU_PassTempSts TCU_DualSts TCU_AqsSts TCU_BlowerSpdSts TCU_FreonLowWarnReq TCU_CoolantLowWarnReq TCU_AirDistributionModeSts TCU_PresetModeSts TCU_VentilationModeSts TCU_OutsideAQSLevel TCU_PowerLimitSts TCU_ClimateSystemSts TCU_ACCmprSts TCU_HVACBatterySaveModeSetSts TCU_HVACBatterySaveSts TCU_DemistSts TCU_WindowClosRemind;
SIG_GROUP_ 793 VCU_02_SigGroup 1 : VCU_BS_IBSBatSOC VCU_BS_Current VCU_BS_IndicatorSts VCU_BS_LV_Batt VCU_WakeUpStatus;
SIG_GROUP_ 548 VCU_05_SigGroup 1 : VCU_MaximumOutputCurrent VCU_MaximumOutputVoltage VCU_MinimumOutputCurrent VCU_MinimumOutputVoltage;
SIG_GROUP_ 549 VCU_06_SigGroup 1 : VCU_DisChgPowerLimit VCU_PermitPackPTC VCU_ChargeTime VCU_DisplayMileage VCU_MCUPower VCU_ChargeEnergy;
SIG_GROUP_ 210 VCU_AccPedal_SigGroup 1 : Checksum_0D2 VCU_VehicleSpeedValid VCU_EPBReq MessageCounter_0D2 VCU_AccelerationPedal VCU_AccelerationPedalValid VCU_VirtualACPedalValid VCU_VirtualACPedal VCU_TargetGear VCU_VehicleSpeed VCU_VLCTorqueRequestAvailable VCU_VLCTorqueRequestActive VCU_Kickdown;
SIG_GROUP_ 209 VCU_BMS_SigGroup 1 : Checksum_0D1 VCU_IsoMeasurementSwitch MessageCounter_0D1 VCU_RequestedModeBMS VCU_HVStatus VCU_ChargeStatus VCU_LimitLevel VCU_ActDriveMode VCU_DrvModSwitchWarn VCU_RegenBrakeLightReqVld VCU_RegenBrakeLightRequest VCU_BMSTargetThermLevel VCU_BMS_Control_of_PosRelay;
SIG_GROUP_ 544 VCU_DCDC_SigGroup 1 : VCU_VoltageDemandLV VCU_RequestedModeDCDC VCU_DCDCPowerLimit;
SIG_GROUP_ 792 VCU_HMIsignals_02_SigGroup 1 : Checksum_318 VCU_MCU_FaultLampReq MessageCounter_318 VCU_Display_Power VCU_SystemReady VCU_Display_Cur VCU_maxChargeSOC VCU_DischargeEndSoc VCU_ForwardVmaxAllowed;
SIG_GROUP_ 795 VCU_HMIsignals_03_SigGroup 1 : VCU_BS_QuiescentCurrent VCU_BS_HCurrent VCU_Display_voltage;
SIG_GROUP_ 150 VCU_MCU_02_SigGroup 1 : VCU_MotorSpdReq VCU_MaxSpdLimit VCU_MCUActHeatPwr;
SIG_GROUP_ 149 VCU_MCU_03_SigGroup 1 : Checksum_095 VCU_PWTErrorLevel MessageCounter_095 VCU_MCUDesiredTorque VCU_KL15eOn VCU_TCSActive VCU_MCUSurgeDamperState VCU_ActualGear VCU_BrakepedalStatus VCU_RequestedModeMCU VCU_TrqThresholdDampgCtl;
SIG_GROUP_ 214 VCU_MCU_05_SigGroup 1 : VCU_MaxTorqueGradient VCU_MinTorqueLimit VCU_MaxTorqueLimit VCU_CreepTorque VCU_SpdLimitActTorque;
SIG_GROUP_ 289 VCU_POD_SigGroup 1 : VCU_Enable_DC_Relay VCU_OBC_Control_of_S2_SW VCU_OBC_Control_of_em_lock VCU_EnableOBC VCU_OBC_ChargeCurrentCommand;
SIG_GROUP_ 545 VCU_TCU_SigGroup 1 : VCU_RequestedModeTCU VCU_TCUPowerAllowed;
SIG_GROUP_ 319 VCU_SynReq_01_SigGroup 1 : VCU_SynRequest;
SIG_GROUP_ 896 CGW_VIN1_SigGroup 1 : CGW_VIN0 CGW_VIN1 CGW_VIN2 CGW_VIN3 CGW_VIN4 CGW_VIN5 CGW_VIN6 CGW_VIN7;
SIG_GROUP_ 897 CGW_VIN2_SigGroup 1 : CGW_VIN8 CGW_VIN9 CGW_VIN10 CGW_VIN11 CGW_VIN12 CGW_VIN13 CGW_VIN14 CGW_VIN15;
SIG_GROUP_ 898 CGW_VIN3VER_SigGroup 1 : CGW_VIN16 CGW_VERSION1 CGW_VERSION2;
SIG_GROUP_ 858 CGW_02_SigGroup 1 : CGW_SCU_LSts CGW_DCM_RRSts CGW_DCM_RLSts CGW_DCM_FRSts CGW_DCM_FLSts CGW_CBMSts CGW_CGWSts CGW_SGWSts CGW_VCUSts CGW_ADCUSts CGW_IVISts CGW_MFP_FCSts CGW_MFP_RCSts CGW_HLLSts CGW_HLRSts CGW_SCU_RSts CGW_PRNDSts CGW_SwichesSts CGW_HOD_HeatingSts CGW_SWPSts CGW_BCMSts CGW_BMSSts;
SIG_GROUP_ 1353 NM_EVCOM_SigGroup 1 : EVCOM_AWB EVCOM_RMR;
SIG_GROUP_ 2047 DiagReq_ALL_SigGroup 1 : ALL_DiagReq;
SIG_GROUP_ 2015 DiagReq_FUN_SigGroup 1 : FUN_DiagReq;
SIG_GROUP_ 1843 DiagReq_OBD_SigGroup 1 : OBD_DiagReq;
SIG_GROUP_ 2016 DiagReq_VCU_OBD_SigGroup 1 : VCU_OBD_DiagReq;
SIG_GROUP_ 2024 DiagResp_VCU_OBD_SigGroup 1 : VCU_OBD_DiagResp;
SIG_GROUP_ 2026 DiagReq_PT_SigGroup 1 : PT_DiagReq;
SIG_GROUP_ 1991 DiagReq_POD_SigGroup 1 : POD_DiagReq;
SIG_GROUP_ 1939 DiagReq_BMS_SigGroup 1 : BMS_DiagReq;
SIG_GROUP_ 1992 DiagReq_TCU_SigGroup 1 : TCU_DiagReq;
SIG_GROUP_ 1998 DiagReq_AIRPTC_SigGroup 1 : AIRPTC_DiagReq;
SIG_GROUP_ 1964 DiagReq_VCU_SigGroup 1 : VCU_DiagReq;
SIG_GROUP_ 1986 DiagReq_MCU_SigGroup 1 : MCU_DiagReq;
SIG_GROUP_ 1999 DiagReq_PRND_SigGroup 1 : PRND_DiagReq;
SIG_GROUP_ 1993 DiagReq_EVCOM_SigGroup 1 : EVCOM_DiagReq;
SIG_GROUP_ 1863 DiagResp_POD_SigGroup 1 : POD_DiagResp;
SIG_GROUP_ 1811 DiagResp_BMS_SigGroup 1 : BMS_DiagResp;
SIG_GROUP_ 1864 DiagResp_TCU_SigGroup 1 : TCU_DiagResp;
SIG_GROUP_ 1870 DiagResp_APTC_SigGroup 1 : AIRPTC_DiagResp;
SIG_GROUP_ 1836 DiagResp_VCU_SigGroup 1 : VCU_DiagResp;
SIG_GROUP_ 1858 DiagResp_MCU_SigGroup 1 : MCU_DiagResp;
SIG_GROUP_ 1871 DiagResp_PRND_SigGroup 1 : PRND_DiagResp;
SIG_GROUP_ 1865 DiagResp_EVCOM_SigGroup 1 : EVCOM_DiagResp;
SIG_GROUP_ 1095 POD_DiagInfor_SigGroup 1 : POD_DTC_Number;
SIG_GROUP_ 1043 BMS_DiagInfor_SigGroup 1 : BMS_DTC_Number;
SIG_GROUP_ 1096 TCU_DiagInfor_SigGroup 1 : TCU_DTC_Number;
SIG_GROUP_ 1102 APTC_DiagInfor_SigGroup 1 : AIRPTC_DTC_Number;
SIG_GROUP_ 1068 VCU_DiagInfor_SigGroup 1 : VCU_DTC_Number;
SIG_GROUP_ 1090 MCU_DiagInfor_SigGroup 1 : MCU_DTC_Number;
SIG_GROUP_ 1103 PRND_DiagInfor_SigGroup 1 : PRND_DTC_Number;
SIG_GROUP_ 1097 EVCOM_DiagInfor_SigGroup 1 : EVCOM_DTC_Number;
SIG_GROUP_ 947 MCU_Fault_01_SigGroup 1 : MCU_FaultNum1 MCU_FaultNum2 MCU_FaultNum3 MCU_FaultNum4 MCU_FaultNum5 MCU_FaultNum6 MCU_FaultNum7 MCU_FaultNum8;
SIG_GROUP_ 948 MCU_Fault_02_SigGroup 1 : MCU_FaultNum9 MCU_FaultNum10 MCU_TotalFaultNum;
